VERSION "TTR CAN DBC Tool"

NS_ :

BS_:

BU_: AMS CHARGER DEBUG IMU_FRONT MCU1 MCU2 MCU3 MCU4 VCU

BO_ 32 VCU_MCU_ALL_CONTROL: 12 VCU
 SG_ SYS_EN_CMD : 0|1@1+ (1,0) [0|0] "" MCU1,MCU2,MCU3,MCU4
 SG_ SYS_RESET_CMD : 1|1@1+ (1,0) [0|0] "" MCU1,MCU2,MCU3,MCU4
 SG_ FW_EN_CMD : 2|1@1+ (1,0) [0|0] "" MCU1,MCU2,MCU3,MCU4
 SG_ MTPA_EN_CMD : 3|1@1+ (1,0) [0|0] "" MCU1,MCU2,MCU3,MCU4
 SG_ TE_CMD_MCU1_CMD : 16|16@1+ (0.0488759,-25) [-25|25] "Nm" MCU1,MCU2,MCU3,MCU4
 SG_ TE_CMD_MCU2_CMD : 32|16@1+ (0.0488759,-25) [-25|25] "Nm" MCU1,MCU2,MCU3,MCU4
 SG_ TE_CMD_MCU3_CMD : 48|16@1+ (0.0488759,-25) [-25|25] "Nm" MCU1,MCU2,MCU3,MCU4
 SG_ TE_CMD_MCU4_CMD : 64|16@1+ (0.0488759,-25) [-25|25] "Nm" MCU1,MCU2,MCU3,MCU4
 SG_ CMD_COUNTER : 80|16@1+ (1,0) [0|0] "" MCU1,MCU2,MCU3,MCU4

BO_ 96 CHARGER_AMS_CONTROL: 8 CHARGER
 SG_ BALANCE_EN : 0|1@1+ (1,0) [0|0] "" AMS

BO_ 192 MCU1_STATUS_CORE: 8 MCU1
 SG_ SPEED_FB : 0|16@1+ (0.762951,-25000) [-25000|25000] "RPM" VCU
 SG_ ID_FB : 16|16@1+ (0.00610361,-200) [-200|200] "A" VCU
 SG_ IQ_FB : 32|16@1+ (0.00610361,-200) [-200|200] "A" VCU
 SG_ SYS_READY_ACTIVE : 48|1@1+ (1,0) [0|0] "" VCU
 SG_ SYS_ENABLE_ACTIVE : 49|1@1+ (1,0) [0|0] "" VCU
 SG_ SYS_ACTIVE : 50|1@1+ (1,0) [0|0] "" VCU
 SG_ SYS_LIMIT_ACTIVE : 51|1@1+ (1,0) [0|0] "" VCU
 SG_ FW_ACTIVE : 52|1@1+ (1,0) [0|0] "" VCU
 SG_ RECV_CTRL_CMD_ACTIVE : 53|1@1+ (1,0) [0|0] "" VCU
 SG_ ASC_ACTIVE : 54|1@1+ (1,0) [0|0] "" VCU
 SG_ SYS_FAULT : 56|1@1+ (1,0) [0|0] "" VCU
 SG_ VOLTAGE_SAT_ACTIVE : 57|1@1+ (1,0) [0|0] "" VCU
 SG_ U_OCP_FAULT : 58|1@1+ (1,0) [0|0] "" VCU
 SG_ V_OCP_FAULT : 59|1@1+ (1,0) [0|0] "" VCU
 SG_ W_OCP_FAULT : 60|1@1+ (1,0) [0|0] "" VCU
 SG_ U_GATE_FAULT : 61|1@1+ (1,0) [0|0] "" VCU
 SG_ V_GATE_FAULT : 62|1@1+ (1,0) [0|0] "" VCU
 SG_ W_GATE_FAULT : 63|1@1+ (1,0) [0|0] "" VCU

BO_ 224 MCU2_STATUS_CORE: 8 MCU2
 SG_ SPEED_FB : 0|16@1+ (0.762951,-25000) [-25000|25000] "RPM" VCU
 SG_ ID_FB : 16|16@1+ (0.00610361,-200) [-200|200] "A" VCU
 SG_ IQ_FB : 32|16@1+ (0.00610361,-200) [-200|200] "A" VCU
 SG_ SYS_READY_ACTIVE : 48|1@1+ (1,0) [0|0] "" VCU
 SG_ SYS_ENABLE_ACTIVE : 49|1@1+ (1,0) [0|0] "" VCU
 SG_ SYS_ACTIVE : 50|1@1+ (1,0) [0|0] "" VCU
 SG_ SYS_LIMIT_ACTIVE : 51|1@1+ (1,0) [0|0] "" VCU
 SG_ FW_ACTIVE : 52|1@1+ (1,0) [0|0] "" VCU
 SG_ RECV_CTRL_CMD_ACTIVE : 53|1@1+ (1,0) [0|0] "" VCU
 SG_ ASC_ACTIVE : 54|1@1+ (1,0) [0|0] "" VCU
 SG_ SYS_FAULT : 56|1@1+ (1,0) [0|0] "" VCU
 SG_ VOLTAGE_SAT_ACTIVE : 57|1@1+ (1,0) [0|0] "" VCU
 SG_ U_OCP_FAULT : 58|1@1+ (1,0) [0|0] "" VCU
 SG_ V_OCP_FAULT : 59|1@1+ (1,0) [0|0] "" VCU
 SG_ W_OCP_FAULT : 60|1@1+ (1,0) [0|0] "" VCU
 SG_ U_GATE_FAULT : 61|1@1+ (1,0) [0|0] "" VCU
 SG_ V_GATE_FAULT : 62|1@1+ (1,0) [0|0] "" VCU
 SG_ W_GATE_FAULT : 63|1@1+ (1,0) [0|0] "" VCU

BO_ 256 MCU3_STATUS_CORE: 8 MCU3
 SG_ SPEED_FB : 0|16@1+ (0.762951,-25000) [-25000|25000] "RPM" VCU
 SG_ ID_FB : 16|16@1+ (0.00610361,-200) [-200|200] "A" VCU
 SG_ IQ_FB : 32|16@1+ (0.00610361,-200) [-200|200] "A" VCU
 SG_ SYS_READY_ACTIVE : 48|1@1+ (1,0) [0|0] "" VCU
 SG_ SYS_ENABLE_ACTIVE : 49|1@1+ (1,0) [0|0] "" VCU
 SG_ SYS_ACTIVE : 50|1@1+ (1,0) [0|0] "" VCU
 SG_ SYS_LIMIT_ACTIVE : 51|1@1+ (1,0) [0|0] "" VCU
 SG_ FW_ACTIVE : 52|1@1+ (1,0) [0|0] "" VCU
 SG_ RECV_CTRL_CMD_ACTIVE : 53|1@1+ (1,0) [0|0] "" VCU
 SG_ ASC_ACTIVE : 54|1@1+ (1,0) [0|0] "" VCU
 SG_ SYS_FAULT : 56|1@1+ (1,0) [0|0] "" VCU
 SG_ VOLTAGE_SAT_ACTIVE : 57|1@1+ (1,0) [0|0] "" VCU
 SG_ U_OCP_FAULT : 58|1@1+ (1,0) [0|0] "" VCU
 SG_ V_OCP_FAULT : 59|1@1+ (1,0) [0|0] "" VCU
 SG_ W_OCP_FAULT : 60|1@1+ (1,0) [0|0] "" VCU
 SG_ U_GATE_FAULT : 61|1@1+ (1,0) [0|0] "" VCU
 SG_ V_GATE_FAULT : 62|1@1+ (1,0) [0|0] "" VCU
 SG_ W_GATE_FAULT : 63|1@1+ (1,0) [0|0] "" VCU

BO_ 288 MCU4_STATUS_CORE: 8 MCU4
 SG_ SPEED_FB : 0|16@1+ (0.762951,-25000) [-25000|25000] "RPM" VCU
 SG_ ID_FB : 16|16@1+ (0.00610361,-200) [-200|200] "A" VCU
 SG_ IQ_FB : 32|16@1+ (0.00610361,-200) [-200|200] "A" VCU
 SG_ SYS_READY_ACTIVE : 48|1@1+ (1,0) [0|0] "" VCU
 SG_ SYS_ENABLE_ACTIVE : 49|1@1+ (1,0) [0|0] "" VCU
 SG_ SYS_ACTIVE : 50|1@1+ (1,0) [0|0] "" VCU
 SG_ SYS_LIMIT_ACTIVE : 51|1@1+ (1,0) [0|0] "" VCU
 SG_ FW_ACTIVE : 52|1@1+ (1,0) [0|0] "" VCU
 SG_ RECV_CTRL_CMD_ACTIVE : 53|1@1+ (1,0) [0|0] "" VCU
 SG_ ASC_ACTIVE : 54|1@1+ (1,0) [0|0] "" VCU
 SG_ SYS_FAULT : 56|1@1+ (1,0) [0|0] "" VCU
 SG_ VOLTAGE_SAT_ACTIVE : 57|1@1+ (1,0) [0|0] "" VCU
 SG_ U_OCP_FAULT : 58|1@1+ (1,0) [0|0] "" VCU
 SG_ V_OCP_FAULT : 59|1@1+ (1,0) [0|0] "" VCU
 SG_ W_OCP_FAULT : 60|1@1+ (1,0) [0|0] "" VCU
 SG_ U_GATE_FAULT : 61|1@1+ (1,0) [0|0] "" VCU
 SG_ V_GATE_FAULT : 62|1@1+ (1,0) [0|0] "" VCU
 SG_ W_GATE_FAULT : 63|1@1+ (1,0) [0|0] "" VCU

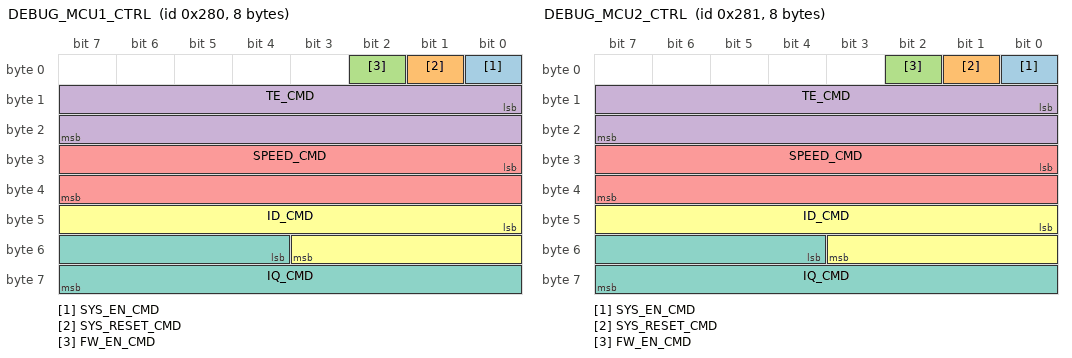
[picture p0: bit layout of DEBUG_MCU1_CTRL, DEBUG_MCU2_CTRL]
BO_ 640 DEBUG_MCU1_CTRL: 8 DEBUG
 SG_ SYS_EN_CMD : 0|1@1+ (1,0) [0|0] "" MCU1
 SG_ SYS_RESET_CMD : 1|1@1+ (1,0) [0|0] "" MCU1
 SG_ FW_EN_CMD : 2|1@1+ (1,0) [0|0] "" MCU1
 SG_ TE_CMD : 8|16@1+ (0.0488759,-25) [-25|25] "Nm" MCU1
 SG_ SPEED_CMD : 24|16@1+ (0.610361,-20000) [-20000|20000] "RPM" MCU1
 SG_ ID_CMD : 40|12@1+ (0.0976801,-200) [-200|200] "A" MCU1
 SG_ IQ_CMD : 52|12@1+ (0.0976801,-200) [-200|200] "A" MCU1

BO_ 641 DEBUG_MCU2_CTRL: 8 DEBUG
 SG_ SYS_EN_CMD : 0|1@1+ (1,0) [0|0] "" MCU2
 SG_ SYS_RESET_CMD : 1|1@1+ (1,0) [0|0] "" MCU2
 SG_ FW_EN_CMD : 2|1@1+ (1,0) [0|0] "" MCU2
 SG_ TE_CMD : 8|16@1+ (0.0488759,-25) [-25|25] "Nm" MCU2
 SG_ SPEED_CMD : 24|16@1+ (0.610361,-20000) [-20000|20000] "RPM" MCU2
 SG_ ID_CMD : 40|12@1+ (0.0976801,-200) [-200|200] "A" MCU2
 SG_ IQ_CMD : 52|12@1+ (0.0976801,-200) [-200|200] "A" MCU2

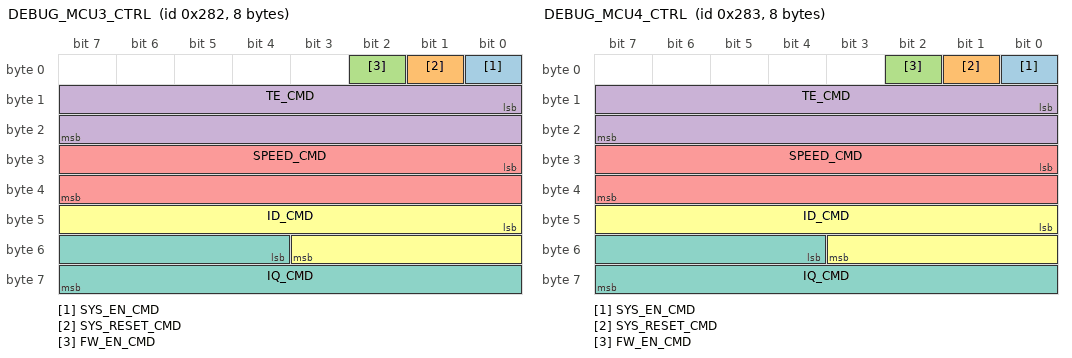
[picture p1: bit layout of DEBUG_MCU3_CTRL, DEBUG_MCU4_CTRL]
BO_ 642 DEBUG_MCU3_CTRL: 8 DEBUG
 SG_ SYS_EN_CMD : 0|1@1+ (1,0) [0|0] "" MCU3
 SG_ SYS_RESET_CMD : 1|1@1+ (1,0) [0|0] "" MCU3
 SG_ FW_EN_CMD : 2|1@1+ (1,0) [0|0] "" MCU3
 SG_ TE_CMD : 8|16@1+ (0.0488759,-25) [-25|25] "Nm" MCU3
 SG_ SPEED_CMD : 24|16@1+ (0.610361,-20000) [-20000|20000] "RPM" MCU3
 SG_ ID_CMD : 40|12@1+ (0.0976801,-200) [-200|200] "A" MCU3
 SG_ IQ_CMD : 52|12@1+ (0.0976801,-200) [-200|200] "A" MCU3

BO_ 643 DEBUG_MCU4_CTRL: 8 DEBUG
 SG_ SYS_EN_CMD : 0|1@1+ (1,0) [0|0] "" MCU4
 SG_ SYS_RESET_CMD : 1|1@1+ (1,0) [0|0] "" MCU4
 SG_ FW_EN_CMD : 2|1@1+ (1,0) [0|0] "" MCU4
 SG_ TE_CMD : 8|16@1+ (0.0488759,-25) [-25|25] "Nm" MCU4
 SG_ SPEED_CMD : 24|16@1+ (0.610361,-20000) [-20000|20000] "RPM" MCU4
 SG_ ID_CMD : 40|12@1+ (0.0976801,-200) [-200|200] "A" MCU4
 SG_ IQ_CMD : 52|12@1+ (0.0976801,-200) [-200|200] "A" MCU4

BO_ 644 DEBUG_MCU1_PARAMETER_CONTROL: 48 DEBUG
 SG_ DIRECTION : 0|1@1+ (1,0) [0|0] "" MCU1
 SG_ MODE : 1|2@1+ (1,0) [0|0] "" MCU1
 SG_ CUR_LOOP_ID_KP : 32|32@1- (1,0) [0|0] "" MCU1
 SG_ CUR_LOOP_ID_KI : 64|32@1- (1,0) [0|0] "" MCU1
 SG_ CUR_LOOP_IQ_KP : 96|32@1- (1,0) [0|0] "" MCU1
 SG_ CUR_LOOP_IQ_KI : 128|32@1- (1,0) [0|0] "" MCU1
 SG_ SPD_LOOP_KP : 160|32@1- (1,0) [0|0] "" MCU1
 SG_ SPD_LOOP_KI : 192|32@1- (1,0) [0|0] "" MCU1
 SG_ FW_KI : 224|32@1- (1,0) [0|0] "" MCU1

BO_ 645 DEBUG_MCU2_PARAMETER_CONTROL: 48 DEBUG
 SG_ DIRECTION : 0|1@1+ (1,0) [0|0] "" MCU2
 SG_ MODE : 1|2@1+ (1,0) [0|0] "" MCU2
 SG_ CUR_LOOP_ID_KP : 32|32@1- (1,0) [0|0] "" MCU2
 SG_ CUR_LOOP_ID_KI : 64|32@1- (1,0) [0|0] "" MCU2
 SG_ CUR_LOOP_IQ_KP : 96|32@1- (1,0) [0|0] "" MCU2
 SG_ CUR_LOOP_IQ_KI : 128|32@1- (1,0) [0|0] "" MCU2
 SG_ SPD_LOOP_KP : 160|32@1- (1,0) [0|0] "" MCU2
 SG_ SPD_LOOP_KI : 192|32@1- (1,0) [0|0] "" MCU2
 SG_ FW_KI : 224|32@1- (1,0) [0|0] "" MCU2

BO_ 646 DEBUG_MCU3_PARAMETER_CONTROL: 48 DEBUG
 SG_ DIRECTION : 0|1@1+ (1,0) [0|0] "" MCU3
 SG_ MODE : 1|2@1+ (1,0) [0|0] "" MCU3
 SG_ CUR_LOOP_ID_KP : 32|32@1- (1,0) [0|0] "" MCU3
 SG_ CUR_LOOP_ID_KI : 64|32@1- (1,0) [0|0] "" MCU3
 SG_ CUR_LOOP_IQ_KP : 96|32@1- (1,0) [0|0] "" MCU3
 SG_ CUR_LOOP_IQ_KI : 128|32@1- (1,0) [0|0] "" MCU3
 SG_ SPD_LOOP_KP : 160|32@1- (1,0) [0|0] "" MCU3
 SG_ SPD_LOOP_KI : 192|32@1- (1,0) [0|0] "" MCU3
 SG_ FW_KI : 224|32@1- (1,0) [0|0] "" MCU3

BO_ 647 DEBUG_MCU4_PARAMETER_CONTROL: 48 DEBUG
 SG_ DIRECTION : 0|1@1+ (1,0) [0|0] "" MCU4
 SG_ MODE : 1|2@1+ (1,0) [0|0] "" MCU4
 SG_ CUR_LOOP_ID_KP : 32|32@1- (1,0) [0|0] "" MCU4
 SG_ CUR_LOOP_ID_KI : 64|32@1- (1,0) [0|0] "" MCU4
 SG_ CUR_LOOP_IQ_KP : 96|32@1- (1,0) [0|0] "" MCU4
 SG_ CUR_LOOP_IQ_KI : 128|32@1- (1,0) [0|0] "" MCU4
 SG_ SPD_LOOP_KP : 160|32@1- (1,0) [0|0] "" MCU4
 SG_ SPD_LOOP_KI : 192|32@1- (1,0) [0|0] "" MCU4
 SG_ FW_KI : 224|32@1- (1,0) [0|0] "" MCU4

BO_ 648 DEBUG_MCU1_PARAMETER_LIMIT: 48 DEBUG
 SG_ CURRENT_LINE_LIMIT : 0|32@1- (1,0) [0|0] "" MCU1
 SG_ CURRENT_ID_LIMIT : 32|32@1- (1,0) [0|0] "" MCU1
 SG_ FW_ID_LIMIT : 64|32@1- (1,0) [0|0] "" MCU1
 SG_ TORQUE_LIMIT : 96|32@1- (1,0) [0|0] "" MCU1
 SG_ OVER_VOLTAGE_LIMIT : 128|32@1- (1,0) [0|0] "" MCU1
 SG_ UNDER_VOLTAGE_LIMIT : 160|32@1- (1,0) [0|0] "" MCU1
 SG_ VDC_REGEN_BLOCK_SOFT : 192|32@1- (1,0) [0|0] "" MCU1
 SG_ VDC_REGEN_BLOCK_HARD : 224|32@1- (1,0) [0|0] "" MCU1
 SG_ MOTOR_TEMP_LIMIT : 256|32@1- (1,0) [0|0] "" MCU1
 SG_ GATE_TEMP_LIMIT : 288|32@1- (1,0) [0|0] "" MCU1
 SG_ VQ_LIMIT : 320|32@1- (1,0) [0|0] "" MCU1
 SG_ MODULATION_LIMIT : 352|32@1- (1,0) [0|0] "" MCU1

BO_ 649 DEBUG_MCU2_PARAMETER_LIMIT: 48 DEBUG
 SG_ CURRENT_LINE_LIMIT : 0|32@1- (1,0) [0|0] "" MCU2
 SG_ CURRENT_ID_LIMIT : 32|32@1- (1,0) [0|0] "" MCU2
 SG_ FW_ID_LIMIT : 64|32@1- (1,0) [0|0] "" MCU2
 SG_ TORQUE_LIMIT : 96|32@1- (1,0) [0|0] "" MCU2
 SG_ OVER_VOLTAGE_LIMIT : 128|32@1- (1,0) [0|0] "" MCU2
 SG_ UNDER_VOLTAGE_LIMIT : 160|32@1- (1,0) [0|0] "" MCU2
 SG_ VDC_REGEN_BLOCK_SOFT : 192|32@1- (1,0) [0|0] "" MCU2
 SG_ VDC_REGEN_BLOCK_HARD : 224|32@1- (1,0) [0|0] "" MCU2
 SG_ MOTOR_TEMP_LIMIT : 256|32@1- (1,0) [0|0] "" MCU2
 SG_ GATE_TEMP_LIMIT : 288|32@1- (1,0) [0|0] "" MCU2
 SG_ VQ_LIMIT : 320|32@1- (1,0) [0|0] "" MCU2
 SG_ MODULATION_LIMIT : 352|32@1- (1,0) [0|0] "" MCU2

BO_ 650 DEBUG_MCU3_PARAMETER_LIMIT: 48 DEBUG
 SG_ CURRENT_LINE_LIMIT : 0|32@1- (1,0) [0|0] "" MCU3
 SG_ CURRENT_ID_LIMIT : 32|32@1- (1,0) [0|0] "" MCU3
 SG_ FW_ID_LIMIT : 64|32@1- (1,0) [0|0] "" MCU3
 SG_ TORQUE_LIMIT : 96|32@1- (1,0) [0|0] "" MCU3
 SG_ OVER_VOLTAGE_LIMIT : 128|32@1- (1,0) [0|0] "" MCU3
 SG_ UNDER_VOLTAGE_LIMIT : 160|32@1- (1,0) [0|0] "" MCU3
 SG_ VDC_REGEN_BLOCK_SOFT : 192|32@1- (1,0) [0|0] "" MCU3
 SG_ VDC_REGEN_BLOCK_HARD : 224|32@1- (1,0) [0|0] "" MCU3
 SG_ MOTOR_TEMP_LIMIT : 256|32@1- (1,0) [0|0] "" MCU3
 SG_ GATE_TEMP_LIMIT : 288|32@1- (1,0) [0|0] "" MCU3
 SG_ VQ_LIMIT : 320|32@1- (1,0) [0|0] "" MCU3
 SG_ MODULATION_LIMIT : 352|32@1- (1,0) [0|0] "" MCU3

BO_ 651 DEBUG_MCU4_PARAMETER_LIMIT: 48 DEBUG
 SG_ CURRENT_LINE_LIMIT : 0|32@1- (1,0) [0|0] "" MCU4
 SG_ CURRENT_ID_LIMIT : 32|32@1- (1,0) [0|0] "" MCU4
 SG_ FW_ID_LIMIT : 64|32@1- (1,0) [0|0] "" MCU4
 SG_ TORQUE_LIMIT : 96|32@1- (1,0) [0|0] "" MCU4
 SG_ OVER_VOLTAGE_LIMIT : 128|32@1- (1,0) [0|0] "" MCU4
 SG_ UNDER_VOLTAGE_LIMIT : 160|32@1- (1,0) [0|0] "" MCU4
 SG_ VDC_REGEN_BLOCK_SOFT : 192|32@1- (1,0) [0|0] "" MCU4
 SG_ VDC_REGEN_BLOCK_HARD : 224|32@1- (1,0) [0|0] "" MCU4
 SG_ MOTOR_TEMP_LIMIT : 256|32@1- (1,0) [0|0] "" MCU4
 SG_ GATE_TEMP_LIMIT : 288|32@1- (1,0) [0|0] "" MCU4
 SG_ VQ_LIMIT : 320|32@1- (1,0) [0|0] "" MCU4
 SG_ MODULATION_LIMIT : 352|32@1- (1,0) [0|0] "" MCU4

BO_ 652 DEBUG_MCU1_PARAMETER_OFFSET: 48 DEBUG
 SG_ VDC_OFFSET : 0|32@1- (1,0) [0|0] "" MCU1
 SG_ MOTOR_TEMP_OFFSET : 32|32@1- (1,0) [0|0] "" MCU1
 SG_ U_PHASE_TEMP_OFFSET : 64|32@1- (1,0) [0|0] "" MCU1
 SG_ V_PHASE_TEMP_OFFSET : 96|32@1- (1,0) [0|0] "" MCU1
 SG_ W_PHASE_TEMP_OFFSET : 128|32@1- (1,0) [0|0] "" MCU1

BO_ 653 DEBUG_MCU2_PARAMETER_OFFSET: 48 DEBUG
 SG_ VDC_OFFSET : 0|32@1- (1,0) [0|0] "" MCU2
 SG_ MOTOR_TEMP_OFFSET : 32|32@1- (1,0) [0|0] "" MCU2
 SG_ U_PHASE_TEMP_OFFSET : 64|32@1- (1,0) [0|0] "" MCU2
 SG_ V_PHASE_TEMP_OFFSET : 96|32@1- (1,0) [0|0] "" MCU2
 SG_ W_PHASE_TEMP_OFFSET : 128|32@1- (1,0) [0|0] "" MCU2

BO_ 654 DEBUG_MCU3_PARAMETER_OFFSET: 48 DEBUG
 SG_ VDC_OFFSET : 0|32@1- (1,0) [0|0] "" MCU3
 SG_ MOTOR_TEMP_OFFSET : 32|32@1- (1,0) [0|0] "" MCU3
 SG_ U_PHASE_TEMP_OFFSET : 64|32@1- (1,0) [0|0] "" MCU3
 SG_ V_PHASE_TEMP_OFFSET : 96|32@1- (1,0) [0|0] "" MCU3
 SG_ W_PHASE_TEMP_OFFSET : 128|32@1- (1,0) [0|0] "" MCU3

BO_ 655 DEBUG_MCU4_PARAMETER_OFFSET: 48 DEBUG
 SG_ VDC_OFFSET : 0|32@1- (1,0) [0|0] "" MCU4
 SG_ MOTOR_TEMP_OFFSET : 32|32@1- (1,0) [0|0] "" MCU4
 SG_ U_PHASE_TEMP_OFFSET : 64|32@1- (1,0) [0|0] "" MCU4
 SG_ V_PHASE_TEMP_OFFSET : 96|32@1- (1,0) [0|0] "" MCU4
 SG_ W_PHASE_TEMP_OFFSET : 128|32@1- (1,0) [0|0] "" MCU4

BO_ 656 DEBUG_MCU1_PARAMETER_CTRL_CMD: 1 DEBUG
 SG_ SAVE_CMD : 0|1@1+ (1,0) [0|0] "" MCU1

BO_ 657 DEBUG_MCU2_PARAMETER_CTRL_CMD: 1 DEBUG
 SG_ SAVE_CMD : 0|1@1+ (1,0) [0|0] "" MCU2

BO_ 658 DEBUG_MCU3_PARAMETER_CTRL_CMD: 1 DEBUG
 SG_ SAVE_CMD : 0|1@1+ (1,0) [0|0] "" MCU3

BO_ 659 DEBUG_MCU4_PARAMETER_CTRL_CMD: 1 DEBUG
 SG_ SAVE_CMD : 0|1@1+ (1,0) [0|0] "" MCU4

BO_ 660 DEBUG_MCU1_PARAMETER_SLEW_RATE: 48 DEBUG
 SG_ TORQUE_SLEW_POS_NM_PER_S : 0|32@1- (1,0) [0|0] "" MCU1
 SG_ TORQUE_SLEW_NEG_NM_PER_S : 32|32@1- (1,0) [0|0] "" MCU1
 SG_ SPEED_SLEW_POS_RPM_PER_S : 64|32@1- (1,0) [0|0] "" MCU1
 SG_ SPEED_SLEW_NEG_RPM_PER_S : 96|32@1- (1,0) [0|0] "" MCU1
 SG_ ID_MTPA_ATTACK_SLEW_A_PER_S : 128|32@1- (1,0) [0|0] "" MCU1
 SG_ ID_MTPA_RELEASE_SLEW_A_PER_S : 160|32@1- (1,0) [0|0] "" MCU1
 SG_ ID_FW_ATTACK_SLEW_A_PER_S : 192|32@1- (1,0) [0|0] "" MCU1
 SG_ ID_FW_RELEASE_SLEW_A_PER_S : 224|32@1- (1,0) [0|0] "" MCU1

BO_ 661 DEBUG_MCU2_PARAMETER_SLEW_RATE: 48 DEBUG
 SG_ TORQUE_SLEW_POS_NM_PER_S : 0|32@1- (1,0) [0|0] "" MCU2
 SG_ TORQUE_SLEW_NEG_NM_PER_S : 32|32@1- (1,0) [0|0] "" MCU2
 SG_ SPEED_SLEW_POS_RPM_PER_S : 64|32@1- (1,0) [0|0] "" MCU2
 SG_ SPEED_SLEW_NEG_RPM_PER_S : 96|32@1- (1,0) [0|0] "" MCU2
 SG_ ID_MTPA_ATTACK_SLEW_A_PER_S : 128|32@1- (1,0) [0|0] "" MCU2
 SG_ ID_MTPA_RELEASE_SLEW_A_PER_S : 160|32@1- (1,0) [0|0] "" MCU2
 SG_ ID_FW_ATTACK_SLEW_A_PER_S : 192|32@1- (1,0) [0|0] "" MCU2
 SG_ ID_FW_RELEASE_SLEW_A_PER_S : 224|32@1- (1,0) [0|0] "" MCU2

BO_ 662 DEBUG_MCU3_PARAMETER_SLEW_RATE: 48 DEBUG
 SG_ TORQUE_SLEW_POS_NM_PER_S : 0|32@1- (1,0) [0|0] "" MCU3
 SG_ TORQUE_SLEW_NEG_NM_PER_S : 32|32@1- (1,0) [0|0] "" MCU3
 SG_ SPEED_SLEW_POS_RPM_PER_S : 64|32@1- (1,0) [0|0] "" MCU3
 SG_ SPEED_SLEW_NEG_RPM_PER_S : 96|32@1- (1,0) [0|0] "" MCU3
 SG_ ID_MTPA_ATTACK_SLEW_A_PER_S : 128|32@1- (1,0) [0|0] "" MCU3
 SG_ ID_MTPA_RELEASE_SLEW_A_PER_S : 160|32@1- (1,0) [0|0] "" MCU3
 SG_ ID_FW_ATTACK_SLEW_A_PER_S : 192|32@1- (1,0) [0|0] "" MCU3
 SG_ ID_FW_RELEASE_SLEW_A_PER_S : 224|32@1- (1,0) [0|0] "" MCU3

BO_ 663 DEBUG_MCU4_PARAMETER_SLEW_RATE: 48 DEBUG
 SG_ TORQUE_SLEW_POS_NM_PER_S : 0|32@1- (1,0) [0|0] "" MCU4
 SG_ TORQUE_SLEW_NEG_NM_PER_S : 32|32@1- (1,0) [0|0] "" MCU4
 SG_ SPEED_SLEW_POS_RPM_PER_S : 64|32@1- (1,0) [0|0] "" MCU4
 SG_ SPEED_SLEW_NEG_RPM_PER_S : 96|32@1- (1,0) [0|0] "" MCU4
 SG_ ID_MTPA_ATTACK_SLEW_A_PER_S : 128|32@1- (1,0) [0|0] "" MCU4
 SG_ ID_MTPA_RELEASE_SLEW_A_PER_S : 160|32@1- (1,0) [0|0] "" MCU4
 SG_ ID_FW_ATTACK_SLEW_A_PER_S : 192|32@1- (1,0) [0|0] "" MCU4
 SG_ ID_FW_RELEASE_SLEW_A_PER_S : 224|32@1- (1,0) [0|0] "" MCU4

BO_ 664 DEBUG_DTU_CONTROL: 8 DEBUG
 SG_ ENABLE_DEBUG : 0|1@1+ (1,0) [0|0] "" VCU

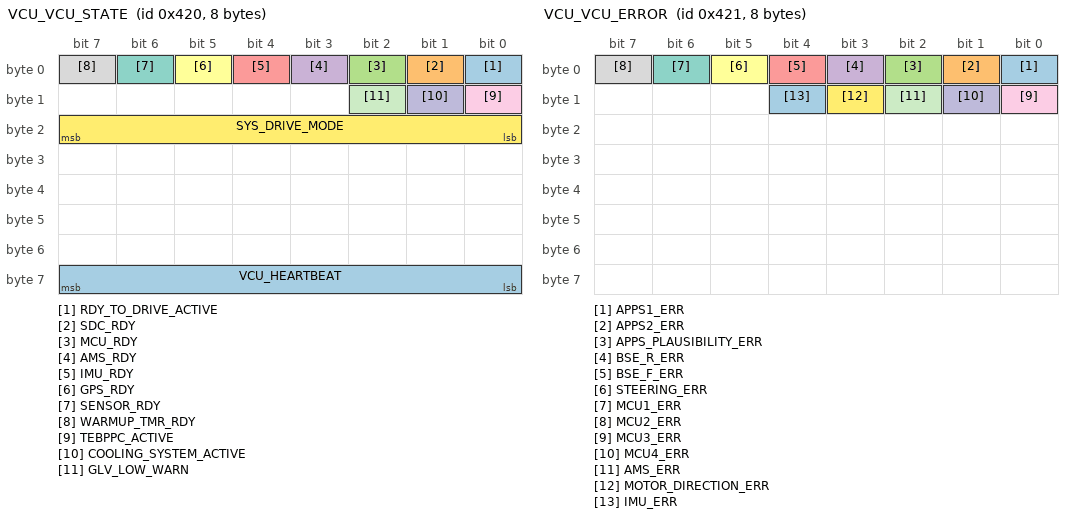
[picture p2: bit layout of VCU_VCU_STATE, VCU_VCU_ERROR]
BO_ 1056 VCU_VCU_STATE: 8 VCU
 SG_ RDY_TO_DRIVE_ACTIVE : 0|1@1+ (1,0) [0|0] "" Vector__XXX
 SG_ SDC_RDY : 1|1@1+ (1,0) [0|0] "" Vector__XXX
 SG_ MCU_RDY : 2|1@1+ (1,0) [0|0] "" Vector__XXX
 SG_ AMS_RDY : 3|1@1+ (1,0) [0|0] "" Vector__XXX
 SG_ IMU_RDY : 4|1@1+ (1,0) [0|0] "" Vector__XXX
 SG_ GPS_RDY : 5|1@1+ (1,0) [0|0] "" Vector__XXX
 SG_ SENSOR_RDY : 6|1@1+ (1,0) [0|0] "" Vector__XXX
 SG_ WARMUP_TMR_RDY : 7|1@1+ (1,0) [0|0] "" Vector__XXX
 SG_ TEBPPC_ACTIVE : 8|1@1+ (1,0) [0|0] "" Vector__XXX
 SG_ COOLING_SYSTEM_ACTIVE : 9|1@1+ (1,0) [0|0] "" Vector__XXX
 SG_ GLV_LOW_WARN : 10|1@1+ (1,0) [0|0] "" Vector__XXX
 SG_ SYS_DRIVE_MODE : 16|8@1+ (1,0) [0|0] "" Vector__XXX
 SG_ VCU_HEARTBEAT : 56|8@1+ (1,0) [0|0] "" Vector__XXX

BO_ 1057 VCU_VCU_ERROR: 8 VCU
 SG_ APPS1_ERR : 0|1@1+ (1,0) [0|0] "" Vector__XXX
 SG_ APPS2_ERR : 1|1@1+ (1,0) [0|0] "" Vector__XXX
 SG_ APPS_PLAUSIBILITY_ERR : 2|1@1+ (1,0) [0|0] "" Vector__XXX
 SG_ BSE_R_ERR : 3|1@1+ (1,0) [0|0] "" Vector__XXX
 SG_ BSE_F_ERR : 4|1@1+ (1,0) [0|0] "" Vector__XXX
 SG_ STEERING_ERR : 5|1@1+ (1,0) [0|0] "" Vector__XXX
 SG_ MCU1_ERR : 6|1@1+ (1,0) [0|0] "" Vector__XXX
 SG_ MCU2_ERR : 7|1@1+ (1,0) [0|0] "" Vector__XXX
 SG_ MCU3_ERR : 8|1@1+ (1,0) [0|0] "" Vector__XXX
 SG_ MCU4_ERR : 9|1@1+ (1,0) [0|0] "" Vector__XXX
 SG_ AMS_ERR : 10|1@1+ (1,0) [0|0] "" Vector__XXX
 SG_ MOTOR_DIRECTION_ERR : 11|1@1+ (1,0) [0|0] "" Vector__XXX
 SG_ IMU_ERR : 12|1@1+ (1,0) [0|0] "" Vector__XXX

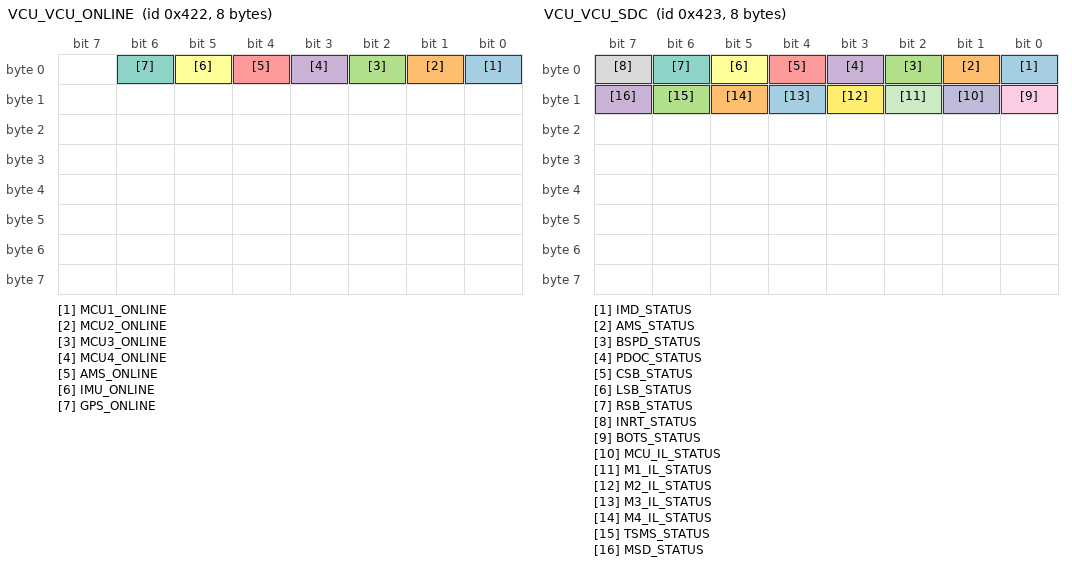
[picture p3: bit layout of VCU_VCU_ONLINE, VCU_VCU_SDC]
BO_ 1058 VCU_VCU_ONLINE: 8 VCU
 SG_ MCU1_ONLINE : 0|1@1+ (1,0) [0|0] "" Vector__XXX
 SG_ MCU2_ONLINE : 1|1@1+ (1,0) [0|0] "" Vector__XXX
 SG_ MCU3_ONLINE : 2|1@1+ (1,0) [0|0] "" Vector__XXX
 SG_ MCU4_ONLINE : 3|1@1+ (1,0) [0|0] "" Vector__XXX
 SG_ AMS_ONLINE : 4|1@1+ (1,0) [0|0] "" Vector__XXX
 SG_ IMU_ONLINE : 5|1@1+ (1,0) [0|0] "" Vector__XXX
 SG_ GPS_ONLINE : 6|1@1+ (1,0) [0|0] "" Vector__XXX

BO_ 1059 VCU_VCU_SDC: 8 VCU
 SG_ IMD_STATUS : 0|1@1+ (1,0) [0|0] "" Vector__XXX
 SG_ AMS_STATUS : 1|1@1+ (1,0) [0|0] "" Vector__XXX
 SG_ BSPD_STATUS : 2|1@1+ (1,0) [0|0] "" Vector__XXX
 SG_ PDOC_STATUS : 3|1@1+ (1,0) [0|0] "" Vector__XXX
 SG_ CSB_STATUS : 4|1@1+ (1,0) [0|0] "" Vector__XXX
 SG_ LSB_STATUS : 5|1@1+ (1,0) [0|0] "" Vector__XXX
 SG_ RSB_STATUS : 6|1@1+ (1,0) [0|0] "" Vector__XXX
 SG_ INRT_STATUS : 7|1@1+ (1,0) [0|0] "" Vector__XXX
 SG_ BOTS_STATUS : 8|1@1+ (1,0) [0|0] "" Vector__XXX
 SG_ MCU_IL_STATUS : 9|1@1+ (1,0) [0|0] "" Vector__XXX
 SG_ M1_IL_STATUS : 10|1@1+ (1,0) [0|0] "" Vector__XXX
 SG_ M2_IL_STATUS : 11|1@1+ (1,0) [0|0] "" Vector__XXX
 SG_ M3_IL_STATUS : 12|1@1+ (1,0) [0|0] "" Vector__XXX
 SG_ M4_IL_STATUS : 13|1@1+ (1,0) [0|0] "" Vector__XXX
 SG_ TSMS_STATUS : 14|1@1+ (1,0) [0|0] "" Vector__XXX
 SG_ MSD_STATUS : 15|1@1+ (1,0) [0|0] "" Vector__XXX

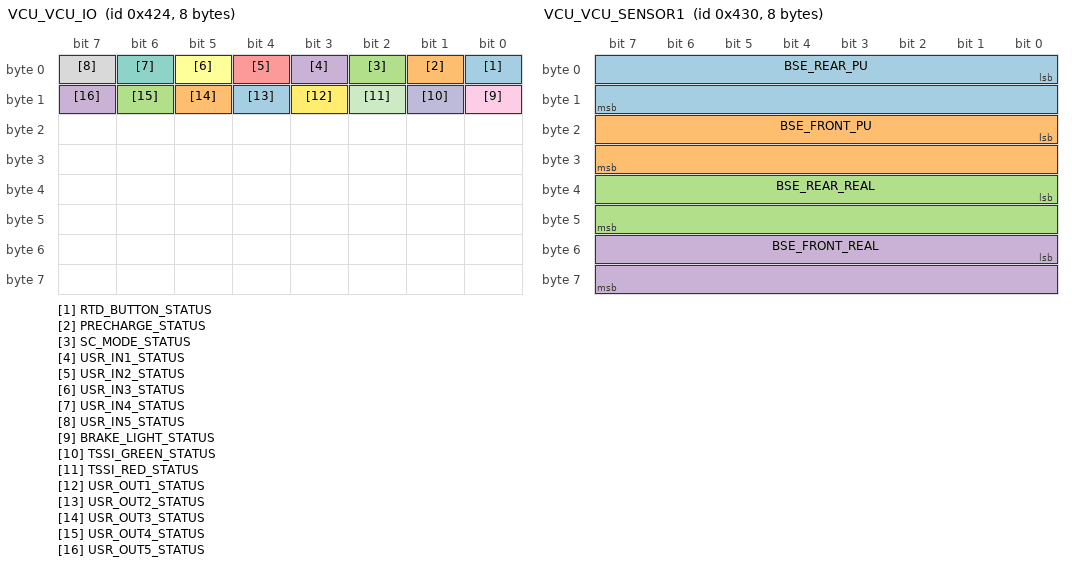
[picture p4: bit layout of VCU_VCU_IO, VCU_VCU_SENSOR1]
BO_ 1060 VCU_VCU_IO: 8 VCU
 SG_ RTD_BUTTON_STATUS : 0|1@1+ (1,0) [0|0] "" Vector__XXX
 SG_ PRECHARGE_STATUS : 1|1@1+ (1,0) [0|0] "" Vector__XXX
 SG_ SC_MODE_STATUS : 2|1@1+ (1,0) [0|0] "" Vector__XXX
 SG_ USR_IN1_STATUS : 3|1@1+ (1,0) [0|0] "" Vector__XXX
 SG_ USR_IN2_STATUS : 4|1@1+ (1,0) [0|0] "" Vector__XXX
 SG_ USR_IN3_STATUS : 5|1@1+ (1,0) [0|0] "" Vector__XXX
 SG_ USR_IN4_STATUS : 6|1@1+ (1,0) [0|0] "" Vector__XXX
 SG_ USR_IN5_STATUS : 7|1@1+ (1,0) [0|0] "" Vector__XXX
 SG_ BRAKE_LIGHT_STATUS : 8|1@1+ (1,0) [0|0] "" Vector__XXX
 SG_ TSSI_GREEN_STATUS : 9|1@1+ (1,0) [0|0] "" Vector__XXX
 SG_ TSSI_RED_STATUS : 10|1@1+ (1,0) [0|0] "" Vector__XXX
 SG_ USR_OUT1_STATUS : 11|1@1+ (1,0) [0|0] "" Vector__XXX
 SG_ USR_OUT2_STATUS : 12|1@1+ (1,0) [0|0] "" Vector__XXX
 SG_ USR_OUT3_STATUS : 13|1@1+ (1,0) [0|0] "" Vector__XXX
 SG_ USR_OUT4_STATUS : 14|1@1+ (1,0) [0|0] "" Vector__XXX
 SG_ USR_OUT5_STATUS : 15|1@1+ (1,0) [0|0] "" Vector__XXX

BO_ 1061 VCU_VCU_CPU_TASK_STATUS: 16 VCU
 SG_ MAIN_TASK_CAL_AVG_US : 0|16@1+ (1,0) [0|0] "us" Vector__XXX
 SG_ MAIN_TASK_CAL_MAX_US : 16|16@1+ (1,0) [0|0] "us" Vector__XXX
 SG_ MAIN_TASK_PERIOD_AVG_MS : 32|16@1+ (0.015259,0) [0|1000] "ms" Vector__XXX
 SG_ MAIN_TASK_PERIOD_MAX_MS : 48|16@1+ (0.015259,0) [0|1000] "ms" Vector__XXX
 SG_ DYC_TASK_CAL_AVG_US : 64|16@1+ (1,0) [0|0] "us" Vector__XXX
 SG_ DYC_TASK_CAL_MAX_US : 80|16@1+ (1,0) [0|0] "us" Vector__XXX
 SG_ DYC_TASK_PERIOD_AVG_MS : 96|16@1+ (0.015259,0) [0|1000] "ms" Vector__XXX
 SG_ DYC_TASK_PERIOD_MAX_MS : 112|16@1+ (0.0015259,0) [0|1000] "ms" Vector__XXX

BO_ 1062 VCU_VCU_SYSTEM_STATUS: 16 VCU
 SG_ GLV_VOLTAGE : 0|16@1+ (0.000457666,0) [0|0] "V" Vector__XXX
 SG_ GLV_CURRENT : 16|16@1+ (0.000457666,0) [0|0] "A" Vector__XXX
 SG_ GLV_SOC : 48|16@1+ (0.0015259,0) [0|100] "A" Vector__XXX
 SG_ REGEN_TORQUE_LIMIT : 64|12@1+ (0.00976801,0) [0|40] "" Vector__XXX

BO_ 1063 VCU_VCU_DIAG: 12 VCU
 SG_ RTD_EXIT_REASON : 0|18@1+ (1,0) [0|0] "" Vector__XXX
 SG_ RTD_EXIT_COUNT : 24|8@1+ (1,0) [0|0] "" Vector__XXX
 SG_ REGEN_BLOCK_REASON : 32|8@1+ (1,0) [0|0] "" Vector__XXX
 SG_ REGEN_LOW_SPEED_FALLBACK : 40|1@1+ (1,0) [0|0] "" Vector__XXX
 SG_ CONTROL_TIMEOUT_COUNT : 48|8@1+ (1,0) [0|0] "" Vector__XXX
 SG_ CONTROL_TIMEOUT_MAX_AGE_MS : 56|8@1+ (1,0) [0|0] "" Vector__XXX

BO_ 1066 VCU_VCU_MCU_CAN_STATUS: 32 VCU
 SG_ MCU1_STATUS0_RECV_MISS_CONSEC_AVG : 0|16@1+ (0.000762951,0) [0|50] "" Vector__XXX
 SG_ MCU1_STATUS0_RECV_MISS_CONSEC_MAX : 16|16@1+ (1,0) [0|0] "" Vector__XXX
 SG_ MCU1_STATUS0_RECV_GAP_MS_AVG : 32|16@1+ (0.0015259,0) [0|100] "ms" Vector__XXX
 SG_ MCU1_STATUS0_RECV_GAP_MS_MAX : 48|16@1+ (0.0015259,0) [0|100] "ms" Vector__XXX
 SG_ MCU2_STATUS0_RECV_MISS_CONSEC_AVG : 64|16@1+ (0.000762951,0) [0|50] "" Vector__XXX
 SG_ MCU2_STATUS0_RECV_MISS_CONSEC_MAX : 80|16@1+ (1,0) [0|0] "" Vector__XXX
 SG_ MCU2_STATUS0_RECV_GAP_MS_AVG : 96|16@1+ (0.0015259,0) [0|100] "ms" Vector__XXX
 SG_ MCU2_STATUS0_RECV_GAP_MS_MAX : 112|16@1+ (0.0015259,0) [0|100] "ms" Vector__XXX
 SG_ MCU3_STATUS0_RECV_MISS_CONSEC_AVG : 128|16@1+ (0.000762951,0) [0|50] "" Vector__XXX
 SG_ MCU3_STATUS0_RECV_MISS_CONSEC_MAX : 144|16@1+ (1,0) [0|0] "" Vector__XXX
 SG_ MCU3_STATUS0_RECV_GAP_MS_AVG : 160|16@1+ (0.0015259,0) [0|100] "ms" Vector__XXX
 SG_ MCU3_STATUS0_RECV_GAP_MS_MAX : 176|16@1+ (0.0015259,0) [0|100] "ms" Vector__XXX
 SG_ MCU4_STATUS0_RECV_MISS_CONSEC_AVG : 192|16@1+ (0.000762951,0) [0|50] "" Vector__XXX
 SG_ MCU4_STATUS0_RECV_MISS_CONSEC_MAX : 208|16@1+ (1,0) [0|0] "" Vector__XXX
 SG_ MCU4_STATUS0_RECV_GAP_MS_AVG : 224|16@1+ (0.0015259,0) [0|100] "ms" Vector__XXX
 SG_ MCU4_STATUS0_RECV_GAP_MS_MAX : 240|16@1+ (0.0015259,0) [0|100] "ms" Vector__XXX

BO_ 1067 VCU_VCU_DYC_STATUS: 48 VCU
 SG_ DYC_FAULT_VX : 0|1@1+ (1,0) [0|0] "" Vector__XXX
 SG_ DYC_FAULT_IMU : 1|1@1+ (1,0) [0|0] "" Vector__XXX
 SG_ DYC_FAULT_STEERING : 2|1@1+ (1,0) [0|0] "" Vector__XXX
 SG_ DYC_FAULT_YAW_RATE : 3|1@1+ (1,0) [0|0] "" Vector__XXX
 SG_ DYC_FAULT_AY : 4|1@1+ (1,0) [0|0] "" Vector__XXX
 SG_ DYC_FAULT_AY_YAWRATE : 5|1@1+ (1,0) [0|0] "" Vector__XXX
 SG_ DYC_IMU_SOURCE : 8|8@1+ (1,0) [0|0] "" Vector__XXX
 SG_ DYC_VX_VALID : 16|1@1+ (1,0) [0|0] "" Vector__XXX
 SG_ DYC_LOW_SPEED : 17|1@1+ (1,0) [0|0] "" Vector__XXX
 SG_ DYC_ALLOWED : 18|1@1+ (1,0) [0|0] "" Vector__XXX
 SG_ DYC_CONTROL_ACTIVE : 19|1@1+ (1,0) [0|0] "" Vector__XXX
 SG_ DYC_ALLOCATOR_SATURATED : 20|1@1+ (1,0) [0|0] "" Vector__XXX
 SG_ DYC_FORWARD_MOTION : 21|1@1+ (1,0) [0|0] "" Vector__XXX
 SG_ DYC_ZERO_THROTTLE : 22|1@1+ (1,0) [0|0] "" Vector__XXX
 SG_ DYC_NEGATIVE_TORQUE_ACTIVE : 23|1@1+ (1,0) [0|0] "" Vector__XXX
 SG_ DYC_PID_ENABLE_FADE : 24|8@1+ (0.00392157,0) [0|1] "" Vector__XXX
 SG_ DYC_ACCEL_CG_X_MPS2 : 32|16@1+ (0.000915541,-30) [-30|30] "m/s^2" Vector__XXX
 SG_ DYC_ACCEL_CG_Y_MPS2 : 48|16@1+ (0.000915541,-30) [-30|30] "m/s^2" Vector__XXX
 SG_ DYC_STEER_EQ_RAD : 64|16@1+ (0.0000958267,-3.14) [-3.14|3.14] "rad" Vector__XXX
 SG_ DYC_STEER_LEFT_RAD : 80|16@1+ (0.0000479133,-1.57) [-1.57|1.57] "rad" Vector__XXX
 SG_ DYC_STEER_RIGHT_RAD : 96|16@1+ (0.0000479133,-1.57) [-1.57|1.57] "rad" Vector__XXX
 SG_ DYC_YAW_RATE_REF_FILT_RADPS : 112|16@1+ (0.000183108,-6) [-6|6] "rad/s" Vector__XXX
 SG_ DYC_YAW_RATE_REF_RAW_RADPS : 128|16@1+ (0.000183108,-6) [-6|6] "rad/s" Vector__XXX
 SG_ DYC_YAW_ERROR_RADPS : 144|16@1+ (0.000183108,-6) [-6|6] "rad/s" Vector__XXX
 SG_ DYC_MZ_CMD_NM : 160|16@1+ (0.030518,-1000) [-1000|1000] "Nm" Vector__XXX
 SG_ DYC_APPLIED_MZ_NM : 176|16@1+ (0.030518,-1000) [-1000|1000] "Nm" Vector__XXX
 SG_ DYC_BASE_TORQUE_SUM_NM : 192|16@1+ (0.0015259,0) [0|100] "Nm" Vector__XXX
 SG_ DYC_WHEEL_SPEED_AVG_MPS : 208|16@1+ (0.00137331,0) [0|90] "m/s" Vector__XXX
 SG_ DYC_TORQUE_DELTA_FL_NM : 224|16@1+ (0.000915541,-30) [-30|30] "Nm" Vector__XXX
 SG_ DYC_TORQUE_DELTA_FR_NM : 240|16@1+ (0.000915541,-30) [-30|30] "Nm" Vector__XXX
 SG_ DYC_TORQUE_DELTA_RL_NM : 256|16@1+ (0.00122072,-40) [-40|40] "Nm" Vector__XXX
 SG_ DYC_TORQUE_DELTA_RR_NM : 272|16@1+ (0.00122072,-40) [-40|40] "Nm" Vector__XXX
 SG_ DYC_TORQUE_FL_NM : 288|16@1+ (0.000915541,-30) [-30|30] "Nm" Vector__XXX
 SG_ DYC_TORQUE_FR_NM : 304|16@1+ (0.000915541,-30) [-30|30] "Nm" Vector__XXX
 SG_ DYC_TORQUE_RL_NM : 320|16@1+ (0.00122072,-40) [-40|40] "Nm" Vector__XXX
 SG_ DYC_TORQUE_RR_NM : 336|16@1+ (0.00122072,-40) [-40|40] "Nm" Vector__XXX

BO_ 1071 VCU_VCU_MCU_STATUS: 32 VCU
 SG_ M1_TEMPERATURE : 0|12@1+ (0.0537241,-20) [-20|200] "C" Vector__XXX
 SG_ M2_TEMPERATURE : 12|12@1+ (0.0537241,-20) [-20|200] "C" Vector__XXX
 SG_ M3_TEMPERATURE : 24|12@1+ (0.0537241,-20) [-20|200] "C" Vector__XXX
 SG_ M4_TEMPERATURE : 36|12@1+ (0.0537241,-20) [-20|200] "C" Vector__XXX
 SG_ INV1_GATE_U_TEMPERATURE : 48|12@1+ (0.0537241,-20) [-20|200] "C" Vector__XXX
 SG_ INV1_GATE_V_TEMPERATURE : 60|12@1+ (0.0537241,-20) [-20|200] "C" Vector__XXX
 SG_ INV1_GATE_W_TEMPERATURE : 72|12@1+ (0.0537241,-20) [-20|200] "C" Vector__XXX
 SG_ INV2_GATE_U_TEMPERATURE : 84|12@1+ (0.0537241,-20) [-20|200] "C" Vector__XXX
 SG_ INV2_GATE_V_TEMPERATURE : 96|12@1+ (0.0537241,-20) [-20|200] "C" Vector__XXX
 SG_ INV2_GATE_W_TEMPERATURE : 108|12@1+ (0.0537241,-20) [-20|200] "C" Vector__XXX
 SG_ INV3_GATE_U_TEMPERATURE : 120|12@1+ (0.0537241,-20) [-20|200] "C" Vector__XXX
 SG_ INV3_GATE_V_TEMPERATURE : 132|12@1+ (0.0537241,-20) [-20|200] "C" Vector__XXX
 SG_ INV3_GATE_W_TEMPERATURE : 144|12@1+ (0.0537241,-20) [-20|200] "C" Vector__XXX
 SG_ INV4_GATE_U_TEMPERATURE : 156|12@1+ (0.0537241,-20) [-20|200] "C" Vector__XXX
 SG_ INV4_GATE_V_TEMPERATURE : 168|12@1+ (0.0537241,-20) [-20|200] "C" Vector__XXX
 SG_ INV4_GATE_W_TEMPERATURE : 180|12@1+ (0.0537241,-20) [-20|200] "C" Vector__XXX
 SG_ INV1_GATE_FAULT : 192|1@1+ (1,0) [0|0] "" Vector__XXX
 SG_ INV1_ENC_FAULT : 193|1@1+ (1,0) [0|0] "" Vector__XXX
 SG_ INV1_OTP_FAULT : 194|1@1+ (1,0) [0|0] "" Vector__XXX
 SG_ INV1_OCP_FAULT : 195|1@1+ (1,0) [0|0] "" Vector__XXX
 SG_ INV2_GATE_FAULT : 200|1@1+ (1,0) [0|0] "" Vector__XXX
 SG_ INV2_ENC_FAULT : 201|1@1+ (1,0) [0|0] "" Vector__XXX
 SG_ INV2_OTP_FAULT : 202|1@1+ (1,0) [0|0] "" Vector__XXX
 SG_ INV2_OCP_FAULT : 203|1@1+ (1,0) [0|0] "" Vector__XXX
 SG_ INV3_GATE_FAULT : 208|1@1+ (1,0) [0|0] "" Vector__XXX
 SG_ INV3_ENC_FAULT : 209|1@1+ (1,0) [0|0] "" Vector__XXX
 SG_ INV3_OTP_FAULT : 210|1@1+ (1,0) [0|0] "" Vector__XXX
 SG_ INV3_OCP_FAULT : 211|1@1+ (1,0) [0|0] "" Vector__XXX
 SG_ INV4_GATE_FAULT : 216|1@1+ (1,0) [0|0] "" Vector__XXX
 SG_ INV4_ENC_FAULT : 217|1@1+ (1,0) [0|0] "" Vector__XXX
 SG_ INV4_OTP_FAULT : 218|1@1+ (1,0) [0|0] "" Vector__XXX
 SG_ INV4_OCP_FAULT : 219|1@1+ (1,0) [0|0] "" Vector__XXX

BO_ 1072 VCU_VCU_SENSOR1: 8 VCU
 SG_ BSE_REAR_PU : 0|16@1+ (0.0015259,0) [0|100] "%" AMS
 SG_ BSE_FRONT_PU : 16|16@1+ (0.0015259,0) [0|100] "%" AMS
 SG_ BSE_REAR_REAL : 32|16@1+ (0.000457771,0) [0|30] "bar" AMS
 SG_ BSE_FRONT_REAL : 48|16@1+ (0.000457771,0) [0|30] "bar" AMS

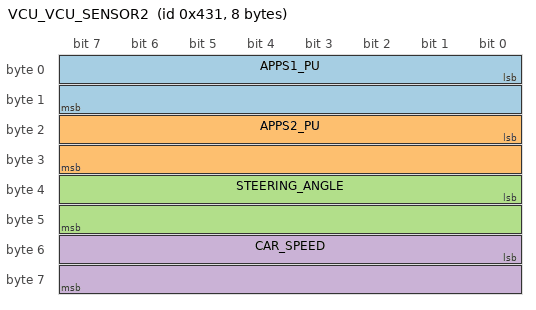
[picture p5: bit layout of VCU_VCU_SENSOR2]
BO_ 1073 VCU_VCU_SENSOR2: 8 VCU
 SG_ APPS1_PU : 0|16@1+ (0.0015259,0) [0|100] "%" AMS
 SG_ APPS2_PU : 16|16@1+ (0.0015259,0) [0|100] "%" AMS
 SG_ STEERING_ANGLE : 32|16@1+ (0.00549325,-180) [-180|180] "deg" AMS
 SG_ CAR_SPEED : 48|16@1+ (0.00457771,0) [0|300] "km/h" AMS

BO_ 1074 VCU_VCU_DASH: 8 VCU
 SG_ MAIN_STATUS_INDICATOR : 0|8@1+ (1,0) [0|0] "" Vector__XXX
 SG_ WARMUP_COUNTDOWN_S : 8|8@1+ (1,0) [0|0] "s" Vector__XXX

BO_ 1077 VCU_VCU_IMU_Q: 16 VCU
 SG_ QUATERNION_Q0 : 0|32@1- (1,0) [0|0] "" Vector__XXX
 SG_ QUATERNION_Q1 : 32|32@1- (1,0) [0|0] "" Vector__XXX
 SG_ QUATERNION_Q2 : 64|32@1- (1,0) [0|0] "" Vector__XXX
 SG_ QUATERNION_Q3 : 96|32@1- (1,0) [0|0] "" Vector__XXX

BO_ 1079 VCU_VCU_IMU_ACC: 12 VCU
 SG_ ACCELERATION_AX : 0|32@1- (1,0) [0|0] "m/s^2" Vector__XXX
 SG_ ACCELERATION_AY : 32|32@1- (1,0) [0|0] "m/s^2" Vector__XXX
 SG_ ACCELERATION_AZ : 64|32@1- (1,0) [0|0] "m/s^2" Vector__XXX

BO_ 1080 VCU_VCU_IMU_ROT: 12 VCU
 SG_ RATE_OF_TURN_GX : 0|32@1- (1,0) [0|0] "rad/s" Vector__XXX
 SG_ RATE_OF_TURN_GY : 32|32@1- (1,0) [0|0] "rad/s" Vector__XXX
 SG_ RATE_OF_TURN_GZ : 64|32@1- (1,0) [0|0] "rad/s" Vector__XXX

BO_ 1082 VCU_VCU_GPS: 16 VCU
 SG_ GPS_MODULE_ACTIVE : 0|1@1+ (1,0) [0|0] "" Vector__XXX
 SG_ GPS_NO_SIGNAL_STATE : 1|1@1+ (1,0) [0|0] "" Vector__XXX
 SG_ LATITUDE : 8|32@1- (1,0) [0|0] "" Vector__XXX
 SG_ LONGTITUDE : 40|32@1- (1,0) [0|0] "" Vector__XXX
 SG_ TIME : 72|56@1+ (1,0) [0|0] "" Vector__XXX

BO_ 1084 VCU_MCU1_STATUS_CONTROL: 8 VCU
 SG_ RECV_MODE_CMD : 0|1@1+ (1,0) [0|0] "" Vector__XXX

BO_ 1085 VCU_MCU2_STATUS_CONTROL: 8 VCU
 SG_ RECV_MODE_CMD : 0|1@1+ (1,0) [0|0] "" Vector__XXX

BO_ 1086 VCU_MCU3_STATUS_CONTROL: 8 VCU
 SG_ RECV_MODE_CMD : 0|1@1+ (1,0) [0|0] "" Vector__XXX

BO_ 1087 VCU_MCU4_STATUS_CONTROL: 8 VCU
 SG_ RECV_MODE_CMD : 0|1@1+ (1,0) [0|0] "" Vector__XXX

BO_ 1088 AMS_AMS_STATUS_BASIC: 32 AMS
 SG_ AMS_STATE : 0|2@1+ (1,0) [0|0] "" Vector__XXX
 SG_ BUS_OVER_CURRENT_ERR : 2|1@1+ (1,0) [0|0] "" Vector__XXX
 SG_ LTC_CONNECTION_LOSS : 3|1@1+ (1,0) [0|0] "" Vector__XXX
 SG_ CELL_OVER_VOLT_ERR : 4|1@1+ (1,0) [0|0] "" Vector__XXX
 SG_ CELL_UNDER_VOLT_ERR : 5|1@1+ (1,0) [0|0] "" Vector__XXX
 SG_ CELL_OVER_TEMP_ERR : 6|1@1+ (1,0) [0|0] "" Vector__XXX
 SG_ PACK_CURRENT : 8|16@1+ (0.009174,-300) [-300|301.218] "A" Vector__XXX
 SG_ PACK_VOLTAGE : 24|16@1+ (0.010638,0) [0|697.161] "V" Vector__XXX
 SG_ PACK_POWER : 40|32@1- (0,0) [0|0] "W" Vector__XXX
 SG_ PACK_SOC : 72|16@1+ (0.0015259,0) [0|100] "%" Vector__XXX
 SG_ CELL_V_MIN : 88|16@1+ (0.0000968948,0) [0|6.35] "V" Vector__XXX
 SG_ CELL_V_MAX : 104|16@1+ (0.0000968948,0) [0|6.35] "V" Vector__XXX
 SG_ CELL_V_DELTA : 120|16@1+ (0.0000968948,0) [0|6.35] "V" Vector__XXX
 SG_ TEMPERATURE_MAX : 136|16@1+ (0.00381476,-50) [-50|200] "° C" Vector__XXX
 SG_ TEMPERATURE_MIN : 152|16@1+ (0.00381476,-50) [-50|200] "° C" Vector__XXX
 SG_ TEMPERATURE_DELTA : 168|16@1+ (0.00381476,-50) [-50|200] "° C" Vector__XXX
 SG_ AMS_HEARTBEAT : 184|8@1+ (1,0) [0|0] "" Vector__XXX

BO_ 1089 AMS_AMS_STATUS_LIMIT: 16 AMS
 SG_ CHARGE_CURRENT_LIMIT : 0|32@1- (1,0) [0|0] "A" Vector__XXX
 SG_ CHARGE_POWER_LIMIT : 32|32@1- (1,0) [0|0] "W" Vector__XXX
 SG_ DISCHARGE_CURRENT_LIMIT : 64|32@1- (1,0) [0|0] "A" Vector__XXX
 SG_ DISCHARGE_POWER_LIMIT : 96|32@1- (1,0) [0|0] "W" Vector__XXX

BO_ 1098 AMS_AMS_MODULE_1: 48 AMS
 SG_ C0 : 0|16@1+ (0.0000968948,0) [0|6.35] "V" Vector__XXX
 SG_ C1 : 16|16@1+ (0.0000968948,0) [0|6.35] "V" Vector__XXX
 SG_ C2 : 32|16@1+ (0.0000968948,0) [0|6.35] "V" Vector__XXX
 SG_ C3 : 48|16@1+ (0.0000968948,0) [0|6.35] "V" Vector__XXX
 SG_ C4 : 64|16@1+ (0.0000968948,0) [0|6.35] "V" Vector__XXX
 SG_ C5 : 80|16@1+ (0.0000968948,0) [0|6.35] "V" Vector__XXX
 SG_ C6 : 96|16@1+ (0.0000968948,0) [0|6.35] "V" Vector__XXX
 SG_ C7 : 112|16@1+ (0.0000968948,0) [0|6.35] "V" Vector__XXX
 SG_ C8 : 128|16@1+ (0.0000968948,0) [0|6.35] "V" Vector__XXX
 SG_ C9 : 144|16@1+ (0.0000968948,0) [0|6.35] "V" Vector__XXX
 SG_ C10 : 160|16@1+ (0.0000968948,0) [0|6.35] "V" Vector__XXX
 SG_ C11 : 176|16@1+ (0.0000968948,0) [0|6.35] "V" Vector__XXX
 SG_ C12 : 192|16@1+ (0.0000968948,0) [0|6.35] "V" Vector__XXX
 SG_ C13 : 208|16@1+ (0.0000968948,0) [0|6.35] "V" Vector__XXX
 SG_ T0 : 224|16@1+ (0.00381476,-50) [-50|200] "° C" Vector__XXX
 SG_ T1 : 240|16@1+ (0.00381476,-50) [-50|200] "° C" Vector__XXX
 SG_ T2 : 256|16@1+ (0.00381476,-50) [-50|200] "° C" Vector__XXX
 SG_ T3 : 272|16@1+ (0.00381476,-50) [-50|200] "° C" Vector__XXX
 SG_ T4 : 288|16@1+ (0.00381476,-50) [-50|200] "° C" Vector__XXX
 SG_ T5 : 304|16@1+ (0.00381476,-50) [-50|200] "° C" Vector__XXX
 SG_ T6 : 320|16@1+ (0.00381476,-50) [-50|200] "° C" Vector__XXX
 SG_ C0_BALANCE_STATE : 336|1@1+ (1,0) [0|0] "" Vector__XXX
 SG_ C1_BALANCE_STATE : 337|1@1+ (1,0) [0|0] "" Vector__XXX
 SG_ C2_BALANCE_STATE : 338|1@1+ (1,0) [0|0] "" Vector__XXX
 SG_ C3_BALANCE_STATE : 339|1@1+ (1,0) [0|0] "" Vector__XXX
 SG_ C4_BALANCE_STATE : 340|1@1+ (1,0) [0|0] "" Vector__XXX
 SG_ C5_BALANCE_STATE : 341|1@1+ (1,0) [0|0] "" Vector__XXX
 SG_ C6_BALANCE_STATE : 342|1@1+ (1,0) [0|0] "" Vector__XXX
 SG_ C7_BALANCE_STATE : 343|1@1+ (1,0) [0|0] "" Vector__XXX
 SG_ C8_BALANCE_STATE : 344|1@1+ (1,0) [0|0] "" Vector__XXX
 SG_ C9_BALANCE_STATE : 345|1@1+ (1,0) [0|0] "" Vector__XXX
 SG_ C10_BALANCE_STATE : 346|1@1+ (1,0) [0|0] "" Vector__XXX
 SG_ C11_BALANCE_STATE : 347|1@1+ (1,0) [0|0] "" Vector__XXX
 SG_ C12_BALANCE_STATE : 348|1@1+ (1,0) [0|0] "" Vector__XXX
 SG_ C13_BALANCE_STATE : 349|1@1+ (1,0) [0|0] "" Vector__XXX

BO_ 1099 AMS_AMS_MODULE_2: 48 AMS
 SG_ C0 : 0|16@1+ (0.0000968948,0) [0|6.35] "V" Vector__XXX
 SG_ C1 : 16|16@1+ (0.0000968948,0) [0|6.35] "V" Vector__XXX
 SG_ C2 : 32|16@1+ (0.0000968948,0) [0|6.35] "V" Vector__XXX
 SG_ C3 : 48|16@1+ (0.0000968948,0) [0|6.35] "V" Vector__XXX
 SG_ C4 : 64|16@1+ (0.0000968948,0) [0|6.35] "V" Vector__XXX
 SG_ C5 : 80|16@1+ (0.0000968948,0) [0|6.35] "V" Vector__XXX
 SG_ C6 : 96|16@1+ (0.0000968948,0) [0|6.35] "V" Vector__XXX
 SG_ C7 : 112|16@1+ (0.0000968948,0) [0|6.35] "V" Vector__XXX
 SG_ C8 : 128|16@1+ (0.0000968948,0) [0|6.35] "V" Vector__XXX
 SG_ C9 : 144|16@1+ (0.0000968948,0) [0|6.35] "V" Vector__XXX
 SG_ C10 : 160|16@1+ (0.0000968948,0) [0|6.35] "V" Vector__XXX
 SG_ C11 : 176|16@1+ (0.0000968948,0) [0|6.35] "V" Vector__XXX
 SG_ C12 : 192|16@1+ (0.0000968948,0) [0|6.35] "V" Vector__XXX
 SG_ C13 : 208|16@1+ (0.0000968948,0) [0|6.35] "V" Vector__XXX
 SG_ T0 : 224|16@1+ (0.00381476,-50) [-50|200] "° C" Vector__XXX
 SG_ T1 : 240|16@1+ (0.00381476,-50) [-50|200] "° C" Vector__XXX
 SG_ T2 : 256|16@1+ (0.00381476,-50) [-50|200] "° C" Vector__XXX
 SG_ T3 : 272|16@1+ (0.00381476,-50) [-50|200] "° C" Vector__XXX
 SG_ T4 : 288|16@1+ (0.00381476,-50) [-50|200] "° C" Vector__XXX
 SG_ T5 : 304|16@1+ (0.00381476,-50) [-50|200] "° C" Vector__XXX
 SG_ T6 : 320|16@1+ (0.00381476,-50) [-50|200] "° C" Vector__XXX
 SG_ C0_BALANCE_STATE : 336|1@1+ (1,0) [0|0] "" Vector__XXX
 SG_ C1_BALANCE_STATE : 337|1@1+ (1,0) [0|0] "" Vector__XXX
 SG_ C2_BALANCE_STATE : 338|1@1+ (1,0) [0|0] "" Vector__XXX
 SG_ C3_BALANCE_STATE : 339|1@1+ (1,0) [0|0] "" Vector__XXX
 SG_ C4_BALANCE_STATE : 340|1@1+ (1,0) [0|0] "" Vector__XXX
 SG_ C5_BALANCE_STATE : 341|1@1+ (1,0) [0|0] "" Vector__XXX
 SG_ C6_BALANCE_STATE : 342|1@1+ (1,0) [0|0] "" Vector__XXX
 SG_ C7_BALANCE_STATE : 343|1@1+ (1,0) [0|0] "" Vector__XXX
 SG_ C8_BALANCE_STATE : 344|1@1+ (1,0) [0|0] "" Vector__XXX
 SG_ C9_BALANCE_STATE : 345|1@1+ (1,0) [0|0] "" Vector__XXX
 SG_ C10_BALANCE_STATE : 346|1@1+ (1,0) [0|0] "" Vector__XXX
 SG_ C11_BALANCE_STATE : 347|1@1+ (1,0) [0|0] "" Vector__XXX
 SG_ C12_BALANCE_STATE : 348|1@1+ (1,0) [0|0] "" Vector__XXX
 SG_ C13_BALANCE_STATE : 349|1@1+ (1,0) [0|0] "" Vector__XXX

BO_ 1100 AMS_AMS_MODULE_3: 48 AMS
 SG_ C0 : 0|16@1+ (0.0000968948,0) [0|6.35] "V" Vector__XXX
 SG_ C1 : 16|16@1+ (0.0000968948,0) [0|6.35] "V" Vector__XXX
 SG_ C2 : 32|16@1+ (0.0000968948,0) [0|6.35] "V" Vector__XXX
 SG_ C3 : 48|16@1+ (0.0000968948,0) [0|6.35] "V" Vector__XXX
 SG_ C4 : 64|16@1+ (0.0000968948,0) [0|6.35] "V" Vector__XXX
 SG_ C5 : 80|16@1+ (0.0000968948,0) [0|6.35] "V" Vector__XXX
 SG_ C6 : 96|16@1+ (0.0000968948,0) [0|6.35] "V" Vector__XXX
 SG_ C7 : 112|16@1+ (0.0000968948,0) [0|6.35] "V" Vector__XXX
 SG_ C8 : 128|16@1+ (0.0000968948,0) [0|6.35] "V" Vector__XXX
 SG_ C9 : 144|16@1+ (0.0000968948,0) [0|6.35] "V" Vector__XXX
 SG_ C10 : 160|16@1+ (0.0000968948,0) [0|6.35] "V" Vector__XXX
 SG_ C11 : 176|16@1+ (0.0000968948,0) [0|6.35] "V" Vector__XXX
 SG_ C12 : 192|16@1+ (0.0000968948,0) [0|6.35] "V" Vector__XXX
 SG_ C13 : 208|16@1+ (0.0000968948,0) [0|6.35] "V" Vector__XXX
 SG_ T0 : 224|16@1+ (0.00381476,-50) [-50|200] "° C" Vector__XXX
 SG_ T1 : 240|16@1+ (0.00381476,-50) [-50|200] "° C" Vector__XXX
 SG_ T2 : 256|16@1+ (0.00381476,-50) [-50|200] "° C" Vector__XXX
 SG_ T3 : 272|16@1+ (0.00381476,-50) [-50|200] "° C" Vector__XXX
 SG_ T4 : 288|16@1+ (0.00381476,-50) [-50|200] "° C" Vector__XXX
 SG_ T5 : 304|16@1+ (0.00381476,-50) [-50|200] "° C" Vector__XXX
 SG_ T6 : 320|16@1+ (0.00381476,-50) [-50|200] "° C" Vector__XXX
 SG_ C0_BALANCE_STATE : 336|1@1+ (1,0) [0|0] "" Vector__XXX
 SG_ C1_BALANCE_STATE : 337|1@1+ (1,0) [0|0] "" Vector__XXX
 SG_ C2_BALANCE_STATE : 338|1@1+ (1,0) [0|0] "" Vector__XXX
 SG_ C3_BALANCE_STATE : 339|1@1+ (1,0) [0|0] "" Vector__XXX
 SG_ C4_BALANCE_STATE : 340|1@1+ (1,0) [0|0] "" Vector__XXX
 SG_ C5_BALANCE_STATE : 341|1@1+ (1,0) [0|0] "" Vector__XXX
 SG_ C6_BALANCE_STATE : 342|1@1+ (1,0) [0|0] "" Vector__XXX
 SG_ C7_BALANCE_STATE : 343|1@1+ (1,0) [0|0] "" Vector__XXX
 SG_ C8_BALANCE_STATE : 344|1@1+ (1,0) [0|0] "" Vector__XXX
 SG_ C9_BALANCE_STATE : 345|1@1+ (1,0) [0|0] "" Vector__XXX
 SG_ C10_BALANCE_STATE : 346|1@1+ (1,0) [0|0] "" Vector__XXX
 SG_ C11_BALANCE_STATE : 347|1@1+ (1,0) [0|0] "" Vector__XXX
 SG_ C12_BALANCE_STATE : 348|1@1+ (1,0) [0|0] "" Vector__XXX
 SG_ C13_BALANCE_STATE : 349|1@1+ (1,0) [0|0] "" Vector__XXX

BO_ 1101 AMS_AMS_MODULE_4: 48 AMS
 SG_ C0 : 0|16@1+ (0.0000968948,0) [0|6.35] "V" Vector__XXX
 SG_ C1 : 16|16@1+ (0.0000968948,0) [0|6.35] "V" Vector__XXX
 SG_ C2 : 32|16@1+ (0.0000968948,0) [0|6.35] "V" Vector__XXX
 SG_ C3 : 48|16@1+ (0.0000968948,0) [0|6.35] "V" Vector__XXX
 SG_ C4 : 64|16@1+ (0.0000968948,0) [0|6.35] "V" Vector__XXX
 SG_ C5 : 80|16@1+ (0.0000968948,0) [0|6.35] "V" Vector__XXX
 SG_ C6 : 96|16@1+ (0.0000968948,0) [0|6.35] "V" Vector__XXX
 SG_ C7 : 112|16@1+ (0.0000968948,0) [0|6.35] "V" Vector__XXX
 SG_ C8 : 128|16@1+ (0.0000968948,0) [0|6.35] "V" Vector__XXX
 SG_ C9 : 144|16@1+ (0.0000968948,0) [0|6.35] "V" Vector__XXX
 SG_ C10 : 160|16@1+ (0.0000968948,0) [0|6.35] "V" Vector__XXX
 SG_ C11 : 176|16@1+ (0.0000968948,0) [0|6.35] "V" Vector__XXX
 SG_ C12 : 192|16@1+ (0.0000968948,0) [0|6.35] "V" Vector__XXX
 SG_ C13 : 208|16@1+ (0.0000968948,0) [0|6.35] "V" Vector__XXX
 SG_ T0 : 224|16@1+ (0.00381476,-50) [-50|200] "° C" Vector__XXX
 SG_ T1 : 240|16@1+ (0.00381476,-50) [-50|200] "° C" Vector__XXX
 SG_ T2 : 256|16@1+ (0.00381476,-50) [-50|200] "° C" Vector__XXX
 SG_ T3 : 272|16@1+ (0.00381476,-50) [-50|200] "° C" Vector__XXX
 SG_ T4 : 288|16@1+ (0.00381476,-50) [-50|200] "° C" Vector__XXX
 SG_ T5 : 304|16@1+ (0.00381476,-50) [-50|200] "° C" Vector__XXX
 SG_ T6 : 320|16@1+ (0.00381476,-50) [-50|200] "° C" Vector__XXX
 SG_ C0_BALANCE_STATE : 336|1@1+ (1,0) [0|0] "" Vector__XXX
 SG_ C1_BALANCE_STATE : 337|1@1+ (1,0) [0|0] "" Vector__XXX
 SG_ C2_BALANCE_STATE : 338|1@1+ (1,0) [0|0] "" Vector__XXX
 SG_ C3_BALANCE_STATE : 339|1@1+ (1,0) [0|0] "" Vector__XXX
 SG_ C4_BALANCE_STATE : 340|1@1+ (1,0) [0|0] "" Vector__XXX
 SG_ C5_BALANCE_STATE : 341|1@1+ (1,0) [0|0] "" Vector__XXX
 SG_ C6_BALANCE_STATE : 342|1@1+ (1,0) [0|0] "" Vector__XXX
 SG_ C7_BALANCE_STATE : 343|1@1+ (1,0) [0|0] "" Vector__XXX
 SG_ C8_BALANCE_STATE : 344|1@1+ (1,0) [0|0] "" Vector__XXX
 SG_ C9_BALANCE_STATE : 345|1@1+ (1,0) [0|0] "" Vector__XXX
 SG_ C10_BALANCE_STATE : 346|1@1+ (1,0) [0|0] "" Vector__XXX
 SG_ C11_BALANCE_STATE : 347|1@1+ (1,0) [0|0] "" Vector__XXX
 SG_ C12_BALANCE_STATE : 348|1@1+ (1,0) [0|0] "" Vector__XXX
 SG_ C13_BALANCE_STATE : 349|1@1+ (1,0) [0|0] "" Vector__XXX

BO_ 1102 AMS_AMS_MODULE_5: 48 AMS
 SG_ C0 : 0|16@1+ (0.0000968948,0) [0|6.35] "V" Vector__XXX
 SG_ C1 : 16|16@1+ (0.0000968948,0) [0|6.35] "V" Vector__XXX
 SG_ C2 : 32|16@1+ (0.0000968948,0) [0|6.35] "V" Vector__XXX
 SG_ C3 : 48|16@1+ (0.0000968948,0) [0|6.35] "V" Vector__XXX
 SG_ C4 : 64|16@1+ (0.0000968948,0) [0|6.35] "V" Vector__XXX
 SG_ C5 : 80|16@1+ (0.0000968948,0) [0|6.35] "V" Vector__XXX
 SG_ C6 : 96|16@1+ (0.0000968948,0) [0|6.35] "V" Vector__XXX
 SG_ C7 : 112|16@1+ (0.0000968948,0) [0|6.35] "V" Vector__XXX
 SG_ C8 : 128|16@1+ (0.0000968948,0) [0|6.35] "V" Vector__XXX
 SG_ C9 : 144|16@1+ (0.0000968948,0) [0|6.35] "V" Vector__XXX
 SG_ C10 : 160|16@1+ (0.0000968948,0) [0|6.35] "V" Vector__XXX
 SG_ C11 : 176|16@1+ (0.0000968948,0) [0|6.35] "V" Vector__XXX
 SG_ C12 : 192|16@1+ (0.0000968948,0) [0|6.35] "V" Vector__XXX
 SG_ C13 : 208|16@1+ (0.0000968948,0) [0|6.35] "V" Vector__XXX
 SG_ T0 : 224|16@1+ (0.00381476,-50) [-50|200] "° C" Vector__XXX
 SG_ T1 : 240|16@1+ (0.00381476,-50) [-50|200] "° C" Vector__XXX
 SG_ T2 : 256|16@1+ (0.00381476,-50) [-50|200] "° C" Vector__XXX
 SG_ T3 : 272|16@1+ (0.00381476,-50) [-50|200] "° C" Vector__XXX
 SG_ T4 : 288|16@1+ (0.00381476,-50) [-50|200] "° C" Vector__XXX
 SG_ T5 : 304|16@1+ (0.00381476,-50) [-50|200] "° C" Vector__XXX
 SG_ T6 : 320|16@1+ (0.00381476,-50) [-50|200] "° C" Vector__XXX
 SG_ C0_BALANCE_STATE : 336|1@1+ (1,0) [0|0] "" Vector__XXX
 SG_ C1_BALANCE_STATE : 337|1@1+ (1,0) [0|0] "" Vector__XXX
 SG_ C2_BALANCE_STATE : 338|1@1+ (1,0) [0|0] "" Vector__XXX
 SG_ C3_BALANCE_STATE : 339|1@1+ (1,0) [0|0] "" Vector__XXX
 SG_ C4_BALANCE_STATE : 340|1@1+ (1,0) [0|0] "" Vector__XXX
 SG_ C5_BALANCE_STATE : 341|1@1+ (1,0) [0|0] "" Vector__XXX
 SG_ C6_BALANCE_STATE : 342|1@1+ (1,0) [0|0] "" Vector__XXX
 SG_ C7_BALANCE_STATE : 343|1@1+ (1,0) [0|0] "" Vector__XXX
 SG_ C8_BALANCE_STATE : 344|1@1+ (1,0) [0|0] "" Vector__XXX
 SG_ C9_BALANCE_STATE : 345|1@1+ (1,0) [0|0] "" Vector__XXX
 SG_ C10_BALANCE_STATE : 346|1@1+ (1,0) [0|0] "" Vector__XXX
 SG_ C11_BALANCE_STATE : 347|1@1+ (1,0) [0|0] "" Vector__XXX
 SG_ C12_BALANCE_STATE : 348|1@1+ (1,0) [0|0] "" Vector__XXX
 SG_ C13_BALANCE_STATE : 349|1@1+ (1,0) [0|0] "" Vector__XXX

BO_ 1103 AMS_AMS_MODULE_6: 48 AMS
 SG_ C0 : 0|16@1+ (0.0000968948,0) [0|6.35] "V" Vector__XXX
 SG_ C1 : 16|16@1+ (0.0000968948,0) [0|6.35] "V" Vector__XXX
 SG_ C2 : 32|16@1+ (0.0000968948,0) [0|6.35] "V" Vector__XXX
 SG_ C3 : 48|16@1+ (0.0000968948,0) [0|6.35] "V" Vector__XXX
 SG_ C4 : 64|16@1+ (0.0000968948,0) [0|6.35] "V" Vector__XXX
 SG_ C5 : 80|16@1+ (0.0000968948,0) [0|6.35] "V" Vector__XXX
 SG_ C6 : 96|16@1+ (0.0000968948,0) [0|6.35] "V" Vector__XXX
 SG_ C7 : 112|16@1+ (0.0000968948,0) [0|6.35] "V" Vector__XXX
 SG_ C8 : 128|16@1+ (0.0000968948,0) [0|6.35] "V" Vector__XXX
 SG_ C9 : 144|16@1+ (0.0000968948,0) [0|6.35] "V" Vector__XXX
 SG_ C10 : 160|16@1+ (0.0000968948,0) [0|6.35] "V" Vector__XXX
 SG_ C11 : 176|16@1+ (0.0000968948,0) [0|6.35] "V" Vector__XXX
 SG_ C12 : 192|16@1+ (0.0000968948,0) [0|6.35] "V" Vector__XXX
 SG_ C13 : 208|16@1+ (0.0000968948,0) [0|6.35] "V" Vector__XXX
 SG_ T0 : 224|16@1+ (0.00381476,-50) [-50|200] "° C" Vector__XXX
 SG_ T1 : 240|16@1+ (0.00381476,-50) [-50|200] "° C" Vector__XXX
 SG_ T2 : 256|16@1+ (0.00381476,-50) [-50|200] "° C" Vector__XXX
 SG_ T3 : 272|16@1+ (0.00381476,-50) [-50|200] "° C" Vector__XXX
 SG_ T4 : 288|16@1+ (0.00381476,-50) [-50|200] "° C" Vector__XXX
 SG_ T5 : 304|16@1+ (0.00381476,-50) [-50|200] "° C" Vector__XXX
 SG_ T6 : 320|16@1+ (0.00381476,-50) [-50|200] "° C" Vector__XXX
 SG_ C0_BALANCE_STATE : 336|1@1+ (1,0) [0|0] "" Vector__XXX
 SG_ C1_BALANCE_STATE : 337|1@1+ (1,0) [0|0] "" Vector__XXX
 SG_ C2_BALANCE_STATE : 338|1@1+ (1,0) [0|0] "" Vector__XXX
 SG_ C3_BALANCE_STATE : 339|1@1+ (1,0) [0|0] "" Vector__XXX
 SG_ C4_BALANCE_STATE : 340|1@1+ (1,0) [0|0] "" Vector__XXX
 SG_ C5_BALANCE_STATE : 341|1@1+ (1,0) [0|0] "" Vector__XXX
 SG_ C6_BALANCE_STATE : 342|1@1+ (1,0) [0|0] "" Vector__XXX
 SG_ C7_BALANCE_STATE : 343|1@1+ (1,0) [0|0] "" Vector__XXX
 SG_ C8_BALANCE_STATE : 344|1@1+ (1,0) [0|0] "" Vector__XXX
 SG_ C9_BALANCE_STATE : 345|1@1+ (1,0) [0|0] "" Vector__XXX
 SG_ C10_BALANCE_STATE : 346|1@1+ (1,0) [0|0] "" Vector__XXX
 SG_ C11_BALANCE_STATE : 347|1@1+ (1,0) [0|0] "" Vector__XXX
 SG_ C12_BALANCE_STATE : 348|1@1+ (1,0) [0|0] "" Vector__XXX
 SG_ C13_BALANCE_STATE : 349|1@1+ (1,0) [0|0] "" Vector__XXX

BO_ 1104 AMS_AMS_MODULE_7: 48 AMS
 SG_ C0 : 0|16@1+ (0.0000968948,0) [0|6.35] "V" Vector__XXX
 SG_ C1 : 16|16@1+ (0.0000968948,0) [0|6.35] "V" Vector__XXX
 SG_ C2 : 32|16@1+ (0.0000968948,0) [0|6.35] "V" Vector__XXX
 SG_ C3 : 48|16@1+ (0.0000968948,0) [0|6.35] "V" Vector__XXX
 SG_ C4 : 64|16@1+ (0.0000968948,0) [0|6.35] "V" Vector__XXX
 SG_ C5 : 80|16@1+ (0.0000968948,0) [0|6.35] "V" Vector__XXX
 SG_ C6 : 96|16@1+ (0.0000968948,0) [0|6.35] "V" Vector__XXX
 SG_ C7 : 112|16@1+ (0.0000968948,0) [0|6.35] "V" Vector__XXX
 SG_ C8 : 128|16@1+ (0.0000968948,0) [0|6.35] "V" Vector__XXX
 SG_ C9 : 144|16@1+ (0.0000968948,0) [0|6.35] "V" Vector__XXX
 SG_ C10 : 160|16@1+ (0.0000968948,0) [0|6.35] "V" Vector__XXX
 SG_ C11 : 176|16@1+ (0.0000968948,0) [0|6.35] "V" Vector__XXX
 SG_ C12 : 192|16@1+ (0.0000968948,0) [0|6.35] "V" Vector__XXX
 SG_ C13 : 208|16@1+ (0.0000968948,0) [0|6.35] "V" Vector__XXX
 SG_ T0 : 224|16@1+ (0.00381476,-50) [-50|200] "° C" Vector__XXX
 SG_ T1 : 240|16@1+ (0.00381476,-50) [-50|200] "° C" Vector__XXX
 SG_ T2 : 256|16@1+ (0.00381476,-50) [-50|200] "° C" Vector__XXX
 SG_ T3 : 272|16@1+ (0.00381476,-50) [-50|200] "° C" Vector__XXX
 SG_ T4 : 288|16@1+ (0.00381476,-50) [-50|200] "° C" Vector__XXX
 SG_ T5 : 304|16@1+ (0.00381476,-50) [-50|200] "° C" Vector__XXX
 SG_ T6 : 320|16@1+ (0.00381476,-50) [-50|200] "° C" Vector__XXX
 SG_ C0_BALANCE_STATE : 336|1@1+ (1,0) [0|0] "" Vector__XXX
 SG_ C1_BALANCE_STATE : 337|1@1+ (1,0) [0|0] "" Vector__XXX
 SG_ C2_BALANCE_STATE : 338|1@1+ (1,0) [0|0] "" Vector__XXX
 SG_ C3_BALANCE_STATE : 339|1@1+ (1,0) [0|0] "" Vector__XXX
 SG_ C4_BALANCE_STATE : 340|1@1+ (1,0) [0|0] "" Vector__XXX
 SG_ C5_BALANCE_STATE : 341|1@1+ (1,0) [0|0] "" Vector__XXX
 SG_ C6_BALANCE_STATE : 342|1@1+ (1,0) [0|0] "" Vector__XXX
 SG_ C7_BALANCE_STATE : 343|1@1+ (1,0) [0|0] "" Vector__XXX
 SG_ C8_BALANCE_STATE : 344|1@1+ (1,0) [0|0] "" Vector__XXX
 SG_ C9_BALANCE_STATE : 345|1@1+ (1,0) [0|0] "" Vector__XXX
 SG_ C10_BALANCE_STATE : 346|1@1+ (1,0) [0|0] "" Vector__XXX
 SG_ C11_BALANCE_STATE : 347|1@1+ (1,0) [0|0] "" Vector__XXX
 SG_ C12_BALANCE_STATE : 348|1@1+ (1,0) [0|0] "" Vector__XXX
 SG_ C13_BALANCE_STATE : 349|1@1+ (1,0) [0|0] "" Vector__XXX

BO_ 1105 AMS_AMS_MODULE_8: 48 AMS
 SG_ C0 : 0|16@1+ (0.0000968948,0) [0|6.35] "V" Vector__XXX
 SG_ C1 : 16|16@1+ (0.0000968948,0) [0|6.35] "V" Vector__XXX
 SG_ C2 : 32|16@1+ (0.0000968948,0) [0|6.35] "V" Vector__XXX
 SG_ C3 : 48|16@1+ (0.0000968948,0) [0|6.35] "V" Vector__XXX
 SG_ C4 : 64|16@1+ (0.0000968948,0) [0|6.35] "V" Vector__XXX
 SG_ C5 : 80|16@1+ (0.0000968948,0) [0|6.35] "V" Vector__XXX
 SG_ C6 : 96|16@1+ (0.0000968948,0) [0|6.35] "V" Vector__XXX
 SG_ C7 : 112|16@1+ (0.0000968948,0) [0|6.35] "V" Vector__XXX
 SG_ C8 : 128|16@1+ (0.0000968948,0) [0|6.35] "V" Vector__XXX
 SG_ C9 : 144|16@1+ (0.0000968948,0) [0|6.35] "V" Vector__XXX
 SG_ C10 : 160|16@1+ (0.0000968948,0) [0|6.35] "V" Vector__XXX
 SG_ C11 : 176|16@1+ (0.0000968948,0) [0|6.35] "V" Vector__XXX
 SG_ C12 : 192|16@1+ (0.0000968948,0) [0|6.35] "V" Vector__XXX
 SG_ C13 : 208|16@1+ (0.0000968948,0) [0|6.35] "V" Vector__XXX
 SG_ T0 : 224|16@1+ (0.00381476,-50) [-50|200] "° C" Vector__XXX
 SG_ T1 : 240|16@1+ (0.00381476,-50) [-50|200] "° C" Vector__XXX
 SG_ T2 : 256|16@1+ (0.00381476,-50) [-50|200] "° C" Vector__XXX
 SG_ T3 : 272|16@1+ (0.00381476,-50) [-50|200] "° C" Vector__XXX
 SG_ T4 : 288|16@1+ (0.00381476,-50) [-50|200] "° C" Vector__XXX
 SG_ T5 : 304|16@1+ (0.00381476,-50) [-50|200] "° C" Vector__XXX
 SG_ T6 : 320|16@1+ (0.00381476,-50) [-50|200] "° C" Vector__XXX
 SG_ C0_BALANCE_STATE : 336|1@1+ (1,0) [0|0] "" Vector__XXX
 SG_ C1_BALANCE_STATE : 337|1@1+ (1,0) [0|0] "" Vector__XXX
 SG_ C2_BALANCE_STATE : 338|1@1+ (1,0) [0|0] "" Vector__XXX
 SG_ C3_BALANCE_STATE : 339|1@1+ (1,0) [0|0] "" Vector__XXX
 SG_ C4_BALANCE_STATE : 340|1@1+ (1,0) [0|0] "" Vector__XXX
 SG_ C5_BALANCE_STATE : 341|1@1+ (1,0) [0|0] "" Vector__XXX
 SG_ C6_BALANCE_STATE : 342|1@1+ (1,0) [0|0] "" Vector__XXX
 SG_ C7_BALANCE_STATE : 343|1@1+ (1,0) [0|0] "" Vector__XXX
 SG_ C8_BALANCE_STATE : 344|1@1+ (1,0) [0|0] "" Vector__XXX
 SG_ C9_BALANCE_STATE : 345|1@1+ (1,0) [0|0] "" Vector__XXX
 SG_ C10_BALANCE_STATE : 346|1@1+ (1,0) [0|0] "" Vector__XXX
 SG_ C11_BALANCE_STATE : 347|1@1+ (1,0) [0|0] "" Vector__XXX
 SG_ C12_BALANCE_STATE : 348|1@1+ (1,0) [0|0] "" Vector__XXX
 SG_ C13_BALANCE_STATE : 349|1@1+ (1,0) [0|0] "" Vector__XXX

BO_ 1108 AMS_AMS_STATUS_DEBUG: 32 AMS
 SG_ FW_GIT_SHA : 0|32@1+ (1,0) [0|0] "" Vector__XXX
 SG_ FW_BUILD_UNIX : 32|32@1+ (1,0) [0|0] "" Vector__XXX
 SG_ HAL_TICK_MS : 64|32@1+ (1,0) [0|0] "" Vector__XXX
 SG_ LOOP_TIME_US : 96|16@1+ (1,0) [0|0] "" Vector__XXX
 SG_ LOOP_TIME_MAX_US : 112|16@1+ (1,0) [0|0] "" Vector__XXX
 SG_ TICK_OVERRUN : 128|16@1+ (1,0) [0|0] "" Vector__XXX
 SG_ CURRENT_ZERO_TRIM : 144|16@1- (1,0) [0|0] "" Vector__XXX
 SG_ CURRENT_OFFSET_RESID : 160|16@1- (1,0) [0|0] "" Vector__XXX
 SG_ CURRENT_REF : 176|16@1+ (1,0) [0|0] "" Vector__XXX
 SG_ SOC_SETTLE_DRIFT : 192|16@1+ (1,0) [0|0] "" Vector__XXX
 SG_ SOC_REST_ELAPSED_S : 208|16@1+ (1,0) [0|0] "" Vector__XXX
 SG_ CPL_REASON : 224|8@1+ (1,0) [0|0] "" Vector__XXX
 SG_ DCL_REASON : 232|8@1+ (1,0) [0|0] "" Vector__XXX
 SG_ BAL_CELL_COUNT : 248|8@1+ (1,0) [0|0] "" Vector__XXX

BO_ 1217 MCU1_STATUS_SYSTEM: 16 MCU1
 SG_ ENCODER_FAULT : 0|1@1+ (1,0) [0|0] "" Vector__XXX
 SG_ OVP_FAULT : 1|1@1+ (1,0) [0|0] "" Vector__XXX
 SG_ UVP_FAULT : 2|1@1+ (1,0) [0|0] "" Vector__XXX
 SG_ RECV_CTRL_LOSS_FAULT : 3|1@1+ (1,0) [0|0] "" Vector__XXX
 SG_ U_GATE_OTP_FAULT : 4|1@1+ (1,0) [0|0] "" Vector__XXX
 SG_ V_GATE_OTP_FAULT : 5|1@1+ (1,0) [0|0] "" Vector__XXX
 SG_ MOTOR_OTP_FAULT : 6|1@1+ (1,0) [0|0] "" Vector__XXX
 SG_ W_GATE_OTP_FAULT : 7|1@1+ (1,0) [0|0] "" Vector__XXX
 SG_ DIRECTION_STATE : 8|1@1+ (1,0) [0|0] "" Vector__XXX
 SG_ RECV_MODE_BROADCAST_STATE : 9|1@1+ (1,0) [0|0] "" Vector__XXX
 SG_ RECV_MODE_STANDALONE_STATE : 10|1@1+ (1,0) [0|0] "" Vector__XXX
 SG_ FW_EN_ECHO : 11|1@1+ (1,0) [0|0] "" Vector__XXX
 SG_ RUN_MODE_STATE : 12|2@1+ (1,0) [0|0] "" Vector__XXX
 SG_ TORQUE_CMD_ECHO : 16|12@1+ (0.014652,-30) [-30|30] "C" Vector__XXX
 SG_ TORQUE_FB : 28|12@1+ (0.014652,-30) [-30|30] "NM" Vector__XXX
 SG_ VDC_FB : 40|16@1+ (0.0106813,0) [0|700] "V" Vector__XXX
 SG_ POWER_FB : 56|16@1+ (1.22072,-40000) [-40000|40000] "P" Vector__XXX
 SG_ MOTOR_TEMPERATURE_FB : 72|12@1+ (0.0537241,-20) [-20|200] "C" Vector__XXX
 SG_ U_PHASE_TEMPERATURE_FB : 84|12@1+ (0.0537241,-20) [-20|200] "C" Vector__XXX
 SG_ V_PHASE_TEMPERATURE_FB : 96|12@1+ (0.0537241,-20) [-20|200] "C" Vector__XXX
 SG_ W_PHASE_TEMPERATURE_FB : 108|12@1+ (0.0537241,-20) [-20|200] "C" Vector__XXX
 SG_ MCU_HEARTBEAT : 120|8@1+ (1,0) [0|0] "" Vector__XXX

BO_ 1218 MCU1_STATUS_FOC: 12 MCU1
 SG_ IQ_REF : 0|12@1+ (0.0976801,-200) [-200|200] "A" Vector__XXX
 SG_ ID_REF : 12|12@1+ (0.0976801,-200) [-200|200] "A" Vector__XXX
 SG_ ID_FW : 24|12@1+ (0.0976801,-200) [-200|200] "A" Vector__XXX
 SG_ VD_REQ : 36|12@1+ (0.34188,-700) [-700|700] "V" Vector__XXX
 SG_ VQ_REQ : 48|12@1+ (0.34188,-700) [-700|700] "V" Vector__XXX
 SG_ VMAG : 60|12@1+ (0.17094,0) [0|700] "V" Vector__XXX
 SG_ VOUT_MAX : 72|12@1+ (0.17094,0) [0|700] "V" Vector__XXX

BO_ 1219 MCU1_STATUS_DEBUG: 16 MCU1
 SG_ ISR_DURATION_US : 0|8@1+ (0.498039,0) [0|127] "us" Vector__XXX
 SG_ BOOT_COUNT : 8|16@1+ (1,0) [0|65535] "" Vector__XXX
 SG_ ENCODER_ERR_COUNT : 24|16@1+ (1,0) [0|65535] "" Vector__XXX
 SG_ PI_IQ_UI : 40|16@1+ (0.0213626,-700) [-700|700] "" Vector__XXX
 SG_ PI_ID_UI : 56|16@1+ (0.0213626,-700) [-700|700] "" Vector__XXX
 SG_ MCU_ID_STATE : 72|4@1+ (1,0) [0|0] "" Vector__XXX
 SG_ FLASH_LAST_ERROR_STATE : 76|4@1+ (1,0) [0|0] "" Vector__XXX
 SG_ RESET_CAUSE : 80|4@1+ (1,0) [0|0] "" Vector__XXX
 SG_ SOFT_STOP_REASON : 84|4@1+ (1,0) [0|0] "" Vector__XXX
 SG_ UPTIME_S : 88|16@1+ (1,0) [0|65535] "s" Vector__XXX
 SG_ ENCODER_THETA : 104|12@1+ (0.0879121,0) [0|360] "deg" Vector__XXX
 SG_ ENC_MAX_ACCL : 116|12@1+ (1,0) [0|0] "" Vector__XXX

BO_ 1220 MCU1_STATUS_GATE_U: 8 MCU1
 SG_ H_NLSE : 0|1@1+ (1,0) [0|0] "" Vector__XXX
 SG_ H_OVLO2 : 1|1@1+ (1,0) [0|0] "" Vector__XXX
 SG_ H_UVLO2 : 2|1@1+ (1,0) [0|0] "" Vector__XXX
 SG_ H_OVLO3 : 3|1@1+ (1,0) [0|0] "" Vector__XXX
 SG_ H_UVLO3 : 4|1@1+ (1,0) [0|0] "" Vector__XXX
 SG_ H_BDW : 5|1@1+ (1,0) [0|0] "" Vector__XXX
 SG_ H_SASC : 6|1@1+ (1,0) [0|0] "" Vector__XXX
 SG_ H_DTW : 7|1@1+ (1,0) [0|0] "" Vector__XXX
 SG_ H_STPKW : 8|1@1+ (1,0) [0|0] "" Vector__XXX
 SG_ H_OSME : 9|1@1+ (1,0) [0|0] "" Vector__XXX
 SG_ H_GME : 10|1@1+ (1,0) [0|0] "" Vector__XXX
 SG_ H_DDE : 11|1@1+ (1,0) [0|0] "" Vector__XXX
 SG_ H_NDBISTW : 12|1@1+ (1,0) [0|0] "" Vector__XXX
 SG_ H_SASCAW : 13|1@1+ (1,0) [0|0] "" Vector__XXX
 SG_ L_NLSE : 14|1@1+ (1,0) [0|0] "" Vector__XXX
 SG_ L_OVLO2 : 15|1@1+ (1,0) [0|0] "" Vector__XXX
 SG_ L_UVLO2 : 16|1@1+ (1,0) [0|0] "" Vector__XXX
 SG_ L_OVLO3 : 17|1@1+ (1,0) [0|0] "" Vector__XXX
 SG_ L_UVLO3 : 18|1@1+ (1,0) [0|0] "" Vector__XXX
 SG_ L_BDW : 19|1@1+ (1,0) [0|0] "" Vector__XXX
 SG_ L_SASC : 20|1@1+ (1,0) [0|0] "" Vector__XXX
 SG_ L_DTW : 21|1@1+ (1,0) [0|0] "" Vector__XXX
 SG_ L_STPKW : 22|1@1+ (1,0) [0|0] "" Vector__XXX
 SG_ L_OSME : 23|1@1+ (1,0) [0|0] "" Vector__XXX
 SG_ L_GME : 24|1@1+ (1,0) [0|0] "" Vector__XXX
 SG_ L_DDE : 25|1@1+ (1,0) [0|0] "" Vector__XXX
 SG_ L_NDBISTW : 26|1@1+ (1,0) [0|0] "" Vector__XXX
 SG_ L_SASCAW : 27|1@1+ (1,0) [0|0] "" Vector__XXX
 SG_ TEMPERATURE : 32|16@1+ (0.00213626,-20) [-20|120] "" Vector__XXX
 SG_ VOLTAGE : 48|16@1+ (0.0106813,0) [0|700] "" Vector__XXX

BO_ 1221 MCU1_STATUS_GATE_V: 8 MCU1
 SG_ H_NLSE : 0|1@1+ (1,0) [0|0] "" Vector__XXX
 SG_ H_OVLO2 : 1|1@1+ (1,0) [0|0] "" Vector__XXX
 SG_ H_UVLO2 : 2|1@1+ (1,0) [0|0] "" Vector__XXX
 SG_ H_OVLO3 : 3|1@1+ (1,0) [0|0] "" Vector__XXX
 SG_ H_UVLO3 : 4|1@1+ (1,0) [0|0] "" Vector__XXX
 SG_ H_BDW : 5|1@1+ (1,0) [0|0] "" Vector__XXX
 SG_ H_SASC : 6|1@1+ (1,0) [0|0] "" Vector__XXX
 SG_ H_DTW : 7|1@1+ (1,0) [0|0] "" Vector__XXX
 SG_ H_STPKW : 8|1@1+ (1,0) [0|0] "" Vector__XXX
 SG_ H_OSME : 9|1@1+ (1,0) [0|0] "" Vector__XXX
 SG_ H_GME : 10|1@1+ (1,0) [0|0] "" Vector__XXX
 SG_ H_DDE : 11|1@1+ (1,0) [0|0] "" Vector__XXX
 SG_ H_NDBISTW : 12|1@1+ (1,0) [0|0] "" Vector__XXX
 SG_ H_SASCAW : 13|1@1+ (1,0) [0|0] "" Vector__XXX
 SG_ L_NLSE : 14|1@1+ (1,0) [0|0] "" Vector__XXX
 SG_ L_OVLO2 : 15|1@1+ (1,0) [0|0] "" Vector__XXX
 SG_ L_UVLO2 : 16|1@1+ (1,0) [0|0] "" Vector__XXX
 SG_ L_OVLO3 : 17|1@1+ (1,0) [0|0] "" Vector__XXX
 SG_ L_UVLO3 : 18|1@1+ (1,0) [0|0] "" Vector__XXX
 SG_ L_BDW : 19|1@1+ (1,0) [0|0] "" Vector__XXX
 SG_ L_SASC : 20|1@1+ (1,0) [0|0] "" Vector__XXX
 SG_ L_DTW : 21|1@1+ (1,0) [0|0] "" Vector__XXX
 SG_ L_STPKW : 22|1@1+ (1,0) [0|0] "" Vector__XXX
 SG_ L_OSME : 23|1@1+ (1,0) [0|0] "" Vector__XXX
 SG_ L_GME : 24|1@1+ (1,0) [0|0] "" Vector__XXX
 SG_ L_DDE : 25|1@1+ (1,0) [0|0] "" Vector__XXX
 SG_ L_NDBISTW : 26|1@1+ (1,0) [0|0] "" Vector__XXX
 SG_ L_SASCAW : 27|1@1+ (1,0) [0|0] "" Vector__XXX
 SG_ TEMPERATURE : 32|16@1+ (0.00213626,-20) [-20|120] "" Vector__XXX
 SG_ VOLTAGE : 48|16@1+ (0.0106813,0) [0|700] "" Vector__XXX

BO_ 1222 MCU1_STATUS_GATE_W: 8 MCU1
 SG_ H_NLSE : 0|1@1+ (1,0) [0|0] "" Vector__XXX
 SG_ H_OVLO2 : 1|1@1+ (1,0) [0|0] "" Vector__XXX
 SG_ H_UVLO2 : 2|1@1+ (1,0) [0|0] "" Vector__XXX
 SG_ H_OVLO3 : 3|1@1+ (1,0) [0|0] "" Vector__XXX
 SG_ H_UVLO3 : 4|1@1+ (1,0) [0|0] "" Vector__XXX
 SG_ H_BDW : 5|1@1+ (1,0) [0|0] "" Vector__XXX
 SG_ H_SASC : 6|1@1+ (1,0) [0|0] "" Vector__XXX
 SG_ H_DTW : 7|1@1+ (1,0) [0|0] "" Vector__XXX
 SG_ H_STPKW : 8|1@1+ (1,0) [0|0] "" Vector__XXX
 SG_ H_OSME : 9|1@1+ (1,0) [0|0] "" Vector__XXX
 SG_ H_GME : 10|1@1+ (1,0) [0|0] "" Vector__XXX
 SG_ H_DDE : 11|1@1+ (1,0) [0|0] "" Vector__XXX
 SG_ H_NDBISTW : 12|1@1+ (1,0) [0|0] "" Vector__XXX
 SG_ H_SASCAW : 13|1@1+ (1,0) [0|0] "" Vector__XXX
 SG_ L_NLSE : 14|1@1+ (1,0) [0|0] "" Vector__XXX
 SG_ L_OVLO2 : 15|1@1+ (1,0) [0|0] "" Vector__XXX
 SG_ L_UVLO2 : 16|1@1+ (1,0) [0|0] "" Vector__XXX
 SG_ L_OVLO3 : 17|1@1+ (1,0) [0|0] "" Vector__XXX
 SG_ L_UVLO3 : 18|1@1+ (1,0) [0|0] "" Vector__XXX
 SG_ L_BDW : 19|1@1+ (1,0) [0|0] "" Vector__XXX
 SG_ L_SASC : 20|1@1+ (1,0) [0|0] "" Vector__XXX
 SG_ L_DTW : 21|1@1+ (1,0) [0|0] "" Vector__XXX
 SG_ L_STPKW : 22|1@1+ (1,0) [0|0] "" Vector__XXX
 SG_ L_OSME : 23|1@1+ (1,0) [0|0] "" Vector__XXX
 SG_ L_GME : 24|1@1+ (1,0) [0|0] "" Vector__XXX
 SG_ L_DDE : 25|1@1+ (1,0) [0|0] "" Vector__XXX
 SG_ L_NDBISTW : 26|1@1+ (1,0) [0|0] "" Vector__XXX
 SG_ L_SASCAW : 27|1@1+ (1,0) [0|0] "" Vector__XXX
 SG_ TEMPERATURE : 32|16@1+ (0.00213626,-20) [-20|120] "" Vector__XXX
 SG_ VOLTAGE : 48|16@1+ (0.0106813,0) [0|700] "" Vector__XXX

BO_ 1223 MCU1_STATUS_COMM: 32 MCU1
 SG_ CMD_MISS_CONSEC_AVG : 0|16@1+ (0.000762951,0) [0|50] "" Vector__XXX
 SG_ CMD_MISS_CONSEC_MAX : 16|16@1+ (1,0) [0|0] "" Vector__XXX
 SG_ CMD_GAP_MS_AVG : 32|16@1+ (0.0015259,0) [0|100] "ms" Vector__XXX
 SG_ CMD_GAP_MS_MAX : 48|16@1+ (0.0015259,0) [0|100] "ms" Vector__XXX
 SG_ RX_QUEUE_DROP_COUNT : 64|16@1+ (1,0) [0|0] "" Vector__XXX
 SG_ BUS_OFF_COUNT : 80|16@1+ (1,0) [0|0] "" Vector__XXX
 SG_ TEC : 96|16@1+ (1,0) [0|0] "" Vector__XXX
 SG_ REC : 112|16@1+ (1,0) [0|0] "" Vector__XXX
 SG_ TX_FRAME_COUNT : 128|32@1+ (1,0) [0|0] "" Vector__XXX
 SG_ TX_DROP_COUNT : 160|16@1+ (1,0) [0|0] "" Vector__XXX
 SG_ TX_STALL_MAX_MS : 176|16@1+ (1,0) [0|0] "" Vector__XXX
 SG_ CEL_TOTAL : 192|16@1+ (1,0) [0|0] "" Vector__XXX
 SG_ RX_DEAF_MAX_MS : 208|16@1+ (1,0) [0|0] "" Vector__XXX
 SG_ TEC_MAX : 224|8@1+ (1,0) [0|0] "" Vector__XXX
 SG_ REC_MAX : 232|8@1+ (1,0) [0|0] "" Vector__XXX
 SG_ LEC_SEEN : 240|8@1+ (1,0) [0|0] "" Vector__XXX
 SG_ ERR_PASSIVE_COUNT : 248|8@1+ (1,0) [0|0] "" Vector__XXX

BO_ 1224 MCU1_STATUS_ENCODER_DEBUG: 16 MCU1
 SG_ CRC_ERR_COUNT : 0|16@1+ (1,0) [0|0] "" Vector__XXX
 SG_ ERRFLAG_RAW_COUNT : 16|16@1+ (1,0) [0|0] "" Vector__XXX
 SG_ GLITCH_COUNT : 32|16@1+ (1,0) [0|0] "" Vector__XXX
 SG_ REVERSAL_COUNT : 48|16@1+ (1,0) [0|0] "" Vector__XXX
 SG_ VEL_WOULD_REJECT : 64|16@1+ (1,0) [0|0] "" Vector__XXX
 SG_ VEL_DEV_MAX : 80|12@1+ (1,0) [0|0] "" Vector__XXX
 SG_ ERR_CONSEC_MAX : 96|8@1+ (1,0) [0|0] "" Vector__XXX
 SG_ STANDDOWN_COUNT : 104|8@1+ (1,0) [0|0] "" Vector__XXX
 SG_ RESYNC_BAD_COUNT : 112|8@1+ (1,0) [0|0] "" Vector__XXX

BO_ 1236 MCU1_INFO: 8 MCU1
 SG_ FW_BUILD_UNIX : 0|32@1+ (1,0) [0|0] "" Vector__XXX
 SG_ FW_GIT_SHA : 32|32@1+ (1,0) [0|0] "" Vector__XXX

BO_ 1237 MCU1_PARAMETER_CONTROL: 48 MCU1
 SG_ DIRECTION : 0|1@1+ (1,0) [0|0] "" Vector__XXX
 SG_ MODE : 1|2@1+ (1,0) [0|0] "" Vector__XXX
 SG_ CUR_LOOP_ID_KP : 32|32@1- (1,0) [0|0] "" Vector__XXX
 SG_ CUR_LOOP_ID_KI : 64|32@1- (1,0) [0|0] "" Vector__XXX
 SG_ CUR_LOOP_IQ_KP : 96|32@1- (1,0) [0|0] "" Vector__XXX
 SG_ CUR_LOOP_IQ_KI : 128|32@1- (1,0) [0|0] "" Vector__XXX
 SG_ SPD_LOOP_KP : 160|32@1- (1,0) [0|0] "" Vector__XXX
 SG_ SPD_LOOP_KI : 192|32@1- (1,0) [0|0] "" Vector__XXX
 SG_ FW_KI : 224|32@1- (1,0) [0|0] "" Vector__XXX

BO_ 1238 MCU1_PARAMETER_LIMIT: 48 MCU1
 SG_ CURRENT_LINE_LIMIT : 0|32@1- (1,0) [0|0] "" Vector__XXX
 SG_ CURRENT_ID_LIMIT : 32|32@1- (1,0) [0|0] "" Vector__XXX
 SG_ TORQUE_LIMIT : 64|32@1- (1,0) [0|0] "" Vector__XXX
 SG_ OVER_VOLTAGE_LIMIT : 96|32@1- (1,0) [0|0] "" Vector__XXX
 SG_ UNDER_VOLTAGE_LIMIT : 128|32@1- (1,0) [0|0] "" Vector__XXX
 SG_ VDC_REGEN_BLOCK_SOFT : 160|32@1- (1,0) [0|0] "" Vector__XXX
 SG_ VDC_REGEN_BLOCK_HARD : 192|32@1- (1,0) [0|0] "" Vector__XXX
 SG_ MOTOR_TEMP_LIMIT : 224|32@1- (1,0) [0|0] "" Vector__XXX
 SG_ GATE_TEMP_LIMIT : 256|32@1- (1,0) [0|0] "" Vector__XXX
 SG_ VQ_LIMIT : 288|32@1- (1,0) [0|0] "" Vector__XXX
 SG_ MODULATION_LIMIT : 320|32@1- (1,0) [0|0] "" Vector__XXX

BO_ 1239 MCU1_PARAMETER_OFFSET: 48 MCU1
 SG_ VDC_OFFSET : 0|32@1- (1,0) [0|0] "" Vector__XXX
 SG_ MOTOR_TEMP_OFFSET : 32|32@1- (1,0) [0|0] "" Vector__XXX
 SG_ U_PHASE_TEMP_OFFSET : 64|32@1- (1,0) [0|0] "" Vector__XXX
 SG_ V_PHASE_TEMP_OFFSET : 96|32@1- (1,0) [0|0] "" Vector__XXX
 SG_ W_PHASE_TEMP_OFFSET : 128|32@1- (1,0) [0|0] "" Vector__XXX

BO_ 1240 MCU1_PARAMETER_SLEW_RATE: 48 MCU1
 SG_ TORQUE_SLEW_POS_NM_PER_S : 0|32@1- (1,0) [0|0] "" Vector__XXX
 SG_ TORQUE_SLEW_NEG_NM_PER_S : 32|32@1- (1,0) [0|0] "" Vector__XXX
 SG_ SPEED_SLEW_POS_RPM_PER_S : 64|32@1- (1,0) [0|0] "" Vector__XXX
 SG_ SPEED_SLEW_NEG_RPM_PER_S : 96|32@1- (1,0) [0|0] "" Vector__XXX

BO_ 1249 MCU2_STATUS_SYSTEM: 16 MCU2
 SG_ ENCODER_FAULT : 0|1@1+ (1,0) [0|0] "" Vector__XXX
 SG_ OVP_FAULT : 1|1@1+ (1,0) [0|0] "" Vector__XXX
 SG_ UVP_FAULT : 2|1@1+ (1,0) [0|0] "" Vector__XXX
 SG_ RECV_CTRL_LOSS_FAULT : 3|1@1+ (1,0) [0|0] "" Vector__XXX
 SG_ U_GATE_OTP_FAULT : 4|1@1+ (1,0) [0|0] "" Vector__XXX
 SG_ V_GATE_OTP_FAULT : 5|1@1+ (1,0) [0|0] "" Vector__XXX
 SG_ MOTOR_OTP_FAULT : 6|1@1+ (1,0) [0|0] "" Vector__XXX
 SG_ W_GATE_OTP_FAULT : 7|1@1+ (1,0) [0|0] "" Vector__XXX
 SG_ DIRECTION_STATE : 8|1@1+ (1,0) [0|0] "" Vector__XXX
 SG_ RECV_MODE_BROADCAST_STATE : 9|1@1+ (1,0) [0|0] "" Vector__XXX
 SG_ RECV_MODE_STANDALONE_STATE : 10|1@1+ (1,0) [0|0] "" Vector__XXX
 SG_ FW_EN_ECHO : 11|1@1+ (1,0) [0|0] "" Vector__XXX
 SG_ RUN_MODE_STATE : 12|2@1+ (1,0) [0|0] "" Vector__XXX
 SG_ TORQUE_CMD_ECHO : 16|12@1+ (0.014652,-30) [-30|30] "C" Vector__XXX
 SG_ TORQUE_FB : 28|12@1+ (0.014652,-30) [-30|30] "NM" Vector__XXX
 SG_ VDC_FB : 40|16@1+ (0.0106813,0) [0|700] "V" Vector__XXX
 SG_ POWER_FB : 56|16@1+ (1.22072,-40000) [-40000|40000] "P" Vector__XXX
 SG_ MOTOR_TEMPERATURE_FB : 72|12@1+ (0.0537241,-20) [-20|200] "C" Vector__XXX
 SG_ U_PHASE_TEMPERATURE_FB : 84|12@1+ (0.0537241,-20) [-20|200] "C" Vector__XXX
 SG_ V_PHASE_TEMPERATURE_FB : 96|12@1+ (0.0537241,-20) [-20|200] "C" Vector__XXX
 SG_ W_PHASE_TEMPERATURE_FB : 108|12@1+ (0.0537241,-20) [-20|200] "C" Vector__XXX
 SG_ MCU_HEARTBEAT : 120|8@1+ (1,0) [0|0] "" Vector__XXX

BO_ 1250 MCU2_STATUS_FOC: 12 MCU2
 SG_ IQ_REF : 0|12@1+ (0.0976801,-200) [-200|200] "A" Vector__XXX
 SG_ ID_REF : 12|12@1+ (0.0976801,-200) [-200|200] "A" Vector__XXX
 SG_ ID_FW : 24|12@1+ (0.0976801,-200) [-200|200] "A" Vector__XXX
 SG_ VD_REQ : 36|12@1+ (0.34188,-700) [-700|700] "V" Vector__XXX
 SG_ VQ_REQ : 48|12@1+ (0.34188,-700) [-700|700] "V" Vector__XXX
 SG_ VMAG : 60|12@1+ (0.17094,0) [0|700] "V" Vector__XXX
 SG_ VOUT_MAX : 72|12@1+ (0.17094,0) [0|700] "V" Vector__XXX

BO_ 1251 MCU2_STATUS_DEBUG: 16 MCU2
 SG_ ISR_DURATION_US : 0|8@1+ (0.498039,0) [0|127] "us" Vector__XXX
 SG_ BOOT_COUNT : 8|16@1+ (1,0) [0|65535] "" Vector__XXX
 SG_ ENCODER_ERR_COUNT : 24|16@1+ (1,0) [0|65535] "" Vector__XXX
 SG_ PI_IQ_UI : 40|16@1+ (0.0213626,-700) [-700|700] "" Vector__XXX
 SG_ PI_ID_UI : 56|16@1+ (0.0213626,-700) [-700|700] "" Vector__XXX
 SG_ MCU_ID_STATE : 72|4@1+ (1,0) [0|0] "" Vector__XXX
 SG_ FLASH_LAST_ERROR_STATE : 76|4@1+ (1,0) [0|0] "" Vector__XXX
 SG_ RESET_CAUSE : 80|4@1+ (1,0) [0|0] "" Vector__XXX
 SG_ SOFT_STOP_REASON : 84|4@1+ (1,0) [0|0] "" Vector__XXX
 SG_ UPTIME_S : 88|16@1+ (1,0) [0|65535] "s" Vector__XXX
 SG_ ENCODER_THETA : 104|12@1+ (0.0879121,0) [0|360] "deg" Vector__XXX
 SG_ ENC_MAX_ACCL : 116|12@1+ (1,0) [0|0] "" Vector__XXX

BO_ 1252 MCU2_STATUS_GATE_U: 8 MCU2
 SG_ H_NLSE : 0|1@1+ (1,0) [0|0] "" Vector__XXX
 SG_ H_OVLO2 : 1|1@1+ (1,0) [0|0] "" Vector__XXX
 SG_ H_UVLO2 : 2|1@1+ (1,0) [0|0] "" Vector__XXX
 SG_ H_OVLO3 : 3|1@1+ (1,0) [0|0] "" Vector__XXX
 SG_ H_UVLO3 : 4|1@1+ (1,0) [0|0] "" Vector__XXX
 SG_ H_BDW : 5|1@1+ (1,0) [0|0] "" Vector__XXX
 SG_ H_SASC : 6|1@1+ (1,0) [0|0] "" Vector__XXX
 SG_ H_DTW : 7|1@1+ (1,0) [0|0] "" Vector__XXX
 SG_ H_STPKW : 8|1@1+ (1,0) [0|0] "" Vector__XXX
 SG_ H_OSME : 9|1@1+ (1,0) [0|0] "" Vector__XXX
 SG_ H_GME : 10|1@1+ (1,0) [0|0] "" Vector__XXX
 SG_ H_DDE : 11|1@1+ (1,0) [0|0] "" Vector__XXX
 SG_ H_NDBISTW : 12|1@1+ (1,0) [0|0] "" Vector__XXX
 SG_ H_SASCAW : 13|1@1+ (1,0) [0|0] "" Vector__XXX
 SG_ L_NLSE : 14|1@1+ (1,0) [0|0] "" Vector__XXX
 SG_ L_OVLO2 : 15|1@1+ (1,0) [0|0] "" Vector__XXX
 SG_ L_UVLO2 : 16|1@1+ (1,0) [0|0] "" Vector__XXX
 SG_ L_OVLO3 : 17|1@1+ (1,0) [0|0] "" Vector__XXX
 SG_ L_UVLO3 : 18|1@1+ (1,0) [0|0] "" Vector__XXX
 SG_ L_BDW : 19|1@1+ (1,0) [0|0] "" Vector__XXX
 SG_ L_SASC : 20|1@1+ (1,0) [0|0] "" Vector__XXX
 SG_ L_DTW : 21|1@1+ (1,0) [0|0] "" Vector__XXX
 SG_ L_STPKW : 22|1@1+ (1,0) [0|0] "" Vector__XXX
 SG_ L_OSME : 23|1@1+ (1,0) [0|0] "" Vector__XXX
 SG_ L_GME : 24|1@1+ (1,0) [0|0] "" Vector__XXX
 SG_ L_DDE : 25|1@1+ (1,0) [0|0] "" Vector__XXX
 SG_ L_NDBISTW : 26|1@1+ (1,0) [0|0] "" Vector__XXX
 SG_ L_SASCAW : 27|1@1+ (1,0) [0|0] "" Vector__XXX
 SG_ TEMPERATURE : 32|16@1+ (0.00213626,-20) [-20|120] "" Vector__XXX
 SG_ VOLTAGE : 48|16@1+ (0.0106813,0) [0|700] "" Vector__XXX

BO_ 1253 MCU2_STATUS_GATE_V: 8 MCU2
 SG_ H_NLSE : 0|1@1+ (1,0) [0|0] "" Vector__XXX
 SG_ H_OVLO2 : 1|1@1+ (1,0) [0|0] "" Vector__XXX
 SG_ H_UVLO2 : 2|1@1+ (1,0) [0|0] "" Vector__XXX
 SG_ H_OVLO3 : 3|1@1+ (1,0) [0|0] "" Vector__XXX
 SG_ H_UVLO3 : 4|1@1+ (1,0) [0|0] "" Vector__XXX
 SG_ H_BDW : 5|1@1+ (1,0) [0|0] "" Vector__XXX
 SG_ H_SASC : 6|1@1+ (1,0) [0|0] "" Vector__XXX
 SG_ H_DTW : 7|1@1+ (1,0) [0|0] "" Vector__XXX
 SG_ H_STPKW : 8|1@1+ (1,0) [0|0] "" Vector__XXX
 SG_ H_OSME : 9|1@1+ (1,0) [0|0] "" Vector__XXX
 SG_ H_GME : 10|1@1+ (1,0) [0|0] "" Vector__XXX
 SG_ H_DDE : 11|1@1+ (1,0) [0|0] "" Vector__XXX
 SG_ H_NDBISTW : 12|1@1+ (1,0) [0|0] "" Vector__XXX
 SG_ H_SASCAW : 13|1@1+ (1,0) [0|0] "" Vector__XXX
 SG_ L_NLSE : 14|1@1+ (1,0) [0|0] "" Vector__XXX
 SG_ L_OVLO2 : 15|1@1+ (1,0) [0|0] "" Vector__XXX
 SG_ L_UVLO2 : 16|1@1+ (1,0) [0|0] "" Vector__XXX
 SG_ L_OVLO3 : 17|1@1+ (1,0) [0|0] "" Vector__XXX
 SG_ L_UVLO3 : 18|1@1+ (1,0) [0|0] "" Vector__XXX
 SG_ L_BDW : 19|1@1+ (1,0) [0|0] "" Vector__XXX
 SG_ L_SASC : 20|1@1+ (1,0) [0|0] "" Vector__XXX
 SG_ L_DTW : 21|1@1+ (1,0) [0|0] "" Vector__XXX
 SG_ L_STPKW : 22|1@1+ (1,0) [0|0] "" Vector__XXX
 SG_ L_OSME : 23|1@1+ (1,0) [0|0] "" Vector__XXX
 SG_ L_GME : 24|1@1+ (1,0) [0|0] "" Vector__XXX
 SG_ L_DDE : 25|1@1+ (1,0) [0|0] "" Vector__XXX
 SG_ L_NDBISTW : 26|1@1+ (1,0) [0|0] "" Vector__XXX
 SG_ L_SASCAW : 27|1@1+ (1,0) [0|0] "" Vector__XXX
 SG_ TEMPERATURE : 32|16@1+ (0.00213626,-20) [-20|120] "" Vector__XXX
 SG_ VOLTAGE : 48|16@1+ (0.0106813,0) [0|700] "" Vector__XXX

BO_ 1254 MCU2_STATUS_GATE_W: 8 MCU2
 SG_ H_NLSE : 0|1@1+ (1,0) [0|0] "" Vector__XXX
 SG_ H_OVLO2 : 1|1@1+ (1,0) [0|0] "" Vector__XXX
 SG_ H_UVLO2 : 2|1@1+ (1,0) [0|0] "" Vector__XXX
 SG_ H_OVLO3 : 3|1@1+ (1,0) [0|0] "" Vector__XXX
 SG_ H_UVLO3 : 4|1@1+ (1,0) [0|0] "" Vector__XXX
 SG_ H_BDW : 5|1@1+ (1,0) [0|0] "" Vector__XXX
 SG_ H_SASC : 6|1@1+ (1,0) [0|0] "" Vector__XXX
 SG_ H_DTW : 7|1@1+ (1,0) [0|0] "" Vector__XXX
 SG_ H_STPKW : 8|1@1+ (1,0) [0|0] "" Vector__XXX
 SG_ H_OSME : 9|1@1+ (1,0) [0|0] "" Vector__XXX
 SG_ H_GME : 10|1@1+ (1,0) [0|0] "" Vector__XXX
 SG_ H_DDE : 11|1@1+ (1,0) [0|0] "" Vector__XXX
 SG_ H_NDBISTW : 12|1@1+ (1,0) [0|0] "" Vector__XXX
 SG_ H_SASCAW : 13|1@1+ (1,0) [0|0] "" Vector__XXX
 SG_ L_NLSE : 14|1@1+ (1,0) [0|0] "" Vector__XXX
 SG_ L_OVLO2 : 15|1@1+ (1,0) [0|0] "" Vector__XXX
 SG_ L_UVLO2 : 16|1@1+ (1,0) [0|0] "" Vector__XXX
 SG_ L_OVLO3 : 17|1@1+ (1,0) [0|0] "" Vector__XXX
 SG_ L_UVLO3 : 18|1@1+ (1,0) [0|0] "" Vector__XXX
 SG_ L_BDW : 19|1@1+ (1,0) [0|0] "" Vector__XXX
 SG_ L_SASC : 20|1@1+ (1,0) [0|0] "" Vector__XXX
 SG_ L_DTW : 21|1@1+ (1,0) [0|0] "" Vector__XXX
 SG_ L_STPKW : 22|1@1+ (1,0) [0|0] "" Vector__XXX
 SG_ L_OSME : 23|1@1+ (1,0) [0|0] "" Vector__XXX
 SG_ L_GME : 24|1@1+ (1,0) [0|0] "" Vector__XXX
 SG_ L_DDE : 25|1@1+ (1,0) [0|0] "" Vector__XXX
 SG_ L_NDBISTW : 26|1@1+ (1,0) [0|0] "" Vector__XXX
 SG_ L_SASCAW : 27|1@1+ (1,0) [0|0] "" Vector__XXX
 SG_ TEMPERATURE : 32|16@1+ (0.00213626,-20) [-20|120] "" Vector__XXX
 SG_ VOLTAGE : 48|16@1+ (0.0106813,0) [0|700] "" Vector__XXX

BO_ 1255 MCU2_STATUS_COMM: 32 MCU2
 SG_ CMD_MISS_CONSEC_AVG : 0|16@1+ (0.000762951,0) [0|50] "" Vector__XXX
 SG_ CMD_MISS_CONSEC_MAX : 16|16@1+ (1,0) [0|0] "" Vector__XXX
 SG_ CMD_GAP_MS_AVG : 32|16@1+ (0.0015259,0) [0|100] "ms" Vector__XXX
 SG_ CMD_GAP_MS_MAX : 48|16@1+ (0.0015259,0) [0|100] "ms" Vector__XXX
 SG_ RX_QUEUE_DROP_COUNT : 64|16@1+ (1,0) [0|0] "" Vector__XXX
 SG_ BUS_OFF_COUNT : 80|16@1+ (1,0) [0|0] "" Vector__XXX
 SG_ TEC : 96|16@1+ (1,0) [0|0] "" Vector__XXX
 SG_ REC : 112|16@1+ (1,0) [0|0] "" Vector__XXX
 SG_ TX_FRAME_COUNT : 128|32@1+ (1,0) [0|0] "" Vector__XXX
 SG_ TX_DROP_COUNT : 160|16@1+ (1,0) [0|0] "" Vector__XXX
 SG_ TX_STALL_MAX_MS : 176|16@1+ (1,0) [0|0] "" Vector__XXX
 SG_ CEL_TOTAL : 192|16@1+ (1,0) [0|0] "" Vector__XXX
 SG_ RX_DEAF_MAX_MS : 208|16@1+ (1,0) [0|0] "" Vector__XXX
 SG_ TEC_MAX : 224|8@1+ (1,0) [0|0] "" Vector__XXX
 SG_ REC_MAX : 232|8@1+ (1,0) [0|0] "" Vector__XXX
 SG_ LEC_SEEN : 240|8@1+ (1,0) [0|0] "" Vector__XXX
 SG_ ERR_PASSIVE_COUNT : 248|8@1+ (1,0) [0|0] "" Vector__XXX

BO_ 1256 MCU2_STATUS_ENCODER_DEBUG: 16 MCU2
 SG_ CRC_ERR_COUNT : 0|16@1+ (1,0) [0|0] "" Vector__XXX
 SG_ ERRFLAG_RAW_COUNT : 16|16@1+ (1,0) [0|0] "" Vector__XXX
 SG_ GLITCH_COUNT : 32|16@1+ (1,0) [0|0] "" Vector__XXX
 SG_ REVERSAL_COUNT : 48|16@1+ (1,0) [0|0] "" Vector__XXX
 SG_ VEL_WOULD_REJECT : 64|16@1+ (1,0) [0|0] "" Vector__XXX
 SG_ VEL_DEV_MAX : 80|12@1+ (1,0) [0|0] "" Vector__XXX
 SG_ ERR_CONSEC_MAX : 96|8@1+ (1,0) [0|0] "" Vector__XXX
 SG_ STANDDOWN_COUNT : 104|8@1+ (1,0) [0|0] "" Vector__XXX
 SG_ RESYNC_BAD_COUNT : 112|8@1+ (1,0) [0|0] "" Vector__XXX

BO_ 1268 MCU2_INFO: 8 MCU2
 SG_ FW_BUILD_UNIX : 0|32@1+ (1,0) [0|0] "" Vector__XXX
 SG_ FW_GIT_SHA : 32|32@1+ (1,0) [0|0] "" Vector__XXX

BO_ 1269 MCU2_PARAMETER_CONTROL: 48 MCU2
 SG_ DIRECTION : 0|1@1+ (1,0) [0|0] "" Vector__XXX
 SG_ MODE : 1|2@1+ (1,0) [0|0] "" Vector__XXX
 SG_ CUR_LOOP_ID_KP : 32|32@1- (1,0) [0|0] "" Vector__XXX
 SG_ CUR_LOOP_ID_KI : 64|32@1- (1,0) [0|0] "" Vector__XXX
 SG_ CUR_LOOP_IQ_KP : 96|32@1- (1,0) [0|0] "" Vector__XXX
 SG_ CUR_LOOP_IQ_KI : 128|32@1- (1,0) [0|0] "" Vector__XXX
 SG_ SPD_LOOP_KP : 160|32@1- (1,0) [0|0] "" Vector__XXX
 SG_ SPD_LOOP_KI : 192|32@1- (1,0) [0|0] "" Vector__XXX
 SG_ FW_KI : 224|32@1- (1,0) [0|0] "" Vector__XXX

BO_ 1270 MCU2_PARAMETER_LIMIT: 48 MCU2
 SG_ CURRENT_LINE_LIMIT : 0|32@1- (1,0) [0|0] "" Vector__XXX
 SG_ CURRENT_ID_LIMIT : 32|32@1- (1,0) [0|0] "" Vector__XXX
 SG_ TORQUE_LIMIT : 64|32@1- (1,0) [0|0] "" Vector__XXX
 SG_ OVER_VOLTAGE_LIMIT : 96|32@1- (1,0) [0|0] "" Vector__XXX
 SG_ UNDER_VOLTAGE_LIMIT : 128|32@1- (1,0) [0|0] "" Vector__XXX
 SG_ VDC_REGEN_BLOCK_SOFT : 160|32@1- (1,0) [0|0] "" Vector__XXX
 SG_ VDC_REGEN_BLOCK_HARD : 192|32@1- (1,0) [0|0] "" Vector__XXX
 SG_ MOTOR_TEMP_LIMIT : 224|32@1- (1,0) [0|0] "" Vector__XXX
 SG_ GATE_TEMP_LIMIT : 256|32@1- (1,0) [0|0] "" Vector__XXX
 SG_ VQ_LIMIT : 288|32@1- (1,0) [0|0] "" Vector__XXX
 SG_ MODULATION_LIMIT : 320|32@1- (1,0) [0|0] "" Vector__XXX

BO_ 1271 MCU2_PARAMETER_OFFSET: 48 MCU2
 SG_ VDC_OFFSET : 0|32@1- (1,0) [0|0] "" Vector__XXX
 SG_ MOTOR_TEMP_OFFSET : 32|32@1- (1,0) [0|0] "" Vector__XXX
 SG_ U_PHASE_TEMP_OFFSET : 64|32@1- (1,0) [0|0] "" Vector__XXX
 SG_ V_PHASE_TEMP_OFFSET : 96|32@1- (1,0) [0|0] "" Vector__XXX
 SG_ W_PHASE_TEMP_OFFSET : 128|32@1- (1,0) [0|0] "" Vector__XXX

BO_ 1272 MCU2_PARAMETER_SLEW_RATE: 48 MCU2
 SG_ TORQUE_SLEW_POS_NM_PER_S : 0|32@1- (1,0) [0|0] "" Vector__XXX
 SG_ TORQUE_SLEW_NEG_NM_PER_S : 32|32@1- (1,0) [0|0] "" Vector__XXX
 SG_ SPEED_SLEW_POS_RPM_PER_S : 64|32@1- (1,0) [0|0] "" Vector__XXX
 SG_ SPEED_SLEW_NEG_RPM_PER_S : 96|32@1- (1,0) [0|0] "" Vector__XXX

BO_ 1281 MCU3_STATUS_SYSTEM: 16 MCU3
 SG_ ENCODER_FAULT : 0|1@1+ (1,0) [0|0] "" Vector__XXX
 SG_ OVP_FAULT : 1|1@1+ (1,0) [0|0] "" Vector__XXX
 SG_ UVP_FAULT : 2|1@1+ (1,0) [0|0] "" Vector__XXX
 SG_ RECV_CTRL_LOSS_FAULT : 3|1@1+ (1,0) [0|0] "" Vector__XXX
 SG_ U_GATE_OTP_FAULT : 4|1@1+ (1,0) [0|0] "" Vector__XXX
 SG_ V_GATE_OTP_FAULT : 5|1@1+ (1,0) [0|0] "" Vector__XXX
 SG_ MOTOR_OTP_FAULT : 6|1@1+ (1,0) [0|0] "" Vector__XXX
 SG_ W_GATE_OTP_FAULT : 7|1@1+ (1,0) [0|0] "" Vector__XXX
 SG_ DIRECTION_STATE : 8|1@1+ (1,0) [0|0] "" Vector__XXX
 SG_ RECV_MODE_BROADCAST_STATE : 9|1@1+ (1,0) [0|0] "" Vector__XXX
 SG_ RECV_MODE_STANDALONE_STATE : 10|1@1+ (1,0) [0|0] "" Vector__XXX
 SG_ FW_EN_ECHO : 11|1@1+ (1,0) [0|0] "" Vector__XXX
 SG_ RUN_MODE_STATE : 12|2@1+ (1,0) [0|0] "" Vector__XXX
 SG_ TORQUE_CMD_ECHO : 16|12@1+ (0.014652,-30) [-30|30] "C" Vector__XXX
 SG_ TORQUE_FB : 28|12@1+ (0.014652,-30) [-30|30] "NM" Vector__XXX
 SG_ VDC_FB : 40|16@1+ (0.0106813,0) [0|700] "V" Vector__XXX
 SG_ POWER_FB : 56|16@1+ (1.22072,-40000) [-40000|40000] "P" Vector__XXX
 SG_ MOTOR_TEMPERATURE_FB : 72|12@1+ (0.0537241,-20) [-20|200] "C" Vector__XXX
 SG_ U_PHASE_TEMPERATURE_FB : 84|12@1+ (0.0537241,-20) [-20|200] "C" Vector__XXX
 SG_ V_PHASE_TEMPERATURE_FB : 96|12@1+ (0.0537241,-20) [-20|200] "C" Vector__XXX
 SG_ W_PHASE_TEMPERATURE_FB : 108|12@1+ (0.0537241,-20) [-20|200] "C" Vector__XXX
 SG_ MCU_HEARTBEAT : 120|8@1+ (1,0) [0|0] "" Vector__XXX

BO_ 1282 MCU3_STATUS_FOC: 12 MCU3
 SG_ IQ_REF : 0|12@1+ (0.0976801,-200) [-200|200] "A" Vector__XXX
 SG_ ID_REF : 12|12@1+ (0.0976801,-200) [-200|200] "A" Vector__XXX
 SG_ ID_FW : 24|12@1+ (0.0976801,-200) [-200|200] "A" Vector__XXX
 SG_ VD_REQ : 36|12@1+ (0.34188,-700) [-700|700] "V" Vector__XXX
 SG_ VQ_REQ : 48|12@1+ (0.34188,-700) [-700|700] "V" Vector__XXX
 SG_ VMAG : 60|12@1+ (0.17094,0) [0|700] "V" Vector__XXX
 SG_ VOUT_MAX : 72|12@1+ (0.17094,0) [0|700] "V" Vector__XXX

BO_ 1283 MCU3_STATUS_DEBUG: 16 MCU3
 SG_ ISR_DURATION_US : 0|8@1+ (0.498039,0) [0|127] "us" Vector__XXX
 SG_ BOOT_COUNT : 8|16@1+ (1,0) [0|65535] "" Vector__XXX
 SG_ ENCODER_ERR_COUNT : 24|16@1+ (1,0) [0|65535] "" Vector__XXX
 SG_ PI_IQ_UI : 40|16@1+ (0.0213626,-700) [-700|700] "" Vector__XXX
 SG_ PI_ID_UI : 56|16@1+ (0.0213626,-700) [-700|700] "" Vector__XXX
 SG_ MCU_ID_STATE : 72|4@1+ (1,0) [0|0] "" Vector__XXX
 SG_ FLASH_LAST_ERROR_STATE : 76|4@1+ (1,0) [0|0] "" Vector__XXX
 SG_ RESET_CAUSE : 80|4@1+ (1,0) [0|0] "" Vector__XXX
 SG_ SOFT_STOP_REASON : 84|4@1+ (1,0) [0|0] "" Vector__XXX
 SG_ UPTIME_S : 88|16@1+ (1,0) [0|65535] "s" Vector__XXX
 SG_ ENCODER_THETA : 104|12@1+ (0.0879121,0) [0|360] "deg" Vector__XXX
 SG_ ENC_MAX_ACCL : 116|12@1+ (1,0) [0|0] "" Vector__XXX

BO_ 1284 MCU3_STATUS_GATE_U: 8 MCU3
 SG_ H_NLSE : 0|1@1+ (1,0) [0|0] "" Vector__XXX
 SG_ H_OVLO2 : 1|1@1+ (1,0) [0|0] "" Vector__XXX
 SG_ H_UVLO2 : 2|1@1+ (1,0) [0|0] "" Vector__XXX
 SG_ H_OVLO3 : 3|1@1+ (1,0) [0|0] "" Vector__XXX
 SG_ H_UVLO3 : 4|1@1+ (1,0) [0|0] "" Vector__XXX
 SG_ H_BDW : 5|1@1+ (1,0) [0|0] "" Vector__XXX
 SG_ H_SASC : 6|1@1+ (1,0) [0|0] "" Vector__XXX
 SG_ H_DTW : 7|1@1+ (1,0) [0|0] "" Vector__XXX
 SG_ H_STPKW : 8|1@1+ (1,0) [0|0] "" Vector__XXX
 SG_ H_OSME : 9|1@1+ (1,0) [0|0] "" Vector__XXX
 SG_ H_GME : 10|1@1+ (1,0) [0|0] "" Vector__XXX
 SG_ H_DDE : 11|1@1+ (1,0) [0|0] "" Vector__XXX
 SG_ H_NDBISTW : 12|1@1+ (1,0) [0|0] "" Vector__XXX
 SG_ H_SASCAW : 13|1@1+ (1,0) [0|0] "" Vector__XXX
 SG_ L_NLSE : 14|1@1+ (1,0) [0|0] "" Vector__XXX
 SG_ L_OVLO2 : 15|1@1+ (1,0) [0|0] "" Vector__XXX
 SG_ L_UVLO2 : 16|1@1+ (1,0) [0|0] "" Vector__XXX
 SG_ L_OVLO3 : 17|1@1+ (1,0) [0|0] "" Vector__XXX
 SG_ L_UVLO3 : 18|1@1+ (1,0) [0|0] "" Vector__XXX
 SG_ L_BDW : 19|1@1+ (1,0) [0|0] "" Vector__XXX
 SG_ L_SASC : 20|1@1+ (1,0) [0|0] "" Vector__XXX
 SG_ L_DTW : 21|1@1+ (1,0) [0|0] "" Vector__XXX
 SG_ L_STPKW : 22|1@1+ (1,0) [0|0] "" Vector__XXX
 SG_ L_OSME : 23|1@1+ (1,0) [0|0] "" Vector__XXX
 SG_ L_GME : 24|1@1+ (1,0) [0|0] "" Vector__XXX
 SG_ L_DDE : 25|1@1+ (1,0) [0|0] "" Vector__XXX
 SG_ L_NDBISTW : 26|1@1+ (1,0) [0|0] "" Vector__XXX
 SG_ L_SASCAW : 27|1@1+ (1,0) [0|0] "" Vector__XXX
 SG_ TEMPERATURE : 32|16@1+ (0.00213626,-20) [-20|120] "" Vector__XXX
 SG_ VOLTAGE : 48|16@1+ (0.0106813,0) [0|700] "" Vector__XXX

BO_ 1285 MCU3_STATUS_GATE_V: 8 MCU3
 SG_ H_NLSE : 0|1@1+ (1,0) [0|0] "" Vector__XXX
 SG_ H_OVLO2 : 1|1@1+ (1,0) [0|0] "" Vector__XXX
 SG_ H_UVLO2 : 2|1@1+ (1,0) [0|0] "" Vector__XXX
 SG_ H_OVLO3 : 3|1@1+ (1,0) [0|0] "" Vector__XXX
 SG_ H_UVLO3 : 4|1@1+ (1,0) [0|0] "" Vector__XXX
 SG_ H_BDW : 5|1@1+ (1,0) [0|0] "" Vector__XXX
 SG_ H_SASC : 6|1@1+ (1,0) [0|0] "" Vector__XXX
 SG_ H_DTW : 7|1@1+ (1,0) [0|0] "" Vector__XXX
 SG_ H_STPKW : 8|1@1+ (1,0) [0|0] "" Vector__XXX
 SG_ H_OSME : 9|1@1+ (1,0) [0|0] "" Vector__XXX
 SG_ H_GME : 10|1@1+ (1,0) [0|0] "" Vector__XXX
 SG_ H_DDE : 11|1@1+ (1,0) [0|0] "" Vector__XXX
 SG_ H_NDBISTW : 12|1@1+ (1,0) [0|0] "" Vector__XXX
 SG_ H_SASCAW : 13|1@1+ (1,0) [0|0] "" Vector__XXX
 SG_ L_NLSE : 14|1@1+ (1,0) [0|0] "" Vector__XXX
 SG_ L_OVLO2 : 15|1@1+ (1,0) [0|0] "" Vector__XXX
 SG_ L_UVLO2 : 16|1@1+ (1,0) [0|0] "" Vector__XXX
 SG_ L_OVLO3 : 17|1@1+ (1,0) [0|0] "" Vector__XXX
 SG_ L_UVLO3 : 18|1@1+ (1,0) [0|0] "" Vector__XXX
 SG_ L_BDW : 19|1@1+ (1,0) [0|0] "" Vector__XXX
 SG_ L_SASC : 20|1@1+ (1,0) [0|0] "" Vector__XXX
 SG_ L_DTW : 21|1@1+ (1,0) [0|0] "" Vector__XXX
 SG_ L_STPKW : 22|1@1+ (1,0) [0|0] "" Vector__XXX
 SG_ L_OSME : 23|1@1+ (1,0) [0|0] "" Vector__XXX
 SG_ L_GME : 24|1@1+ (1,0) [0|0] "" Vector__XXX
 SG_ L_DDE : 25|1@1+ (1,0) [0|0] "" Vector__XXX
 SG_ L_NDBISTW : 26|1@1+ (1,0) [0|0] "" Vector__XXX
 SG_ L_SASCAW : 27|1@1+ (1,0) [0|0] "" Vector__XXX
 SG_ TEMPERATURE : 32|16@1+ (0.00213626,-20) [-20|120] "" Vector__XXX
 SG_ VOLTAGE : 48|16@1+ (0.0106813,0) [0|700] "" Vector__XXX

BO_ 1286 MCU3_STATUS_GATE_W: 8 MCU3
 SG_ H_NLSE : 0|1@1+ (1,0) [0|0] "" Vector__XXX
 SG_ H_OVLO2 : 1|1@1+ (1,0) [0|0] "" Vector__XXX
 SG_ H_UVLO2 : 2|1@1+ (1,0) [0|0] "" Vector__XXX
 SG_ H_OVLO3 : 3|1@1+ (1,0) [0|0] "" Vector__XXX
 SG_ H_UVLO3 : 4|1@1+ (1,0) [0|0] "" Vector__XXX
 SG_ H_BDW : 5|1@1+ (1,0) [0|0] "" Vector__XXX
 SG_ H_SASC : 6|1@1+ (1,0) [0|0] "" Vector__XXX
 SG_ H_DTW : 7|1@1+ (1,0) [0|0] "" Vector__XXX
 SG_ H_STPKW : 8|1@1+ (1,0) [0|0] "" Vector__XXX
 SG_ H_OSME : 9|1@1+ (1,0) [0|0] "" Vector__XXX
 SG_ H_GME : 10|1@1+ (1,0) [0|0] "" Vector__XXX
 SG_ H_DDE : 11|1@1+ (1,0) [0|0] "" Vector__XXX
 SG_ H_NDBISTW : 12|1@1+ (1,0) [0|0] "" Vector__XXX
 SG_ H_SASCAW : 13|1@1+ (1,0) [0|0] "" Vector__XXX
 SG_ L_NLSE : 14|1@1+ (1,0) [0|0] "" Vector__XXX
 SG_ L_OVLO2 : 15|1@1+ (1,0) [0|0] "" Vector__XXX
 SG_ L_UVLO2 : 16|1@1+ (1,0) [0|0] "" Vector__XXX
 SG_ L_OVLO3 : 17|1@1+ (1,0) [0|0] "" Vector__XXX
 SG_ L_UVLO3 : 18|1@1+ (1,0) [0|0] "" Vector__XXX
 SG_ L_BDW : 19|1@1+ (1,0) [0|0] "" Vector__XXX
 SG_ L_SASC : 20|1@1+ (1,0) [0|0] "" Vector__XXX
 SG_ L_DTW : 21|1@1+ (1,0) [0|0] "" Vector__XXX
 SG_ L_STPKW : 22|1@1+ (1,0) [0|0] "" Vector__XXX
 SG_ L_OSME : 23|1@1+ (1,0) [0|0] "" Vector__XXX
 SG_ L_GME : 24|1@1+ (1,0) [0|0] "" Vector__XXX
 SG_ L_DDE : 25|1@1+ (1,0) [0|0] "" Vector__XXX
 SG_ L_NDBISTW : 26|1@1+ (1,0) [0|0] "" Vector__XXX
 SG_ L_SASCAW : 27|1@1+ (1,0) [0|0] "" Vector__XXX
 SG_ TEMPERATURE : 32|16@1+ (0.00213626,-20) [-20|120] "" Vector__XXX
 SG_ VOLTAGE : 48|16@1+ (0.0106813,0) [0|700] "" Vector__XXX

BO_ 1287 MCU3_STATUS_COMM: 32 MCU3
 SG_ CMD_MISS_CONSEC_AVG : 0|16@1+ (0.000762951,0) [0|50] "" Vector__XXX
 SG_ CMD_MISS_CONSEC_MAX : 16|16@1+ (1,0) [0|0] "" Vector__XXX
 SG_ CMD_GAP_MS_AVG : 32|16@1+ (0.0015259,0) [0|100] "ms" Vector__XXX
 SG_ CMD_GAP_MS_MAX : 48|16@1+ (0.0015259,0) [0|100] "ms" Vector__XXX
 SG_ RX_QUEUE_DROP_COUNT : 64|16@1+ (1,0) [0|0] "" Vector__XXX
 SG_ BUS_OFF_COUNT : 80|16@1+ (1,0) [0|0] "" Vector__XXX
 SG_ TEC : 96|16@1+ (1,0) [0|0] "" Vector__XXX
 SG_ REC : 112|16@1+ (1,0) [0|0] "" Vector__XXX
 SG_ TX_FRAME_COUNT : 128|32@1+ (1,0) [0|0] "" Vector__XXX
 SG_ TX_DROP_COUNT : 160|16@1+ (1,0) [0|0] "" Vector__XXX
 SG_ TX_STALL_MAX_MS : 176|16@1+ (1,0) [0|0] "" Vector__XXX
 SG_ CEL_TOTAL : 192|16@1+ (1,0) [0|0] "" Vector__XXX
 SG_ RX_DEAF_MAX_MS : 208|16@1+ (1,0) [0|0] "" Vector__XXX
 SG_ TEC_MAX : 224|8@1+ (1,0) [0|0] "" Vector__XXX
 SG_ REC_MAX : 232|8@1+ (1,0) [0|0] "" Vector__XXX
 SG_ LEC_SEEN : 240|8@1+ (1,0) [0|0] "" Vector__XXX
 SG_ ERR_PASSIVE_COUNT : 248|8@1+ (1,0) [0|0] "" Vector__XXX

BO_ 1288 MCU3_STATUS_ENCODER_DEBUG: 16 MCU3
 SG_ CRC_ERR_COUNT : 0|16@1+ (1,0) [0|0] "" Vector__XXX
 SG_ ERRFLAG_RAW_COUNT : 16|16@1+ (1,0) [0|0] "" Vector__XXX
 SG_ GLITCH_COUNT : 32|16@1+ (1,0) [0|0] "" Vector__XXX
 SG_ REVERSAL_COUNT : 48|16@1+ (1,0) [0|0] "" Vector__XXX
 SG_ VEL_WOULD_REJECT : 64|16@1+ (1,0) [0|0] "" Vector__XXX
 SG_ VEL_DEV_MAX : 80|12@1+ (1,0) [0|0] "" Vector__XXX
 SG_ ERR_CONSEC_MAX : 96|8@1+ (1,0) [0|0] "" Vector__XXX
 SG_ STANDDOWN_COUNT : 104|8@1+ (1,0) [0|0] "" Vector__XXX
 SG_ RESYNC_BAD_COUNT : 112|8@1+ (1,0) [0|0] "" Vector__XXX

BO_ 1300 MCU3_INFO: 8 MCU3
 SG_ FW_BUILD_UNIX : 0|32@1+ (1,0) [0|0] "" Vector__XXX
 SG_ FW_GIT_SHA : 32|32@1+ (1,0) [0|0] "" Vector__XXX

BO_ 1301 MCU3_PARAMETER_CONTROL: 48 MCU3
 SG_ DIRECTION : 0|1@1+ (1,0) [0|0] "" Vector__XXX
 SG_ MODE : 1|2@1+ (1,0) [0|0] "" Vector__XXX
 SG_ CUR_LOOP_ID_KP : 32|32@1- (1,0) [0|0] "" Vector__XXX
 SG_ CUR_LOOP_ID_KI : 64|32@1- (1,0) [0|0] "" Vector__XXX
 SG_ CUR_LOOP_IQ_KP : 96|32@1- (1,0) [0|0] "" Vector__XXX
 SG_ CUR_LOOP_IQ_KI : 128|32@1- (1,0) [0|0] "" Vector__XXX
 SG_ SPD_LOOP_KP : 160|32@1- (1,0) [0|0] "" Vector__XXX
 SG_ SPD_LOOP_KI : 192|32@1- (1,0) [0|0] "" Vector__XXX
 SG_ FW_KI : 224|32@1- (1,0) [0|0] "" Vector__XXX

BO_ 1302 MCU3_PARAMETER_LIMIT: 48 MCU3
 SG_ CURRENT_LINE_LIMIT : 0|32@1- (1,0) [0|0] "" Vector__XXX
 SG_ CURRENT_ID_LIMIT : 32|32@1- (1,0) [0|0] "" Vector__XXX
 SG_ TORQUE_LIMIT : 64|32@1- (1,0) [0|0] "" Vector__XXX
 SG_ OVER_VOLTAGE_LIMIT : 96|32@1- (1,0) [0|0] "" Vector__XXX
 SG_ UNDER_VOLTAGE_LIMIT : 128|32@1- (1,0) [0|0] "" Vector__XXX
 SG_ VDC_REGEN_BLOCK_SOFT : 160|32@1- (1,0) [0|0] "" Vector__XXX
 SG_ VDC_REGEN_BLOCK_HARD : 192|32@1- (1,0) [0|0] "" Vector__XXX
 SG_ MOTOR_TEMP_LIMIT : 224|32@1- (1,0) [0|0] "" Vector__XXX
 SG_ GATE_TEMP_LIMIT : 256|32@1- (1,0) [0|0] "" Vector__XXX
 SG_ VQ_LIMIT : 288|32@1- (1,0) [0|0] "" Vector__XXX
 SG_ MODULATION_LIMIT : 320|32@1- (1,0) [0|0] "" Vector__XXX

BO_ 1303 MCU3_PARAMETER_OFFSET: 48 MCU3
 SG_ VDC_OFFSET : 0|32@1- (1,0) [0|0] "" Vector__XXX
 SG_ MOTOR_TEMP_OFFSET : 32|32@1- (1,0) [0|0] "" Vector__XXX
 SG_ U_PHASE_TEMP_OFFSET : 64|32@1- (1,0) [0|0] "" Vector__XXX
 SG_ V_PHASE_TEMP_OFFSET : 96|32@1- (1,0) [0|0] "" Vector__XXX
 SG_ W_PHASE_TEMP_OFFSET : 128|32@1- (1,0) [0|0] "" Vector__XXX

BO_ 1304 MCU3_PARAMETER_SLEW_RATE: 48 MCU3
 SG_ TORQUE_SLEW_POS_NM_PER_S : 0|32@1- (1,0) [0|0] "" Vector__XXX
 SG_ TORQUE_SLEW_NEG_NM_PER_S : 32|32@1- (1,0) [0|0] "" Vector__XXX
 SG_ SPEED_SLEW_POS_RPM_PER_S : 64|32@1- (1,0) [0|0] "" Vector__XXX
 SG_ SPEED_SLEW_NEG_RPM_PER_S : 96|32@1- (1,0) [0|0] "" Vector__XXX

BO_ 1313 MCU4_STATUS_SYSTEM: 16 MCU4
 SG_ ENCODER_FAULT : 0|1@1+ (1,0) [0|0] "" Vector__XXX
 SG_ OVP_FAULT : 1|1@1+ (1,0) [0|0] "" Vector__XXX
 SG_ UVP_FAULT : 2|1@1+ (1,0) [0|0] "" Vector__XXX
 SG_ RECV_CTRL_LOSS_FAULT : 3|1@1+ (1,0) [0|0] "" Vector__XXX
 SG_ U_GATE_OTP_FAULT : 4|1@1+ (1,0) [0|0] "" Vector__XXX
 SG_ V_GATE_OTP_FAULT : 5|1@1+ (1,0) [0|0] "" Vector__XXX
 SG_ MOTOR_OTP_FAULT : 6|1@1+ (1,0) [0|0] "" Vector__XXX
 SG_ W_GATE_OTP_FAULT : 7|1@1+ (1,0) [0|0] "" Vector__XXX
 SG_ DIRECTION_STATE : 8|1@1+ (1,0) [0|0] "" Vector__XXX
 SG_ RECV_MODE_BROADCAST_STATE : 9|1@1+ (1,0) [0|0] "" Vector__XXX
 SG_ RECV_MODE_STANDALONE_STATE : 10|1@1+ (1,0) [0|0] "" Vector__XXX
 SG_ FW_EN_ECHO : 11|1@1+ (1,0) [0|0] "" Vector__XXX
 SG_ RUN_MODE_STATE : 12|2@1+ (1,0) [0|0] "" Vector__XXX
 SG_ TORQUE_CMD_ECHO : 16|12@1+ (0.014652,-30) [-30|30] "C" Vector__XXX
 SG_ TORQUE_FB : 28|12@1+ (0.014652,-30) [-30|30] "NM" Vector__XXX
 SG_ VDC_FB : 40|16@1+ (0.0106813,0) [0|700] "V" Vector__XXX
 SG_ POWER_FB : 56|16@1+ (1.22072,-40000) [-40000|40000] "P" Vector__XXX
 SG_ MOTOR_TEMPERATURE_FB : 72|12@1+ (0.0537241,-20) [-20|200] "C" Vector__XXX
 SG_ U_PHASE_TEMPERATURE_FB : 84|12@1+ (0.0537241,-20) [-20|200] "C" Vector__XXX
 SG_ V_PHASE_TEMPERATURE_FB : 96|12@1+ (0.0537241,-20) [-20|200] "C" Vector__XXX
 SG_ W_PHASE_TEMPERATURE_FB : 108|12@1+ (0.0537241,-20) [-20|200] "C" Vector__XXX
 SG_ MCU_HEARTBEAT : 120|8@1+ (1,0) [0|0] "" Vector__XXX

BO_ 1314 MCU4_STATUS_FOC: 12 MCU4
 SG_ IQ_REF : 0|12@1+ (0.0976801,-200) [-200|200] "A" Vector__XXX
 SG_ ID_REF : 12|12@1+ (0.0976801,-200) [-200|200] "A" Vector__XXX
 SG_ ID_FW : 24|12@1+ (0.0976801,-200) [-200|200] "A" Vector__XXX
 SG_ VD_REQ : 36|12@1+ (0.34188,-700) [-700|700] "V" Vector__XXX
 SG_ VQ_REQ : 48|12@1+ (0.34188,-700) [-700|700] "V" Vector__XXX
 SG_ VMAG : 60|12@1+ (0.17094,0) [0|700] "V" Vector__XXX
 SG_ VOUT_MAX : 72|12@1+ (0.17094,0) [0|700] "V" Vector__XXX

BO_ 1315 MCU4_STATUS_DEBUG: 16 MCU4
 SG_ ISR_DURATION_US : 0|8@1+ (0.498039,0) [0|127] "us" Vector__XXX
 SG_ BOOT_COUNT : 8|16@1+ (1,0) [0|65535] "" Vector__XXX
 SG_ ENCODER_ERR_COUNT : 24|16@1+ (1,0) [0|65535] "" Vector__XXX
 SG_ PI_IQ_UI : 40|16@1+ (0.0213626,-700) [-700|700] "" Vector__XXX
 SG_ PI_ID_UI : 56|16@1+ (0.0213626,-700) [-700|700] "" Vector__XXX
 SG_ MCU_ID_STATE : 72|4@1+ (1,0) [0|0] "" Vector__XXX
 SG_ FLASH_LAST_ERROR_STATE : 76|4@1+ (1,0) [0|0] "" Vector__XXX
 SG_ RESET_CAUSE : 80|4@1+ (1,0) [0|0] "" Vector__XXX
 SG_ SOFT_STOP_REASON : 84|4@1+ (1,0) [0|0] "" Vector__XXX
 SG_ UPTIME_S : 88|16@1+ (1,0) [0|65535] "s" Vector__XXX
 SG_ ENCODER_THETA : 104|12@1+ (0.0879121,0) [0|360] "deg" Vector__XXX
 SG_ ENC_MAX_ACCL : 116|12@1+ (1,0) [0|0] "" Vector__XXX

BO_ 1316 MCU4_STATUS_GATE_U: 8 MCU4
 SG_ H_NLSE : 0|1@1+ (1,0) [0|0] "" Vector__XXX
 SG_ H_OVLO2 : 1|1@1+ (1,0) [0|0] "" Vector__XXX
 SG_ H_UVLO2 : 2|1@1+ (1,0) [0|0] "" Vector__XXX
 SG_ H_OVLO3 : 3|1@1+ (1,0) [0|0] "" Vector__XXX
 SG_ H_UVLO3 : 4|1@1+ (1,0) [0|0] "" Vector__XXX
 SG_ H_BDW : 5|1@1+ (1,0) [0|0] "" Vector__XXX
 SG_ H_SASC : 6|1@1+ (1,0) [0|0] "" Vector__XXX
 SG_ H_DTW : 7|1@1+ (1,0) [0|0] "" Vector__XXX
 SG_ H_STPKW : 8|1@1+ (1,0) [0|0] "" Vector__XXX
 SG_ H_OSME : 9|1@1+ (1,0) [0|0] "" Vector__XXX
 SG_ H_GME : 10|1@1+ (1,0) [0|0] "" Vector__XXX
 SG_ H_DDE : 11|1@1+ (1,0) [0|0] "" Vector__XXX
 SG_ H_NDBISTW : 12|1@1+ (1,0) [0|0] "" Vector__XXX
 SG_ H_SASCAW : 13|1@1+ (1,0) [0|0] "" Vector__XXX
 SG_ L_NLSE : 14|1@1+ (1,0) [0|0] "" Vector__XXX
 SG_ L_OVLO2 : 15|1@1+ (1,0) [0|0] "" Vector__XXX
 SG_ L_UVLO2 : 16|1@1+ (1,0) [0|0] "" Vector__XXX
 SG_ L_OVLO3 : 17|1@1+ (1,0) [0|0] "" Vector__XXX
 SG_ L_UVLO3 : 18|1@1+ (1,0) [0|0] "" Vector__XXX
 SG_ L_BDW : 19|1@1+ (1,0) [0|0] "" Vector__XXX
 SG_ L_SASC : 20|1@1+ (1,0) [0|0] "" Vector__XXX
 SG_ L_DTW : 21|1@1+ (1,0) [0|0] "" Vector__XXX
 SG_ L_STPKW : 22|1@1+ (1,0) [0|0] "" Vector__XXX
 SG_ L_OSME : 23|1@1+ (1,0) [0|0] "" Vector__XXX
 SG_ L_GME : 24|1@1+ (1,0) [0|0] "" Vector__XXX
 SG_ L_DDE : 25|1@1+ (1,0) [0|0] "" Vector__XXX
 SG_ L_NDBISTW : 26|1@1+ (1,0) [0|0] "" Vector__XXX
 SG_ L_SASCAW : 27|1@1+ (1,0) [0|0] "" Vector__XXX
 SG_ TEMPERATURE : 32|16@1+ (0.00213626,-20) [-20|120] "" Vector__XXX
 SG_ VOLTAGE : 48|16@1+ (0.0106813,0) [0|700] "" Vector__XXX

BO_ 1317 MCU4_STATUS_GATE_V: 8 MCU4
 SG_ H_NLSE : 0|1@1+ (1,0) [0|0] "" Vector__XXX
 SG_ H_OVLO2 : 1|1@1+ (1,0) [0|0] "" Vector__XXX
 SG_ H_UVLO2 : 2|1@1+ (1,0) [0|0] "" Vector__XXX
 SG_ H_OVLO3 : 3|1@1+ (1,0) [0|0] "" Vector__XXX
 SG_ H_UVLO3 : 4|1@1+ (1,0) [0|0] "" Vector__XXX
 SG_ H_BDW : 5|1@1+ (1,0) [0|0] "" Vector__XXX
 SG_ H_SASC : 6|1@1+ (1,0) [0|0] "" Vector__XXX
 SG_ H_DTW : 7|1@1+ (1,0) [0|0] "" Vector__XXX
 SG_ H_STPKW : 8|1@1+ (1,0) [0|0] "" Vector__XXX
 SG_ H_OSME : 9|1@1+ (1,0) [0|0] "" Vector__XXX
 SG_ H_GME : 10|1@1+ (1,0) [0|0] "" Vector__XXX
 SG_ H_DDE : 11|1@1+ (1,0) [0|0] "" Vector__XXX
 SG_ H_NDBISTW : 12|1@1+ (1,0) [0|0] "" Vector__XXX
 SG_ H_SASCAW : 13|1@1+ (1,0) [0|0] "" Vector__XXX
 SG_ L_NLSE : 14|1@1+ (1,0) [0|0] "" Vector__XXX
 SG_ L_OVLO2 : 15|1@1+ (1,0) [0|0] "" Vector__XXX
 SG_ L_UVLO2 : 16|1@1+ (1,0) [0|0] "" Vector__XXX
 SG_ L_OVLO3 : 17|1@1+ (1,0) [0|0] "" Vector__XXX
 SG_ L_UVLO3 : 18|1@1+ (1,0) [0|0] "" Vector__XXX
 SG_ L_BDW : 19|1@1+ (1,0) [0|0] "" Vector__XXX
 SG_ L_SASC : 20|1@1+ (1,0) [0|0] "" Vector__XXX
 SG_ L_DTW : 21|1@1+ (1,0) [0|0] "" Vector__XXX
 SG_ L_STPKW : 22|1@1+ (1,0) [0|0] "" Vector__XXX
 SG_ L_OSME : 23|1@1+ (1,0) [0|0] "" Vector__XXX
 SG_ L_GME : 24|1@1+ (1,0) [0|0] "" Vector__XXX
 SG_ L_DDE : 25|1@1+ (1,0) [0|0] "" Vector__XXX
 SG_ L_NDBISTW : 26|1@1+ (1,0) [0|0] "" Vector__XXX
 SG_ L_SASCAW : 27|1@1+ (1,0) [0|0] "" Vector__XXX
 SG_ TEMPERATURE : 32|16@1+ (0.00213626,-20) [-20|120] "" Vector__XXX
 SG_ VOLTAGE : 48|16@1+ (0.0106813,0) [0|700] "" Vector__XXX

BO_ 1318 MCU4_STATUS_GATE_W: 8 MCU4
 SG_ H_NLSE : 0|1@1+ (1,0) [0|0] "" Vector__XXX
 SG_ H_OVLO2 : 1|1@1+ (1,0) [0|0] "" Vector__XXX
 SG_ H_UVLO2 : 2|1@1+ (1,0) [0|0] "" Vector__XXX
 SG_ H_OVLO3 : 3|1@1+ (1,0) [0|0] "" Vector__XXX
 SG_ H_UVLO3 : 4|1@1+ (1,0) [0|0] "" Vector__XXX
 SG_ H_BDW : 5|1@1+ (1,0) [0|0] "" Vector__XXX
 SG_ H_SASC : 6|1@1+ (1,0) [0|0] "" Vector__XXX
 SG_ H_DTW : 7|1@1+ (1,0) [0|0] "" Vector__XXX
 SG_ H_STPKW : 8|1@1+ (1,0) [0|0] "" Vector__XXX
 SG_ H_OSME : 9|1@1+ (1,0) [0|0] "" Vector__XXX
 SG_ H_GME : 10|1@1+ (1,0) [0|0] "" Vector__XXX
 SG_ H_DDE : 11|1@1+ (1,0) [0|0] "" Vector__XXX
 SG_ H_NDBISTW : 12|1@1+ (1,0) [0|0] "" Vector__XXX
 SG_ H_SASCAW : 13|1@1+ (1,0) [0|0] "" Vector__XXX
 SG_ L_NLSE : 14|1@1+ (1,0) [0|0] "" Vector__XXX
 SG_ L_OVLO2 : 15|1@1+ (1,0) [0|0] "" Vector__XXX
 SG_ L_UVLO2 : 16|1@1+ (1,0) [0|0] "" Vector__XXX
 SG_ L_OVLO3 : 17|1@1+ (1,0) [0|0] "" Vector__XXX
 SG_ L_UVLO3 : 18|1@1+ (1,0) [0|0] "" Vector__XXX
 SG_ L_BDW : 19|1@1+ (1,0) [0|0] "" Vector__XXX
 SG_ L_SASC : 20|1@1+ (1,0) [0|0] "" Vector__XXX
 SG_ L_DTW : 21|1@1+ (1,0) [0|0] "" Vector__XXX
 SG_ L_STPKW : 22|1@1+ (1,0) [0|0] "" Vector__XXX
 SG_ L_OSME : 23|1@1+ (1,0) [0|0] "" Vector__XXX
 SG_ L_GME : 24|1@1+ (1,0) [0|0] "" Vector__XXX
 SG_ L_DDE : 25|1@1+ (1,0) [0|0] "" Vector__XXX
 SG_ L_NDBISTW : 26|1@1+ (1,0) [0|0] "" Vector__XXX
 SG_ L_SASCAW : 27|1@1+ (1,0) [0|0] "" Vector__XXX
 SG_ TEMPERATURE : 32|16@1+ (0.00213626,-20) [-20|120] "" Vector__XXX
 SG_ VOLTAGE : 48|16@1+ (0.0106813,0) [0|700] "" Vector__XXX

BO_ 1319 MCU4_STATUS_COMM: 32 MCU4
 SG_ CMD_MISS_CONSEC_AVG : 0|16@1+ (0.000762951,0) [0|50] "" Vector__XXX
 SG_ CMD_MISS_CONSEC_MAX : 16|16@1+ (1,0) [0|0] "" Vector__XXX
 SG_ CMD_GAP_MS_AVG : 32|16@1+ (0.0015259,0) [0|100] "ms" Vector__XXX
 SG_ CMD_GAP_MS_MAX : 48|16@1+ (0.0015259,0) [0|100] "ms" Vector__XXX
 SG_ RX_QUEUE_DROP_COUNT : 64|16@1+ (1,0) [0|0] "" Vector__XXX
 SG_ BUS_OFF_COUNT : 80|16@1+ (1,0) [0|0] "" Vector__XXX
 SG_ TEC : 96|16@1+ (1,0) [0|0] "" Vector__XXX
 SG_ REC : 112|16@1+ (1,0) [0|0] "" Vector__XXX
 SG_ TX_FRAME_COUNT : 128|32@1+ (1,0) [0|0] "" Vector__XXX
 SG_ TX_DROP_COUNT : 160|16@1+ (1,0) [0|0] "" Vector__XXX
 SG_ TX_STALL_MAX_MS : 176|16@1+ (1,0) [0|0] "" Vector__XXX
 SG_ CEL_TOTAL : 192|16@1+ (1,0) [0|0] "" Vector__XXX
 SG_ RX_DEAF_MAX_MS : 208|16@1+ (1,0) [0|0] "" Vector__XXX
 SG_ TEC_MAX : 224|8@1+ (1,0) [0|0] "" Vector__XXX
 SG_ REC_MAX : 232|8@1+ (1,0) [0|0] "" Vector__XXX
 SG_ LEC_SEEN : 240|8@1+ (1,0) [0|0] "" Vector__XXX
 SG_ ERR_PASSIVE_COUNT : 248|8@1+ (1,0) [0|0] "" Vector__XXX

BO_ 1320 MCU4_STATUS_ENCODER_DEBUG: 16 MCU4
 SG_ CRC_ERR_COUNT : 0|16@1+ (1,0) [0|0] "" Vector__XXX
 SG_ ERRFLAG_RAW_COUNT : 16|16@1+ (1,0) [0|0] "" Vector__XXX
 SG_ GLITCH_COUNT : 32|16@1+ (1,0) [0|0] "" Vector__XXX
 SG_ REVERSAL_COUNT : 48|16@1+ (1,0) [0|0] "" Vector__XXX
 SG_ VEL_WOULD_REJECT : 64|16@1+ (1,0) [0|0] "" Vector__XXX
 SG_ VEL_DEV_MAX : 80|12@1+ (1,0) [0|0] "" Vector__XXX
 SG_ ERR_CONSEC_MAX : 96|8@1+ (1,0) [0|0] "" Vector__XXX
 SG_ STANDDOWN_COUNT : 104|8@1+ (1,0) [0|0] "" Vector__XXX
 SG_ RESYNC_BAD_COUNT : 112|8@1+ (1,0) [0|0] "" Vector__XXX

BO_ 1332 MCU4_INFO: 8 MCU4
 SG_ FW_BUILD_UNIX : 0|32@1+ (1,0) [0|0] "" Vector__XXX
 SG_ FW_GIT_SHA : 32|32@1+ (1,0) [0|0] "" Vector__XXX

BO_ 1333 MCU4_PARAMETER_CONTROL: 48 MCU4
 SG_ DIRECTION : 0|1@1+ (1,0) [0|0] "" Vector__XXX
 SG_ MODE : 1|2@1+ (1,0) [0|0] "" Vector__XXX
 SG_ CUR_LOOP_ID_KP : 32|32@1- (1,0) [0|0] "" Vector__XXX
 SG_ CUR_LOOP_ID_KI : 64|32@1- (1,0) [0|0] "" Vector__XXX
 SG_ CUR_LOOP_IQ_KP : 96|32@1- (1,0) [0|0] "" Vector__XXX
 SG_ CUR_LOOP_IQ_KI : 128|32@1- (1,0) [0|0] "" Vector__XXX
 SG_ SPD_LOOP_KP : 160|32@1- (1,0) [0|0] "" Vector__XXX
 SG_ SPD_LOOP_KI : 192|32@1- (1,0) [0|0] "" Vector__XXX
 SG_ FW_KI : 224|32@1- (1,0) [0|0] "" Vector__XXX

BO_ 1334 MCU4_PARAMETER_LIMIT: 48 MCU4
 SG_ CURRENT_LINE_LIMIT : 0|32@1- (1,0) [0|0] "" Vector__XXX
 SG_ CURRENT_ID_LIMIT : 32|32@1- (1,0) [0|0] "" Vector__XXX
 SG_ TORQUE_LIMIT : 64|32@1- (1,0) [0|0] "" Vector__XXX
 SG_ OVER_VOLTAGE_LIMIT : 96|32@1- (1,0) [0|0] "" Vector__XXX
 SG_ UNDER_VOLTAGE_LIMIT : 128|32@1- (1,0) [0|0] "" Vector__XXX
 SG_ VDC_REGEN_BLOCK_SOFT : 160|32@1- (1,0) [0|0] "" Vector__XXX
 SG_ VDC_REGEN_BLOCK_HARD : 192|32@1- (1,0) [0|0] "" Vector__XXX
 SG_ MOTOR_TEMP_LIMIT : 224|32@1- (1,0) [0|0] "" Vector__XXX
 SG_ GATE_TEMP_LIMIT : 256|32@1- (1,0) [0|0] "" Vector__XXX
 SG_ VQ_LIMIT : 288|32@1- (1,0) [0|0] "" Vector__XXX
 SG_ MODULATION_LIMIT : 320|32@1- (1,0) [0|0] "" Vector__XXX

BO_ 1335 MCU4_PARAMETER_OFFSET: 48 MCU4
 SG_ VDC_OFFSET : 0|32@1- (1,0) [0|0] "" Vector__XXX
 SG_ MOTOR_TEMP_OFFSET : 32|32@1- (1,0) [0|0] "" Vector__XXX
 SG_ U_PHASE_TEMP_OFFSET : 64|32@1- (1,0) [0|0] "" Vector__XXX
 SG_ V_PHASE_TEMP_OFFSET : 96|32@1- (1,0) [0|0] "" Vector__XXX
 SG_ W_PHASE_TEMP_OFFSET : 128|32@1- (1,0) [0|0] "" Vector__XXX

BO_ 1336 MCU4_PARAMETER_SLEW_RATE: 48 MCU4
 SG_ TORQUE_SLEW_POS_NM_PER_S : 0|32@1- (1,0) [0|0] "" Vector__XXX
 SG_ TORQUE_SLEW_NEG_NM_PER_S : 32|32@1- (1,0) [0|0] "" Vector__XXX
 SG_ SPEED_SLEW_POS_RPM_PER_S : 64|32@1- (1,0) [0|0] "" Vector__XXX
 SG_ SPEED_SLEW_NEG_RPM_PER_S : 96|32@1- (1,0) [0|0] "" Vector__XXX

BO_ 1408 IMU_FRONT_IMU_FRONT_QUATERNION: 8 IMU_FRONT

BO_ 1409 IMU_FRONT_IMU_FRONT_RATEOFTURN: 8 IMU_FRONT

BO_ 1410 IMU_FRONT_IMU_FRONT_ACCELERATION: 8 IMU_FRONT

CM_ SG_ 192 SYS_LIMIT_ACTIVE "System is in limit (derate..etc)";
CM_ SG_ 192 SYS_FAULT "when system is in fault";
CM_ SG_ 192 VOLTAGE_SAT_ACTIVE "Motor saturated";
CM_ SG_ 224 SYS_LIMIT_ACTIVE "System is in limit (derate..etc)";
CM_ SG_ 224 SYS_FAULT "when system is in fault";
CM_ SG_ 224 VOLTAGE_SAT_ACTIVE "Motor saturated";
CM_ SG_ 256 SYS_LIMIT_ACTIVE "System is in limit (derate..etc)";
CM_ SG_ 256 SYS_FAULT "when system is in fault";
CM_ SG_ 256 VOLTAGE_SAT_ACTIVE "Motor saturated";
CM_ SG_ 288 SYS_LIMIT_ACTIVE "System is in limit (derate..etc)";
CM_ SG_ 288 SYS_FAULT "when system is in fault";
CM_ SG_ 288 VOLTAGE_SAT_ACTIVE "Motor saturated";
CM_ BO_ 1066 "Reserved in current firmware; transmitted as zero-filled frame.";
CM_ BO_ 1067 "DycPidDiag packed diagnostics. Fault and diag mask bytes are expanded into bit Flags like other status messages; byte1 IMU source, byte3 enable fade, followed by scaled uint16 diagnostic values.";
CM_ SG_ 1067 DYC_FAULT_VX "DycPidFaultStatus.bits.vx; speed estimate invalid.";
CM_ SG_ 1067 DYC_FAULT_IMU "DycPidFaultStatus.bits.imu; IMU signal invalid or unavailable.";
CM_ SG_ 1067 DYC_FAULT_STEERING "DycPidFaultStatus.bits.steering; steering signal invalid.";
CM_ SG_ 1067 DYC_FAULT_YAW_RATE "DycPidFaultStatus.bits.yaw_rate; yaw-rate plausibility fault.";
CM_ SG_ 1067 DYC_FAULT_AY "DycPidFaultStatus.bits.ay; lateral acceleration plausibility fault.";
CM_ SG_ 1067 DYC_FAULT_AY_YAWRATE "DycPidFaultStatus.bits.ay_yawrate; ay and vx*yaw-rate consistency fault.";
CM_ SG_ 1067 DYC_IMU_SOURCE "DycPidImuSource used for this step.";
CM_ SG_ 1067 DYC_VX_VALID "DycPidDiagFlags.bits.vx_valid.";
CM_ SG_ 1067 DYC_LOW_SPEED "DycPidDiagFlags.bits.low_speed.";
CM_ SG_ 1067 DYC_ALLOWED "DycPidDiagFlags.bits.dyc_allowed.";
CM_ SG_ 1067 DYC_CONTROL_ACTIVE "DycPidDiagFlags.bits.control_active.";
CM_ SG_ 1067 DYC_ALLOCATOR_SATURATED "DycPidDiagFlags.bits.allocator_saturated.";
CM_ SG_ 1067 DYC_FORWARD_MOTION "DycPidDiagFlags.bits.allocator_saturated.";
CM_ SG_ 1067 DYC_ZERO_THROTTLE "DycPidDiagFlags.bits.allocator_saturated.";
CM_ SG_ 1067 DYC_NEGATIVE_TORQUE_ACTIVE "DycPidDiagFlags.bits.allocator_saturated.";
CM_ SG_ 1067 DYC_PID_ENABLE_FADE "diag.pid_enable_fade encoded as uint8 scale 1/255. Range updated from DYC_CONTROLLER_INTEGRATION_GUIDE.md.";
CM_ SG_ 1067 DYC_ACCEL_CG_X_MPS2 "diag.accel_cg_x_mps2 Range updated from DYC_CONTROLLER_INTEGRATION_GUIDE.md.";
CM_ SG_ 1067 DYC_ACCEL_CG_Y_MPS2 "diag.accel_cg_y_mps2 Range updated from DYC_CONTROLLER_INTEGRATION_GUIDE.md.";
CM_ SG_ 1067 DYC_STEER_EQ_RAD "diag.steer_eq_rad Range updated from DYC_CONTROLLER_INTEGRATION_GUIDE.md.";
CM_ SG_ 1067 DYC_STEER_LEFT_RAD "diag.steer_left_rad Range updated from DYC_CONTROLLER_INTEGRATION_GUIDE.md.";
CM_ SG_ 1067 DYC_STEER_RIGHT_RAD "diag.steer_right_rad Range updated from DYC_CONTROLLER_INTEGRATION_GUIDE.md.";
CM_ SG_ 1067 DYC_YAW_RATE_REF_FILT_RADPS "diag.yaw_rate_ref_filt_radps Range updated from DYC_CONTROLLER_INTEGRATION_GUIDE.md.";
CM_ SG_ 1067 DYC_YAW_RATE_REF_RAW_RADPS "diag.yaw_rate_ref_raw_radps Range updated from DYC_CONTROLLER_INTEGRATION_GUIDE.md.";
CM_ SG_ 1067 DYC_YAW_ERROR_RADPS "diag.yaw_error_radps Range updated from DYC_CONTROLLER_INTEGRATION_GUIDE.md.";
CM_ SG_ 1067 DYC_MZ_CMD_NM "diag.mz_cmd_nm Range updated from DYC_CONTROLLER_INTEGRATION_GUIDE.md.";
CM_ SG_ 1067 DYC_APPLIED_MZ_NM "diag.applied_mz_nm Range updated from DYC_CONTROLLER_INTEGRATION_GUIDE.md.";
CM_ SG_ 1067 DYC_BASE_TORQUE_SUM_NM "diag.base_torque_sum_nm Range updated from DYC_CONTROLLER_INTEGRATION_GUIDE.md.";
CM_ SG_ 1067 DYC_WHEEL_SPEED_AVG_MPS "diag.wheel_speed_avg_mps Range updated from DYC_CONTROLLER_INTEGRATION_GUIDE.md.";
CM_ SG_ 1067 DYC_TORQUE_DELTA_FL_NM "diag.torque_delta_fl_nm Range updated from DYC_CONTROLLER_INTEGRATION_GUIDE.md.";
CM_ SG_ 1067 DYC_TORQUE_DELTA_FR_NM "diag.torque_delta_fr_nm Range updated from DYC_CONTROLLER_INTEGRATION_GUIDE.md.";
CM_ SG_ 1067 DYC_TORQUE_DELTA_RL_NM "diag.torque_delta_rl_nm Range updated from DYC_CONTROLLER_INTEGRATION_GUIDE.md.";
CM_ SG_ 1067 DYC_TORQUE_DELTA_RR_NM "diag.torque_delta_rr_nm Range updated from DYC_CONTROLLER_INTEGRATION_GUIDE.md.";
CM_ SG_ 1067 DYC_TORQUE_FL_NM "diag.torque_delta_fl_nm Range updated from DYC_CONTROLLER_INTEGRATION_GUIDE.md.";
CM_ SG_ 1067 DYC_TORQUE_FR_NM "diag.torque_delta_fr_nm Range updated from DYC_CONTROLLER_INTEGRATION_GUIDE.md.";
CM_ SG_ 1067 DYC_TORQUE_RL_NM "diag.torque_delta_rl_nm Range updated from DYC_CONTROLLER_INTEGRATION_GUIDE.md.";
CM_ SG_ 1067 DYC_TORQUE_RR_NM "diag.torque_delta_rr_nm Range updated from DYC_CONTROLLER_INTEGRATION_GUIDE.md.";
BA_DEF_ "BusType" STRING ;
BA_DEF_ BO_ "GenMsgCycleTime" INT 0 65535;
BA_DEF_ BO_ "VFrameFormat" ENUM  "StandardCAN","ExtendedCAN","reserved","J1939PG","reserved","reserved","reserved","reserved","reserved","reserved","reserved","reserved","reserved","reserved","StandardCAN_FD","ExtendedCAN_FD";
BA_DEF_DEF_ "BusType" "CAN FD";
BA_DEF_DEF_ "GenMsgCycleTime" 0;
BA_DEF_DEF_ "VFrameFormat" "StandardCAN";
BA_ "GenMsgCycleTime" BO_ 32 4;
BA_ "VFrameFormat" BO_ 32 14;
BA_ "VFrameFormat" BO_ 96 14;
BA_ "GenMsgCycleTime" BO_ 192 4;
BA_ "VFrameFormat" BO_ 192 14;
BA_ "GenMsgCycleTime" BO_ 224 4;
BA_ "VFrameFormat" BO_ 224 14;
BA_ "GenMsgCycleTime" BO_ 256 4;
BA_ "VFrameFormat" BO_ 256 14;
BA_ "GenMsgCycleTime" BO_ 288 4;
BA_ "VFrameFormat" BO_ 288 14;
BA_ "VFrameFormat" BO_ 640 14;
BA_ "VFrameFormat" BO_ 641 14;
BA_ "VFrameFormat" BO_ 642 14;
BA_ "VFrameFormat" BO_ 643 14;
BA_ "VFrameFormat" BO_ 644 14;
BA_ "VFrameFormat" BO_ 645 14;
BA_ "VFrameFormat" BO_ 646 14;
BA_ "VFrameFormat" BO_ 647 14;
BA_ "VFrameFormat" BO_ 648 14;
BA_ "VFrameFormat" BO_ 649 14;
BA_ "VFrameFormat" BO_ 650 14;
BA_ "VFrameFormat" BO_ 651 14;
BA_ "VFrameFormat" BO_ 652 14;
BA_ "VFrameFormat" BO_ 653 14;
BA_ "VFrameFormat" BO_ 654 14;
BA_ "VFrameFormat" BO_ 655 14;
BA_ "VFrameFormat" BO_ 656 14;
BA_ "VFrameFormat" BO_ 657 14;
BA_ "VFrameFormat" BO_ 658 14;
BA_ "VFrameFormat" BO_ 659 14;
BA_ "GenMsgCycleTime" BO_ 660 1000;
BA_ "VFrameFormat" BO_ 660 14;
BA_ "GenMsgCycleTime" BO_ 661 1000;
BA_ "VFrameFormat" BO_ 661 14;
BA_ "GenMsgCycleTime" BO_ 662 1000;
BA_ "VFrameFormat" BO_ 662 14;
BA_ "GenMsgCycleTime" BO_ 663 1000;
BA_ "VFrameFormat" BO_ 663 14;
BA_ "VFrameFormat" BO_ 664 14;
BA_ "GenMsgCycleTime" BO_ 1056 10;
BA_ "VFrameFormat" BO_ 1056 14;
BA_ "GenMsgCycleTime" BO_ 1057 10;
BA_ "VFrameFormat" BO_ 1057 14;
BA_ "GenMsgCycleTime" BO_ 1058 20;
BA_ "VFrameFormat" BO_ 1058 14;
BA_ "GenMsgCycleTime" BO_ 1059 20;
BA_ "VFrameFormat" BO_ 1059 14;
BA_ "GenMsgCycleTime" BO_ 1060 50;
BA_ "VFrameFormat" BO_ 1060 14;
BA_ "GenMsgCycleTime" BO_ 1061 100;
BA_ "VFrameFormat" BO_ 1061 14;
BA_ "GenMsgCycleTime" BO_ 1062 10;
BA_ "VFrameFormat" BO_ 1062 14;
BA_ "GenMsgCycleTime" BO_ 1063 100;
BA_ "VFrameFormat" BO_ 1063 14;
BA_ "GenMsgCycleTime" BO_ 1066 100;
BA_ "VFrameFormat" BO_ 1066 14;
BA_ "GenMsgCycleTime" BO_ 1067 10;
BA_ "VFrameFormat" BO_ 1067 14;
BA_ "GenMsgCycleTime" BO_ 1071 50;
BA_ "VFrameFormat" BO_ 1071 14;
BA_ "GenMsgCycleTime" BO_ 1072 6;
BA_ "VFrameFormat" BO_ 1072 14;
BA_ "GenMsgCycleTime" BO_ 1073 6;
BA_ "VFrameFormat" BO_ 1073 14;
BA_ "GenMsgCycleTime" BO_ 1074 100;
BA_ "VFrameFormat" BO_ 1074 14;
BA_ "GenMsgCycleTime" BO_ 1077 6;
BA_ "VFrameFormat" BO_ 1077 14;
BA_ "GenMsgCycleTime" BO_ 1079 6;
BA_ "VFrameFormat" BO_ 1079 14;
BA_ "GenMsgCycleTime" BO_ 1080 6;
BA_ "VFrameFormat" BO_ 1080 14;
BA_ "GenMsgCycleTime" BO_ 1082 100;
BA_ "VFrameFormat" BO_ 1082 14;
BA_ "GenMsgCycleTime" BO_ 1084 100;
BA_ "VFrameFormat" BO_ 1084 14;
BA_ "GenMsgCycleTime" BO_ 1085 100;
BA_ "VFrameFormat" BO_ 1085 14;
BA_ "GenMsgCycleTime" BO_ 1086 100;
BA_ "VFrameFormat" BO_ 1086 14;
BA_ "GenMsgCycleTime" BO_ 1087 100;
BA_ "VFrameFormat" BO_ 1087 14;
BA_ "GenMsgCycleTime" BO_ 1088 20;
BA_ "VFrameFormat" BO_ 1088 14;
BA_ "GenMsgCycleTime" BO_ 1089 20;
BA_ "VFrameFormat" BO_ 1089 14;
BA_ "GenMsgCycleTime" BO_ 1098 20;
BA_ "VFrameFormat" BO_ 1098 14;
BA_ "GenMsgCycleTime" BO_ 1099 20;
BA_ "VFrameFormat" BO_ 1099 14;
BA_ "GenMsgCycleTime" BO_ 1100 20;
BA_ "VFrameFormat" BO_ 1100 14;
BA_ "GenMsgCycleTime" BO_ 1101 20;
BA_ "VFrameFormat" BO_ 1101 14;
BA_ "GenMsgCycleTime" BO_ 1102 20;
BA_ "VFrameFormat" BO_ 1102 14;
BA_ "GenMsgCycleTime" BO_ 1103 20;
BA_ "VFrameFormat" BO_ 1103 14;
BA_ "GenMsgCycleTime" BO_ 1104 20;
BA_ "VFrameFormat" BO_ 1104 14;
BA_ "GenMsgCycleTime" BO_ 1105 20;
BA_ "VFrameFormat" BO_ 1105 14;
BA_ "GenMsgCycleTime" BO_ 1108 100;
BA_ "VFrameFormat" BO_ 1108 14;
BA_ "GenMsgCycleTime" BO_ 1217 10;
BA_ "VFrameFormat" BO_ 1217 14;
BA_ "GenMsgCycleTime" BO_ 1218 10;
BA_ "VFrameFormat" BO_ 1218 14;
BA_ "GenMsgCycleTime" BO_ 1219 50;
BA_ "VFrameFormat" BO_ 1219 14;
BA_ "GenMsgCycleTime" BO_ 1220 100;
BA_ "VFrameFormat" BO_ 1220 14;
BA_ "GenMsgCycleTime" BO_ 1221 100;
BA_ "VFrameFormat" BO_ 1221 14;
BA_ "GenMsgCycleTime" BO_ 1222 100;
BA_ "VFrameFormat" BO_ 1222 14;
BA_ "GenMsgCycleTime" BO_ 1223 100;
BA_ "VFrameFormat" BO_ 1223 14;
BA_ "GenMsgCycleTime" BO_ 1224 100;
BA_ "VFrameFormat" BO_ 1224 14;
BA_ "GenMsgCycleTime" BO_ 1236 1000;
BA_ "VFrameFormat" BO_ 1236 14;
BA_ "GenMsgCycleTime" BO_ 1237 1000;
BA_ "VFrameFormat" BO_ 1237 14;
BA_ "GenMsgCycleTime" BO_ 1238 1000;
BA_ "VFrameFormat" BO_ 1238 14;
BA_ "GenMsgCycleTime" BO_ 1239 1000;
BA_ "VFrameFormat" BO_ 1239 14;
BA_ "GenMsgCycleTime" BO_ 1240 1000;
BA_ "VFrameFormat" BO_ 1240 14;
BA_ "GenMsgCycleTime" BO_ 1249 10;
BA_ "VFrameFormat" BO_ 1249 14;
BA_ "GenMsgCycleTime" BO_ 1250 10;
BA_ "VFrameFormat" BO_ 1250 14;
BA_ "GenMsgCycleTime" BO_ 1251 50;
BA_ "VFrameFormat" BO_ 1251 14;
BA_ "GenMsgCycleTime" BO_ 1252 100;
BA_ "VFrameFormat" BO_ 1252 14;
BA_ "GenMsgCycleTime" BO_ 1253 100;
BA_ "VFrameFormat" BO_ 1253 14;
BA_ "GenMsgCycleTime" BO_ 1254 100;
BA_ "VFrameFormat" BO_ 1254 14;
BA_ "GenMsgCycleTime" BO_ 1255 100;
BA_ "VFrameFormat" BO_ 1255 14;
BA_ "GenMsgCycleTime" BO_ 1256 100;
BA_ "VFrameFormat" BO_ 1256 14;
BA_ "GenMsgCycleTime" BO_ 1268 1000;
BA_ "VFrameFormat" BO_ 1268 14;
BA_ "GenMsgCycleTime" BO_ 1269 1000;
BA_ "VFrameFormat" BO_ 1269 14;
BA_ "GenMsgCycleTime" BO_ 1270 1000;
BA_ "VFrameFormat" BO_ 1270 14;
BA_ "GenMsgCycleTime" BO_ 1271 1000;
BA_ "VFrameFormat" BO_ 1271 14;
BA_ "GenMsgCycleTime" BO_ 1272 1000;
BA_ "VFrameFormat" BO_ 1272 14;
BA_ "GenMsgCycleTime" BO_ 1281 10;
BA_ "VFrameFormat" BO_ 1281 14;
BA_ "GenMsgCycleTime" BO_ 1282 10;
BA_ "VFrameFormat" BO_ 1282 14;
BA_ "GenMsgCycleTime" BO_ 1283 50;
BA_ "VFrameFormat" BO_ 1283 14;
BA_ "GenMsgCycleTime" BO_ 1284 100;
BA_ "VFrameFormat" BO_ 1284 14;
BA_ "GenMsgCycleTime" BO_ 1285 100;
BA_ "VFrameFormat" BO_ 1285 14;
BA_ "GenMsgCycleTime" BO_ 1286 100;
BA_ "VFrameFormat" BO_ 1286 14;
BA_ "GenMsgCycleTime" BO_ 1287 100;
BA_ "VFrameFormat" BO_ 1287 14;
BA_ "GenMsgCycleTime" BO_ 1288 100;
BA_ "VFrameFormat" BO_ 1288 14;
BA_ "GenMsgCycleTime" BO_ 1300 1000;
BA_ "VFrameFormat" BO_ 1300 14;
BA_ "GenMsgCycleTime" BO_ 1301 1000;
BA_ "VFrameFormat" BO_ 1301 14;
BA_ "GenMsgCycleTime" BO_ 1302 1000;
BA_ "VFrameFormat" BO_ 1302 14;
BA_ "GenMsgCycleTime" BO_ 1303 1000;
BA_ "VFrameFormat" BO_ 1303 14;
BA_ "GenMsgCycleTime" BO_ 1304 1000;
BA_ "VFrameFormat" BO_ 1304 14;
BA_ "GenMsgCycleTime" BO_ 1313 10;
BA_ "VFrameFormat" BO_ 1313 14;
BA_ "GenMsgCycleTime" BO_ 1314 10;
BA_ "VFrameFormat" BO_ 1314 14;
BA_ "GenMsgCycleTime" BO_ 1315 50;
BA_ "VFrameFormat" BO_ 1315 14;
BA_ "GenMsgCycleTime" BO_ 1316 100;
BA_ "VFrameFormat" BO_ 1316 14;
BA_ "GenMsgCycleTime" BO_ 1317 100;
BA_ "VFrameFormat" BO_ 1317 14;
BA_ "GenMsgCycleTime" BO_ 1318 100;
BA_ "VFrameFormat" BO_ 1318 14;
BA_ "GenMsgCycleTime" BO_ 1319 100;
BA_ "VFrameFormat" BO_ 1319 14;
BA_ "GenMsgCycleTime" BO_ 1320 100;
BA_ "VFrameFormat" BO_ 1320 14;
BA_ "GenMsgCycleTime" BO_ 1332 1000;
BA_ "VFrameFormat" BO_ 1332 14;
BA_ "GenMsgCycleTime" BO_ 1333 1000;
BA_ "VFrameFormat" BO_ 1333 14;
BA_ "GenMsgCycleTime" BO_ 1334 1000;
BA_ "VFrameFormat" BO_ 1334 14;
BA_ "GenMsgCycleTime" BO_ 1335 1000;
BA_ "VFrameFormat" BO_ 1335 14;
BA_ "GenMsgCycleTime" BO_ 1336 1000;
BA_ "VFrameFormat" BO_ 1336 14;
BA_ "GenMsgCycleTime" BO_ 1408 3;
BA_ "VFrameFormat" BO_ 1408 14;
BA_ "GenMsgCycleTime" BO_ 1409 3;
BA_ "VFrameFormat" BO_ 1409 14;
BA_ "GenMsgCycleTime" BO_ 1410 3;
BA_ "VFrameFormat" BO_ 1410 14;
VAL_ 32 SYS_EN_CMD 0 "False" 1 "True";
VAL_ 32 SYS_RESET_CMD 0 "False" 1 "True";
VAL_ 32 FW_EN_CMD 0 "False" 1 "True";
VAL_ 32 MTPA_EN_CMD 0 "False" 1 "True";
VAL_ 96 BALANCE_EN 0 "False" 1 "True";
VAL_ 192 SYS_READY_ACTIVE 0 "False" 1 "True";
VAL_ 192 SYS_ENABLE_ACTIVE 0 "False" 1 "True";
VAL_ 192 SYS_ACTIVE 0 "False" 1 "True";
VAL_ 192 SYS_LIMIT_ACTIVE 0 "False" 1 "True";
VAL_ 192 FW_ACTIVE 0 "False" 1 "True";
VAL_ 192 RECV_CTRL_CMD_ACTIVE 0 "False" 1 "True";
VAL_ 192 ASC_ACTIVE 0 "False" 1 "True";
VAL_ 192 SYS_FAULT 0 "False" 1 "True";
VAL_ 192 VOLTAGE_SAT_ACTIVE 0 "False" 1 "True";
VAL_ 192 U_OCP_FAULT 0 "False" 1 "True";
VAL_ 192 V_OCP_FAULT 0 "False" 1 "True";
VAL_ 192 W_OCP_FAULT 0 "False" 1 "True";
VAL_ 192 U_GATE_FAULT 0 "False" 1 "True";
VAL_ 192 V_GATE_FAULT 0 "False" 1 "True";
VAL_ 192 W_GATE_FAULT 0 "False" 1 "True";
VAL_ 224 SYS_READY_ACTIVE 0 "False" 1 "True";
VAL_ 224 SYS_ENABLE_ACTIVE 0 "False" 1 "True";
VAL_ 224 SYS_ACTIVE 0 "False" 1 "True";
VAL_ 224 SYS_LIMIT_ACTIVE 0 "False" 1 "True";
VAL_ 224 FW_ACTIVE 0 "False" 1 "True";
VAL_ 224 RECV_CTRL_CMD_ACTIVE 0 "False" 1 "True";
VAL_ 224 ASC_ACTIVE 0 "False" 1 "True";
VAL_ 224 SYS_FAULT 0 "False" 1 "True";
VAL_ 224 VOLTAGE_SAT_ACTIVE 0 "False" 1 "True";
VAL_ 224 U_OCP_FAULT 0 "False" 1 "True";
VAL_ 224 V_OCP_FAULT 0 "False" 1 "True";
VAL_ 224 W_OCP_FAULT 0 "False" 1 "True";
VAL_ 224 U_GATE_FAULT 0 "False" 1 "True";
VAL_ 224 V_GATE_FAULT 0 "False" 1 "True";
VAL_ 224 W_GATE_FAULT 0 "False" 1 "True";
VAL_ 256 SYS_READY_ACTIVE 0 "False" 1 "True";
VAL_ 256 SYS_ENABLE_ACTIVE 0 "False" 1 "True";
VAL_ 256 SYS_ACTIVE 0 "False" 1 "True";
VAL_ 256 SYS_LIMIT_ACTIVE 0 "False" 1 "True";
VAL_ 256 FW_ACTIVE 0 "False" 1 "True";
VAL_ 256 RECV_CTRL_CMD_ACTIVE 0 "False" 1 "True";
VAL_ 256 ASC_ACTIVE 0 "False" 1 "True";
VAL_ 256 SYS_FAULT 0 "False" 1 "True";
VAL_ 256 VOLTAGE_SAT_ACTIVE 0 "False" 1 "True";
VAL_ 256 U_OCP_FAULT 0 "False" 1 "True";
VAL_ 256 V_OCP_FAULT 0 "False" 1 "True";
VAL_ 256 W_OCP_FAULT 0 "False" 1 "True";
VAL_ 256 U_GATE_FAULT 0 "False" 1 "True";
VAL_ 256 V_GATE_FAULT 0 "False" 1 "True";
VAL_ 256 W_GATE_FAULT 0 "False" 1 "True";
VAL_ 288 SYS_READY_ACTIVE 0 "False" 1 "True";
VAL_ 288 SYS_ENABLE_ACTIVE 0 "False" 1 "True";
VAL_ 288 SYS_ACTIVE 0 "False" 1 "True";
VAL_ 288 SYS_LIMIT_ACTIVE 0 "False" 1 "True";
VAL_ 288 FW_ACTIVE 0 "False" 1 "True";
VAL_ 288 RECV_CTRL_CMD_ACTIVE 0 "False" 1 "True";
VAL_ 288 ASC_ACTIVE 0 "False" 1 "True";
VAL_ 288 SYS_FAULT 0 "False" 1 "True";
VAL_ 288 VOLTAGE_SAT_ACTIVE 0 "False" 1 "True";
VAL_ 288 U_OCP_FAULT 0 "False" 1 "True";
VAL_ 288 V_OCP_FAULT 0 "False" 1 "True";
VAL_ 288 W_OCP_FAULT 0 "False" 1 "True";
VAL_ 288 U_GATE_FAULT 0 "False" 1 "True";
VAL_ 288 V_GATE_FAULT 0 "False" 1 "True";
VAL_ 288 W_GATE_FAULT 0 "False" 1 "True";
VAL_ 640 SYS_EN_CMD 0 "False" 1 "True";
VAL_ 640 SYS_RESET_CMD 0 "False" 1 "True";
VAL_ 640 FW_EN_CMD 0 "False" 1 "True";
VAL_ 641 SYS_EN_CMD 0 "False" 1 "True";
VAL_ 641 SYS_RESET_CMD 0 "False" 1 "True";
VAL_ 641 FW_EN_CMD 0 "False" 1 "True";
VAL_ 642 SYS_EN_CMD 0 "False" 1 "True";
VAL_ 642 SYS_RESET_CMD 0 "False" 1 "True";
VAL_ 642 FW_EN_CMD 0 "False" 1 "True";
VAL_ 643 SYS_EN_CMD 0 "False" 1 "True";
VAL_ 643 SYS_RESET_CMD 0 "False" 1 "True";
VAL_ 643 FW_EN_CMD 0 "False" 1 "True";
VAL_ 644 DIRECTION 0 "CW" 1 "CCW";
VAL_ 644 MODE 0 "TORQUE" 1 "SPEED" 2 "TEST";
VAL_ 645 DIRECTION 0 "CW" 1 "CCW";
VAL_ 645 MODE 0 "TORQUE" 1 "SPEED" 2 "TEST";
VAL_ 646 DIRECTION 0 "CW" 1 "CCW";
VAL_ 646 MODE 0 "TORQUE" 1 "SPEED" 2 "TEST";
VAL_ 647 DIRECTION 0 "CW" 1 "CCW";
VAL_ 647 MODE 0 "TORQUE" 1 "SPEED" 2 "TEST";
VAL_ 656 SAVE_CMD 0 "False" 1 "True";
VAL_ 657 SAVE_CMD 0 "False" 1 "True";
VAL_ 658 SAVE_CMD 0 "False" 1 "True";
VAL_ 659 SAVE_CMD 0 "False" 1 "True";
VAL_ 664 ENABLE_DEBUG 0 "False" 1 "True";
VAL_ 1056 RDY_TO_DRIVE_ACTIVE 0 "False" 1 "True";
VAL_ 1056 SDC_RDY 0 "False" 1 "True";
VAL_ 1056 MCU_RDY 0 "False" 1 "True";
VAL_ 1056 AMS_RDY 0 "False" 1 "True";
VAL_ 1056 IMU_RDY 0 "False" 1 "True";
VAL_ 1056 GPS_RDY 0 "False" 1 "True";
VAL_ 1056 SENSOR_RDY 0 "False" 1 "True";
VAL_ 1056 WARMUP_TMR_RDY 0 "False" 1 "True";
VAL_ 1056 TEBPPC_ACTIVE 0 "False" 1 "True";
VAL_ 1056 COOLING_SYSTEM_ACTIVE 0 "False" 1 "True";
VAL_ 1056 GLV_LOW_WARN 0 "False" 1 "True";
VAL_ 1056 SYS_DRIVE_MODE 0 "NO_CONTROL" 1 "EDIFF" 2 "RATIO" 3 "DYC";
VAL_ 1057 APPS1_ERR 0 "False" 1 "True";
VAL_ 1057 APPS2_ERR 0 "False" 1 "True";
VAL_ 1057 APPS_PLAUSIBILITY_ERR 0 "False" 1 "True";
VAL_ 1057 BSE_R_ERR 0 "False" 1 "True";
VAL_ 1057 BSE_F_ERR 0 "False" 1 "True";
VAL_ 1057 STEERING_ERR 0 "False" 1 "True";
VAL_ 1057 MCU1_ERR 0 "False" 1 "True";
VAL_ 1057 MCU2_ERR 0 "False" 1 "True";
VAL_ 1057 MCU3_ERR 0 "False" 1 "True";
VAL_ 1057 MCU4_ERR 0 "False" 1 "True";
VAL_ 1057 AMS_ERR 0 "False" 1 "True";
VAL_ 1057 MOTOR_DIRECTION_ERR 0 "False" 1 "True";
VAL_ 1057 IMU_ERR 0 "False" 1 "True";
VAL_ 1058 MCU1_ONLINE 0 "False" 1 "True";
VAL_ 1058 MCU2_ONLINE 0 "False" 1 "True";
VAL_ 1058 MCU3_ONLINE 0 "False" 1 "True";
VAL_ 1058 MCU4_ONLINE 0 "False" 1 "True";
VAL_ 1058 AMS_ONLINE 0 "False" 1 "True";
VAL_ 1058 IMU_ONLINE 0 "False" 1 "True";
VAL_ 1058 GPS_ONLINE 0 "False" 1 "True";
VAL_ 1059 IMD_STATUS 0 "False" 1 "True";
VAL_ 1059 AMS_STATUS 0 "False" 1 "True";
VAL_ 1059 BSPD_STATUS 0 "False" 1 "True";
VAL_ 1059 PDOC_STATUS 0 "False" 1 "True";
VAL_ 1059 CSB_STATUS 0 "False" 1 "True";
VAL_ 1059 LSB_STATUS 0 "False" 1 "True";
VAL_ 1059 RSB_STATUS 0 "False" 1 "True";
VAL_ 1059 INRT_STATUS 0 "False" 1 "True";
VAL_ 1059 BOTS_STATUS 0 "False" 1 "True";
VAL_ 1059 MCU_IL_STATUS 0 "False" 1 "True";
VAL_ 1059 M1_IL_STATUS 0 "False" 1 "True";
VAL_ 1059 M2_IL_STATUS 0 "False" 1 "True";
VAL_ 1059 M3_IL_STATUS 0 "False" 1 "True";
VAL_ 1059 M4_IL_STATUS 0 "False" 1 "True";
VAL_ 1059 TSMS_STATUS 0 "False" 1 "True";
VAL_ 1059 MSD_STATUS 0 "False" 1 "True";
VAL_ 1060 RTD_BUTTON_STATUS 0 "False" 1 "True";
VAL_ 1060 PRECHARGE_STATUS 0 "False" 1 "True";
VAL_ 1060 SC_MODE_STATUS 0 "False" 1 "True";
VAL_ 1060 USR_IN1_STATUS 0 "False" 1 "True";
VAL_ 1060 USR_IN2_STATUS 0 "False" 1 "True";
VAL_ 1060 USR_IN3_STATUS 0 "False" 1 "True";
VAL_ 1060 USR_IN4_STATUS 0 "False" 1 "True";
VAL_ 1060 USR_IN5_STATUS 0 "False" 1 "True";
VAL_ 1060 BRAKE_LIGHT_STATUS 0 "False" 1 "True";
VAL_ 1060 TSSI_GREEN_STATUS 0 "False" 1 "True";
VAL_ 1060 TSSI_RED_STATUS 0 "False" 1 "True";
VAL_ 1060 USR_OUT1_STATUS 0 "False" 1 "True";
VAL_ 1060 USR_OUT2_STATUS 0 "False" 1 "True";
VAL_ 1060 USR_OUT3_STATUS 0 "False" 1 "True";
VAL_ 1060 USR_OUT4_STATUS 0 "False" 1 "True";
VAL_ 1060 USR_OUT5_STATUS 0 "False" 1 "True";
VAL_ 1067 DYC_FAULT_VX 0 "False" 1 "True";
VAL_ 1067 DYC_FAULT_IMU 0 "False" 1 "True";
VAL_ 1067 DYC_FAULT_STEERING 0 "False" 1 "True";
VAL_ 1067 DYC_FAULT_YAW_RATE 0 "False" 1 "True";
VAL_ 1067 DYC_FAULT_AY 0 "False" 1 "True";
VAL_ 1067 DYC_FAULT_AY_YAWRATE 0 "False" 1 "True";
VAL_ 1067 DYC_IMU_SOURCE 0 "NONE" 1 "FRONT" 2 "VCU" 3 "AVERAGE";
VAL_ 1067 DYC_VX_VALID 0 "False" 1 "True";
VAL_ 1067 DYC_LOW_SPEED 0 "False" 1 "True";
VAL_ 1067 DYC_ALLOWED 0 "False" 1 "True";
VAL_ 1067 DYC_CONTROL_ACTIVE 0 "False" 1 "True";
VAL_ 1067 DYC_ALLOCATOR_SATURATED 0 "False" 1 "True";
VAL_ 1067 DYC_FORWARD_MOTION 0 "False" 1 "True";
VAL_ 1067 DYC_ZERO_THROTTLE 0 "False" 1 "True";
VAL_ 1067 DYC_NEGATIVE_TORQUE_ACTIVE 0 "False" 1 "True";
VAL_ 1071 INV1_GATE_FAULT 0 "False" 1 "True";
VAL_ 1071 INV1_ENC_FAULT 0 "False" 1 "True";
VAL_ 1071 INV1_OTP_FAULT 0 "False" 1 "True";
VAL_ 1071 INV1_OCP_FAULT 0 "False" 1 "True";
VAL_ 1071 INV2_GATE_FAULT 0 "False" 1 "True";
VAL_ 1071 INV2_ENC_FAULT 0 "False" 1 "True";
VAL_ 1071 INV2_OTP_FAULT 0 "False" 1 "True";
VAL_ 1071 INV2_OCP_FAULT 0 "False" 1 "True";
VAL_ 1071 INV3_GATE_FAULT 0 "False" 1 "True";
VAL_ 1071 INV3_ENC_FAULT 0 "False" 1 "True";
VAL_ 1071 INV3_OTP_FAULT 0 "False" 1 "True";
VAL_ 1071 INV3_OCP_FAULT 0 "False" 1 "True";
VAL_ 1071 INV4_GATE_FAULT 0 "False" 1 "True";
VAL_ 1071 INV4_ENC_FAULT 0 "False" 1 "True";
VAL_ 1071 INV4_OTP_FAULT 0 "False" 1 "True";
VAL_ 1071 INV4_OCP_FAULT 0 "False" 1 "True";
VAL_ 1074 MAIN_STATUS_INDICATOR 0 "RTD" 1 "READY" 2 "PRCHG" 3 "N-RDY" 4 "FAULT" 5 "RESET";
VAL_ 1082 GPS_MODULE_ACTIVE 0 "False" 1 "True";
VAL_ 1082 GPS_NO_SIGNAL_STATE 0 "False" 1 "True";
VAL_ 1084 RECV_MODE_CMD 0 "STANDALONE" 1 "BROADCAST";
VAL_ 1085 RECV_MODE_CMD 0 "STANDALONE" 1 "BROADCAST";
VAL_ 1086 RECV_MODE_CMD 0 "STANDALONE" 1 "BROADCAST";
VAL_ 1087 RECV_MODE_CMD 0 "STANDALONE" 1 "BROADCAST";
VAL_ 1088 AMS_STATE 0 "IDLE" 1 "MEASURE" 2 "BALANCING" 3 "CHARGING";
VAL_ 1088 BUS_OVER_CURRENT_ERR 0 "False" 1 "True";
VAL_ 1088 LTC_CONNECTION_LOSS 0 "False" 1 "True";
VAL_ 1088 CELL_OVER_VOLT_ERR 0 "False" 1 "True";
VAL_ 1088 CELL_UNDER_VOLT_ERR 0 "False" 1 "True";
VAL_ 1088 CELL_OVER_TEMP_ERR 0 "False" 1 "True";
VAL_ 1098 C0_BALANCE_STATE 0 "False" 1 "True";
VAL_ 1098 C1_BALANCE_STATE 0 "False" 1 "True";
VAL_ 1098 C2_BALANCE_STATE 0 "False" 1 "True";
VAL_ 1098 C3_BALANCE_STATE 0 "False" 1 "True";
VAL_ 1098 C4_BALANCE_STATE 0 "False" 1 "True";
VAL_ 1098 C5_BALANCE_STATE 0 "False" 1 "True";
VAL_ 1098 C6_BALANCE_STATE 0 "False" 1 "True";
VAL_ 1098 C7_BALANCE_STATE 0 "False" 1 "True";
VAL_ 1098 C8_BALANCE_STATE 0 "False" 1 "True";
VAL_ 1098 C9_BALANCE_STATE 0 "False" 1 "True";
VAL_ 1098 C10_BALANCE_STATE 0 "False" 1 "True";
VAL_ 1098 C11_BALANCE_STATE 0 "False" 1 "True";
VAL_ 1098 C12_BALANCE_STATE 0 "False" 1 "True";
VAL_ 1098 C13_BALANCE_STATE 0 "False" 1 "True";
VAL_ 1099 C0_BALANCE_STATE 0 "False" 1 "True";
VAL_ 1099 C1_BALANCE_STATE 0 "False" 1 "True";
VAL_ 1099 C2_BALANCE_STATE 0 "False" 1 "True";
VAL_ 1099 C3_BALANCE_STATE 0 "False" 1 "True";
VAL_ 1099 C4_BALANCE_STATE 0 "False" 1 "True";
VAL_ 1099 C5_BALANCE_STATE 0 "False" 1 "True";
VAL_ 1099 C6_BALANCE_STATE 0 "False" 1 "True";
VAL_ 1099 C7_BALANCE_STATE 0 "False" 1 "True";
VAL_ 1099 C8_BALANCE_STATE 0 "False" 1 "True";
VAL_ 1099 C9_BALANCE_STATE 0 "False" 1 "True";
VAL_ 1099 C10_BALANCE_STATE 0 "False" 1 "True";
VAL_ 1099 C11_BALANCE_STATE 0 "False" 1 "True";
VAL_ 1099 C12_BALANCE_STATE 0 "False" 1 "True";
VAL_ 1099 C13_BALANCE_STATE 0 "False" 1 "True";
VAL_ 1100 C0_BALANCE_STATE 0 "False" 1 "True";
VAL_ 1100 C1_BALANCE_STATE 0 "False" 1 "True";
VAL_ 1100 C2_BALANCE_STATE 0 "False" 1 "True";
VAL_ 1100 C3_BALANCE_STATE 0 "False" 1 "True";
VAL_ 1100 C4_BALANCE_STATE 0 "False" 1 "True";
VAL_ 1100 C5_BALANCE_STATE 0 "False" 1 "True";
VAL_ 1100 C6_BALANCE_STATE 0 "False" 1 "True";
VAL_ 1100 C7_BALANCE_STATE 0 "False" 1 "True";
VAL_ 1100 C8_BALANCE_STATE 0 "False" 1 "True";
VAL_ 1100 C9_BALANCE_STATE 0 "False" 1 "True";
VAL_ 1100 C10_BALANCE_STATE 0 "False" 1 "True";
VAL_ 1100 C11_BALANCE_STATE 0 "False" 1 "True";
VAL_ 1100 C12_BALANCE_STATE 0 "False" 1 "True";
VAL_ 1100 C13_BALANCE_STATE 0 "False" 1 "True";
VAL_ 1101 C0_BALANCE_STATE 0 "False" 1 "True";
VAL_ 1101 C1_BALANCE_STATE 0 "False" 1 "True";
VAL_ 1101 C2_BALANCE_STATE 0 "False" 1 "True";
VAL_ 1101 C3_BALANCE_STATE 0 "False" 1 "True";
VAL_ 1101 C4_BALANCE_STATE 0 "False" 1 "True";
VAL_ 1101 C5_BALANCE_STATE 0 "False" 1 "True";
VAL_ 1101 C6_BALANCE_STATE 0 "False" 1 "True";
VAL_ 1101 C7_BALANCE_STATE 0 "False" 1 "True";
VAL_ 1101 C8_BALANCE_STATE 0 "False" 1 "True";
VAL_ 1101 C9_BALANCE_STATE 0 "False" 1 "True";
VAL_ 1101 C10_BALANCE_STATE 0 "False" 1 "True";
VAL_ 1101 C11_BALANCE_STATE 0 "False" 1 "True";
VAL_ 1101 C12_BALANCE_STATE 0 "False" 1 "True";
VAL_ 1101 C13_BALANCE_STATE 0 "False" 1 "True";
VAL_ 1102 C0_BALANCE_STATE 0 "False" 1 "True";
VAL_ 1102 C1_BALANCE_STATE 0 "False" 1 "True";
VAL_ 1102 C2_BALANCE_STATE 0 "False" 1 "True";
VAL_ 1102 C3_BALANCE_STATE 0 "False" 1 "True";
VAL_ 1102 C4_BALANCE_STATE 0 "False" 1 "True";
VAL_ 1102 C5_BALANCE_STATE 0 "False" 1 "True";
VAL_ 1102 C6_BALANCE_STATE 0 "False" 1 "True";
VAL_ 1102 C7_BALANCE_STATE 0 "False" 1 "True";
VAL_ 1102 C8_BALANCE_STATE 0 "False" 1 "True";
VAL_ 1102 C9_BALANCE_STATE 0 "False" 1 "True";
VAL_ 1102 C10_BALANCE_STATE 0 "False" 1 "True";
VAL_ 1102 C11_BALANCE_STATE 0 "False" 1 "True";
VAL_ 1102 C12_BALANCE_STATE 0 "False" 1 "True";
VAL_ 1102 C13_BALANCE_STATE 0 "False" 1 "True";
VAL_ 1103 C0_BALANCE_STATE 0 "False" 1 "True";
VAL_ 1103 C1_BALANCE_STATE 0 "False" 1 "True";
VAL_ 1103 C2_BALANCE_STATE 0 "False" 1 "True";
VAL_ 1103 C3_BALANCE_STATE 0 "False" 1 "True";
VAL_ 1103 C4_BALANCE_STATE 0 "False" 1 "True";
VAL_ 1103 C5_BALANCE_STATE 0 "False" 1 "True";
VAL_ 1103 C6_BALANCE_STATE 0 "False" 1 "True";
VAL_ 1103 C7_BALANCE_STATE 0 "False" 1 "True";
VAL_ 1103 C8_BALANCE_STATE 0 "False" 1 "True";
VAL_ 1103 C9_BALANCE_STATE 0 "False" 1 "True";
VAL_ 1103 C10_BALANCE_STATE 0 "False" 1 "True";
VAL_ 1103 C11_BALANCE_STATE 0 "False" 1 "True";
VAL_ 1103 C12_BALANCE_STATE 0 "False" 1 "True";
VAL_ 1103 C13_BALANCE_STATE 0 "False" 1 "True";
VAL_ 1104 C0_BALANCE_STATE 0 "False" 1 "True";
VAL_ 1104 C1_BALANCE_STATE 0 "False" 1 "True";
VAL_ 1104 C2_BALANCE_STATE 0 "False" 1 "True";
VAL_ 1104 C3_BALANCE_STATE 0 "False" 1 "True";
VAL_ 1104 C4_BALANCE_STATE 0 "False" 1 "True";
VAL_ 1104 C5_BALANCE_STATE 0 "False" 1 "True";
VAL_ 1104 C6_BALANCE_STATE 0 "False" 1 "True";
VAL_ 1104 C7_BALANCE_STATE 0 "False" 1 "True";
VAL_ 1104 C8_BALANCE_STATE 0 "False" 1 "True";
VAL_ 1104 C9_BALANCE_STATE 0 "False" 1 "True";
VAL_ 1104 C10_BALANCE_STATE 0 "False" 1 "True";
VAL_ 1104 C11_BALANCE_STATE 0 "False" 1 "True";
VAL_ 1104 C12_BALANCE_STATE 0 "False" 1 "True";
VAL_ 1104 C13_BALANCE_STATE 0 "False" 1 "True";
VAL_ 1105 C0_BALANCE_STATE 0 "False" 1 "True";
VAL_ 1105 C1_BALANCE_STATE 0 "False" 1 "True";
VAL_ 1105 C2_BALANCE_STATE 0 "False" 1 "True";
VAL_ 1105 C3_BALANCE_STATE 0 "False" 1 "True";
VAL_ 1105 C4_BALANCE_STATE 0 "False" 1 "True";
VAL_ 1105 C5_BALANCE_STATE 0 "False" 1 "True";
VAL_ 1105 C6_BALANCE_STATE 0 "False" 1 "True";
VAL_ 1105 C7_BALANCE_STATE 0 "False" 1 "True";
VAL_ 1105 C8_BALANCE_STATE 0 "False" 1 "True";
VAL_ 1105 C9_BALANCE_STATE 0 "False" 1 "True";
VAL_ 1105 C10_BALANCE_STATE 0 "False" 1 "True";
VAL_ 1105 C11_BALANCE_STATE 0 "False" 1 "True";
VAL_ 1105 C12_BALANCE_STATE 0 "False" 1 "True";
VAL_ 1105 C13_BALANCE_STATE 0 "False" 1 "True";
VAL_ 1217 ENCODER_FAULT 0 "False" 1 "True";
VAL_ 1217 OVP_FAULT 0 "False" 1 "True";
VAL_ 1217 UVP_FAULT 0 "False" 1 "True";
VAL_ 1217 RECV_CTRL_LOSS_FAULT 0 "False" 1 "True";
VAL_ 1217 U_GATE_OTP_FAULT 0 "False" 1 "True";
VAL_ 1217 V_GATE_OTP_FAULT 0 "False" 1 "True";
VAL_ 1217 MOTOR_OTP_FAULT 0 "False" 1 "True";
VAL_ 1217 W_GATE_OTP_FAULT 0 "False" 1 "True";
VAL_ 1217 DIRECTION_STATE 0 "CW" 1 "CCW";
VAL_ 1217 RECV_MODE_BROADCAST_STATE 0 "False" 1 "True";
VAL_ 1217 RECV_MODE_STANDALONE_STATE 0 "False" 1 "True";
VAL_ 1217 FW_EN_ECHO 0 "False" 1 "True";
VAL_ 1217 RUN_MODE_STATE 0 "Torque" 1 "Speed" 2 "Test";
VAL_ 1219 FLASH_LAST_ERROR_STATE 0 "OK" 1 "VERSION" 2 "CRC" 3 "RANGE" 4 "ERASE" 5 "PROGRAM" 6 "VERIFY" 7 "APPLY_BLOCKED" 8 "UNKNOWN";
VAL_ 1219 RESET_CAUSE 0 "POR" 1 "WDRS" 2 "XRS";
VAL_ 1219 SOFT_STOP_REASON 0 "SOFT_STOP_NONE" 1 "ENABLE_LOST" 2 "CAN_LOSS";
VAL_ 1220 H_NLSE 0 "False" 1 "True";
VAL_ 1220 H_OVLO2 0 "False" 1 "True";
VAL_ 1220 H_UVLO2 0 "False" 1 "True";
VAL_ 1220 H_OVLO3 0 "False" 1 "True";
VAL_ 1220 H_UVLO3 0 "False" 1 "True";
VAL_ 1220 H_BDW 0 "False" 1 "True";
VAL_ 1220 H_SASC 0 "False" 1 "True";
VAL_ 1220 H_DTW 0 "False" 1 "True";
VAL_ 1220 H_STPKW 0 "False" 1 "True";
VAL_ 1220 H_OSME 0 "False" 1 "True";
VAL_ 1220 H_GME 0 "False" 1 "True";
VAL_ 1220 H_DDE 0 "False" 1 "True";
VAL_ 1220 H_NDBISTW 0 "False" 1 "True";
VAL_ 1220 H_SASCAW 0 "False" 1 "True";
VAL_ 1220 L_NLSE 0 "False" 1 "True";
VAL_ 1220 L_OVLO2 0 "False" 1 "True";
VAL_ 1220 L_UVLO2 0 "False" 1 "True";
VAL_ 1220 L_OVLO3 0 "False" 1 "True";
VAL_ 1220 L_UVLO3 0 "False" 1 "True";
VAL_ 1220 L_BDW 0 "False" 1 "True";
VAL_ 1220 L_SASC 0 "False" 1 "True";
VAL_ 1220 L_DTW 0 "False" 1 "True";
VAL_ 1220 L_STPKW 0 "False" 1 "True";
VAL_ 1220 L_OSME 0 "False" 1 "True";
VAL_ 1220 L_GME 0 "False" 1 "True";
VAL_ 1220 L_DDE 0 "False" 1 "True";
VAL_ 1220 L_NDBISTW 0 "False" 1 "True";
VAL_ 1220 L_SASCAW 0 "False" 1 "True";
VAL_ 1221 H_NLSE 0 "False" 1 "True";
VAL_ 1221 H_OVLO2 0 "False" 1 "True";
VAL_ 1221 H_UVLO2 0 "False" 1 "True";
VAL_ 1221 H_OVLO3 0 "False" 1 "True";
VAL_ 1221 H_UVLO3 0 "False" 1 "True";
VAL_ 1221 H_BDW 0 "False" 1 "True";
VAL_ 1221 H_SASC 0 "False" 1 "True";
VAL_ 1221 H_DTW 0 "False" 1 "True";
VAL_ 1221 H_STPKW 0 "False" 1 "True";
VAL_ 1221 H_OSME 0 "False" 1 "True";
VAL_ 1221 H_GME 0 "False" 1 "True";
VAL_ 1221 H_DDE 0 "False" 1 "True";
VAL_ 1221 H_NDBISTW 0 "False" 1 "True";
VAL_ 1221 H_SASCAW 0 "False" 1 "True";
VAL_ 1221 L_NLSE 0 "False" 1 "True";
VAL_ 1221 L_OVLO2 0 "False" 1 "True";
VAL_ 1221 L_UVLO2 0 "False" 1 "True";
VAL_ 1221 L_OVLO3 0 "False" 1 "True";
VAL_ 1221 L_UVLO3 0 "False" 1 "True";
VAL_ 1221 L_BDW 0 "False" 1 "True";
VAL_ 1221 L_SASC 0 "False" 1 "True";
VAL_ 1221 L_DTW 0 "False" 1 "True";
VAL_ 1221 L_STPKW 0 "False" 1 "True";
VAL_ 1221 L_OSME 0 "False" 1 "True";
VAL_ 1221 L_GME 0 "False" 1 "True";
VAL_ 1221 L_DDE 0 "False" 1 "True";
VAL_ 1221 L_NDBISTW 0 "False" 1 "True";
VAL_ 1221 L_SASCAW 0 "False" 1 "True";
VAL_ 1222 H_NLSE 0 "False" 1 "True";
VAL_ 1222 H_OVLO2 0 "False" 1 "True";
VAL_ 1222 H_UVLO2 0 "False" 1 "True";
VAL_ 1222 H_OVLO3 0 "False" 1 "True";
VAL_ 1222 H_UVLO3 0 "False" 1 "True";
VAL_ 1222 H_BDW 0 "False" 1 "True";
VAL_ 1222 H_SASC 0 "False" 1 "True";
VAL_ 1222 H_DTW 0 "False" 1 "True";
VAL_ 1222 H_STPKW 0 "False" 1 "True";
VAL_ 1222 H_OSME 0 "False" 1 "True";
VAL_ 1222 H_GME 0 "False" 1 "True";
VAL_ 1222 H_DDE 0 "False" 1 "True";
VAL_ 1222 H_NDBISTW 0 "False" 1 "True";
VAL_ 1222 H_SASCAW 0 "False" 1 "True";
VAL_ 1222 L_NLSE 0 "False" 1 "True";
VAL_ 1222 L_OVLO2 0 "False" 1 "True";
VAL_ 1222 L_UVLO2 0 "False" 1 "True";
VAL_ 1222 L_OVLO3 0 "False" 1 "True";
VAL_ 1222 L_UVLO3 0 "False" 1 "True";
VAL_ 1222 L_BDW 0 "False" 1 "True";
VAL_ 1222 L_SASC 0 "False" 1 "True";
VAL_ 1222 L_DTW 0 "False" 1 "True";
VAL_ 1222 L_STPKW 0 "False" 1 "True";
VAL_ 1222 L_OSME 0 "False" 1 "True";
VAL_ 1222 L_GME 0 "False" 1 "True";
VAL_ 1222 L_DDE 0 "False" 1 "True";
VAL_ 1222 L_NDBISTW 0 "False" 1 "True";
VAL_ 1222 L_SASCAW 0 "False" 1 "True";
VAL_ 1237 DIRECTION 0 "CW" 1 "CCW";
VAL_ 1237 MODE 0 "TORQUE" 1 "SPEED" 2 "TEST";
VAL_ 1249 ENCODER_FAULT 0 "False" 1 "True";
VAL_ 1249 OVP_FAULT 0 "False" 1 "True";
VAL_ 1249 UVP_FAULT 0 "False" 1 "True";
VAL_ 1249 RECV_CTRL_LOSS_FAULT 0 "False" 1 "True";
VAL_ 1249 U_GATE_OTP_FAULT 0 "False" 1 "True";
VAL_ 1249 V_GATE_OTP_FAULT 0 "False" 1 "True";
VAL_ 1249 MOTOR_OTP_FAULT 0 "False" 1 "True";
VAL_ 1249 W_GATE_OTP_FAULT 0 "False" 1 "True";
VAL_ 1249 DIRECTION_STATE 0 "CW" 1 "CCW";
VAL_ 1249 RECV_MODE_BROADCAST_STATE 0 "False" 1 "True";
VAL_ 1249 RECV_MODE_STANDALONE_STATE 0 "False" 1 "True";
VAL_ 1249 FW_EN_ECHO 0 "False" 1 "True";
VAL_ 1249 RUN_MODE_STATE 0 "Torque" 1 "Speed" 2 "Test";
VAL_ 1251 FLASH_LAST_ERROR_STATE 0 "OK" 1 "VERSION" 2 "CRC" 3 "RANGE" 4 "ERASE" 5 "PROGRAM" 6 "VERIFY" 7 "APPLY_BLOCKED" 8 "UNKNOWN";
VAL_ 1251 RESET_CAUSE 0 "POR" 1 "WDRS" 2 "XRS";
VAL_ 1251 SOFT_STOP_REASON 0 "SOFT_STOP_NONE" 1 "ENABLE_LOST" 2 "CAN_LOSS";
VAL_ 1252 H_NLSE 0 "False" 1 "True";
VAL_ 1252 H_OVLO2 0 "False" 1 "True";
VAL_ 1252 H_UVLO2 0 "False" 1 "True";
VAL_ 1252 H_OVLO3 0 "False" 1 "True";
VAL_ 1252 H_UVLO3 0 "False" 1 "True";
VAL_ 1252 H_BDW 0 "False" 1 "True";
VAL_ 1252 H_SASC 0 "False" 1 "True";
VAL_ 1252 H_DTW 0 "False" 1 "True";
VAL_ 1252 H_STPKW 0 "False" 1 "True";
VAL_ 1252 H_OSME 0 "False" 1 "True";
VAL_ 1252 H_GME 0 "False" 1 "True";
VAL_ 1252 H_DDE 0 "False" 1 "True";
VAL_ 1252 H_NDBISTW 0 "False" 1 "True";
VAL_ 1252 H_SASCAW 0 "False" 1 "True";
VAL_ 1252 L_NLSE 0 "False" 1 "True";
VAL_ 1252 L_OVLO2 0 "False" 1 "True";
VAL_ 1252 L_UVLO2 0 "False" 1 "True";
VAL_ 1252 L_OVLO3 0 "False" 1 "True";
VAL_ 1252 L_UVLO3 0 "False" 1 "True";
VAL_ 1252 L_BDW 0 "False" 1 "True";
VAL_ 1252 L_SASC 0 "False" 1 "True";
VAL_ 1252 L_DTW 0 "False" 1 "True";
VAL_ 1252 L_STPKW 0 "False" 1 "True";
VAL_ 1252 L_OSME 0 "False" 1 "True";
VAL_ 1252 L_GME 0 "False" 1 "True";
VAL_ 1252 L_DDE 0 "False" 1 "True";
VAL_ 1252 L_NDBISTW 0 "False" 1 "True";
VAL_ 1252 L_SASCAW 0 "False" 1 "True";
VAL_ 1253 H_NLSE 0 "False" 1 "True";
VAL_ 1253 H_OVLO2 0 "False" 1 "True";
VAL_ 1253 H_UVLO2 0 "False" 1 "True";
VAL_ 1253 H_OVLO3 0 "False" 1 "True";
VAL_ 1253 H_UVLO3 0 "False" 1 "True";
VAL_ 1253 H_BDW 0 "False" 1 "True";
VAL_ 1253 H_SASC 0 "False" 1 "True";
VAL_ 1253 H_DTW 0 "False" 1 "True";
VAL_ 1253 H_STPKW 0 "False" 1 "True";
VAL_ 1253 H_OSME 0 "False" 1 "True";
VAL_ 1253 H_GME 0 "False" 1 "True";
VAL_ 1253 H_DDE 0 "False" 1 "True";
VAL_ 1253 H_NDBISTW 0 "False" 1 "True";
VAL_ 1253 H_SASCAW 0 "False" 1 "True";
VAL_ 1253 L_NLSE 0 "False" 1 "True";
VAL_ 1253 L_OVLO2 0 "False" 1 "True";
VAL_ 1253 L_UVLO2 0 "False" 1 "True";
VAL_ 1253 L_OVLO3 0 "False" 1 "True";
VAL_ 1253 L_UVLO3 0 "False" 1 "True";
VAL_ 1253 L_BDW 0 "False" 1 "True";
VAL_ 1253 L_SASC 0 "False" 1 "True";
VAL_ 1253 L_DTW 0 "False" 1 "True";
VAL_ 1253 L_STPKW 0 "False" 1 "True";
VAL_ 1253 L_OSME 0 "False" 1 "True";
VAL_ 1253 L_GME 0 "False" 1 "True";
VAL_ 1253 L_DDE 0 "False" 1 "True";
VAL_ 1253 L_NDBISTW 0 "False" 1 "True";
VAL_ 1253 L_SASCAW 0 "False" 1 "True";
VAL_ 1254 H_NLSE 0 "False" 1 "True";
VAL_ 1254 H_OVLO2 0 "False" 1 "True";
VAL_ 1254 H_UVLO2 0 "False" 1 "True";
VAL_ 1254 H_OVLO3 0 "False" 1 "True";
VAL_ 1254 H_UVLO3 0 "False" 1 "True";
VAL_ 1254 H_BDW 0 "False" 1 "True";
VAL_ 1254 H_SASC 0 "False" 1 "True";
VAL_ 1254 H_DTW 0 "False" 1 "True";
VAL_ 1254 H_STPKW 0 "False" 1 "True";
VAL_ 1254 H_OSME 0 "False" 1 "True";
VAL_ 1254 H_GME 0 "False" 1 "True";
VAL_ 1254 H_DDE 0 "False" 1 "True";
VAL_ 1254 H_NDBISTW 0 "False" 1 "True";
VAL_ 1254 H_SASCAW 0 "False" 1 "True";
VAL_ 1254 L_NLSE 0 "False" 1 "True";
VAL_ 1254 L_OVLO2 0 "False" 1 "True";
VAL_ 1254 L_UVLO2 0 "False" 1 "True";
VAL_ 1254 L_OVLO3 0 "False" 1 "True";
VAL_ 1254 L_UVLO3 0 "False" 1 "True";
VAL_ 1254 L_BDW 0 "False" 1 "True";
VAL_ 1254 L_SASC 0 "False" 1 "True";
VAL_ 1254 L_DTW 0 "False" 1 "True";
VAL_ 1254 L_STPKW 0 "False" 1 "True";
VAL_ 1254 L_OSME 0 "False" 1 "True";
VAL_ 1254 L_GME 0 "False" 1 "True";
VAL_ 1254 L_DDE 0 "False" 1 "True";
VAL_ 1254 L_NDBISTW 0 "False" 1 "True";
VAL_ 1254 L_SASCAW 0 "False" 1 "True";
VAL_ 1269 DIRECTION 0 "CW" 1 "CCW";
VAL_ 1269 MODE 0 "TORQUE" 1 "SPEED" 2 "TEST";
VAL_ 1281 ENCODER_FAULT 0 "False" 1 "True";
VAL_ 1281 OVP_FAULT 0 "False" 1 "True";
VAL_ 1281 UVP_FAULT 0 "False" 1 "True";
VAL_ 1281 RECV_CTRL_LOSS_FAULT 0 "False" 1 "True";
VAL_ 1281 U_GATE_OTP_FAULT 0 "False" 1 "True";
VAL_ 1281 V_GATE_OTP_FAULT 0 "False" 1 "True";
VAL_ 1281 MOTOR_OTP_FAULT 0 "False" 1 "True";
VAL_ 1281 W_GATE_OTP_FAULT 0 "False" 1 "True";
VAL_ 1281 DIRECTION_STATE 0 "CW" 1 "CCW";
VAL_ 1281 RECV_MODE_BROADCAST_STATE 0 "False" 1 "True";
VAL_ 1281 RECV_MODE_STANDALONE_STATE 0 "False" 1 "True";
VAL_ 1281 FW_EN_ECHO 0 "False" 1 "True";
VAL_ 1281 RUN_MODE_STATE 0 "Torque" 1 "Speed" 2 "Test";
VAL_ 1283 FLASH_LAST_ERROR_STATE 0 "OK" 1 "VERSION" 2 "CRC" 3 "RANGE" 4 "ERASE" 5 "PROGRAM" 6 "VERIFY" 7 "APPLY_BLOCKED" 8 "UNKNOWN";
VAL_ 1283 RESET_CAUSE 0 "POR" 1 "WDRS" 2 "XRS";
VAL_ 1283 SOFT_STOP_REASON 0 "SOFT_STOP_NONE" 1 "ENABLE_LOST" 2 "CAN_LOSS";
VAL_ 1284 H_NLSE 0 "False" 1 "True";
VAL_ 1284 H_OVLO2 0 "False" 1 "True";
VAL_ 1284 H_UVLO2 0 "False" 1 "True";
VAL_ 1284 H_OVLO3 0 "False" 1 "True";
VAL_ 1284 H_UVLO3 0 "False" 1 "True";
VAL_ 1284 H_BDW 0 "False" 1 "True";
VAL_ 1284 H_SASC 0 "False" 1 "True";
VAL_ 1284 H_DTW 0 "False" 1 "True";
VAL_ 1284 H_STPKW 0 "False" 1 "True";
VAL_ 1284 H_OSME 0 "False" 1 "True";
VAL_ 1284 H_GME 0 "False" 1 "True";
VAL_ 1284 H_DDE 0 "False" 1 "True";
VAL_ 1284 H_NDBISTW 0 "False" 1 "True";
VAL_ 1284 H_SASCAW 0 "False" 1 "True";
VAL_ 1284 L_NLSE 0 "False" 1 "True";
VAL_ 1284 L_OVLO2 0 "False" 1 "True";
VAL_ 1284 L_UVLO2 0 "False" 1 "True";
VAL_ 1284 L_OVLO3 0 "False" 1 "True";
VAL_ 1284 L_UVLO3 0 "False" 1 "True";
VAL_ 1284 L_BDW 0 "False" 1 "True";
VAL_ 1284 L_SASC 0 "False" 1 "True";
VAL_ 1284 L_DTW 0 "False" 1 "True";
VAL_ 1284 L_STPKW 0 "False" 1 "True";
VAL_ 1284 L_OSME 0 "False" 1 "True";
VAL_ 1284 L_GME 0 "False" 1 "True";
VAL_ 1284 L_DDE 0 "False" 1 "True";
VAL_ 1284 L_NDBISTW 0 "False" 1 "True";
VAL_ 1284 L_SASCAW 0 "False" 1 "True";
VAL_ 1285 H_NLSE 0 "False" 1 "True";
VAL_ 1285 H_OVLO2 0 "False" 1 "True";
VAL_ 1285 H_UVLO2 0 "False" 1 "True";
VAL_ 1285 H_OVLO3 0 "False" 1 "True";
VAL_ 1285 H_UVLO3 0 "False" 1 "True";
VAL_ 1285 H_BDW 0 "False" 1 "True";
VAL_ 1285 H_SASC 0 "False" 1 "True";
VAL_ 1285 H_DTW 0 "False" 1 "True";
VAL_ 1285 H_STPKW 0 "False" 1 "True";
VAL_ 1285 H_OSME 0 "False" 1 "True";
VAL_ 1285 H_GME 0 "False" 1 "True";
VAL_ 1285 H_DDE 0 "False" 1 "True";
VAL_ 1285 H_NDBISTW 0 "False" 1 "True";
VAL_ 1285 H_SASCAW 0 "False" 1 "True";
VAL_ 1285 L_NLSE 0 "False" 1 "True";
VAL_ 1285 L_OVLO2 0 "False" 1 "True";
VAL_ 1285 L_UVLO2 0 "False" 1 "True";
VAL_ 1285 L_OVLO3 0 "False" 1 "True";
VAL_ 1285 L_UVLO3 0 "False" 1 "True";
VAL_ 1285 L_BDW 0 "False" 1 "True";
VAL_ 1285 L_SASC 0 "False" 1 "True";
VAL_ 1285 L_DTW 0 "False" 1 "True";
VAL_ 1285 L_STPKW 0 "False" 1 "True";
VAL_ 1285 L_OSME 0 "False" 1 "True";
VAL_ 1285 L_GME 0 "False" 1 "True";
VAL_ 1285 L_DDE 0 "False" 1 "True";
VAL_ 1285 L_NDBISTW 0 "False" 1 "True";
VAL_ 1285 L_SASCAW 0 "False" 1 "True";
VAL_ 1286 H_NLSE 0 "False" 1 "True";
VAL_ 1286 H_OVLO2 0 "False" 1 "True";
VAL_ 1286 H_UVLO2 0 "False" 1 "True";
VAL_ 1286 H_OVLO3 0 "False" 1 "True";
VAL_ 1286 H_UVLO3 0 "False" 1 "True";
VAL_ 1286 H_BDW 0 "False" 1 "True";
VAL_ 1286 H_SASC 0 "False" 1 "True";
VAL_ 1286 H_DTW 0 "False" 1 "True";
VAL_ 1286 H_STPKW 0 "False" 1 "True";
VAL_ 1286 H_OSME 0 "False" 1 "True";
VAL_ 1286 H_GME 0 "False" 1 "True";
VAL_ 1286 H_DDE 0 "False" 1 "True";
VAL_ 1286 H_NDBISTW 0 "False" 1 "True";
VAL_ 1286 H_SASCAW 0 "False" 1 "True";
VAL_ 1286 L_NLSE 0 "False" 1 "True";
VAL_ 1286 L_OVLO2 0 "False" 1 "True";
VAL_ 1286 L_UVLO2 0 "False" 1 "True";
VAL_ 1286 L_OVLO3 0 "False" 1 "True";
VAL_ 1286 L_UVLO3 0 "False" 1 "True";
VAL_ 1286 L_BDW 0 "False" 1 "True";
VAL_ 1286 L_SASC 0 "False" 1 "True";
VAL_ 1286 L_DTW 0 "False" 1 "True";
VAL_ 1286 L_STPKW 0 "False" 1 "True";
VAL_ 1286 L_OSME 0 "False" 1 "True";
VAL_ 1286 L_GME 0 "False" 1 "True";
VAL_ 1286 L_DDE 0 "False" 1 "True";
VAL_ 1286 L_NDBISTW 0 "False" 1 "True";
VAL_ 1286 L_SASCAW 0 "False" 1 "True";
VAL_ 1301 DIRECTION 0 "CW" 1 "CCW";
VAL_ 1301 MODE 0 "TORQUE" 1 "SPEED" 2 "TEST";
VAL_ 1313 ENCODER_FAULT 0 "False" 1 "True";
VAL_ 1313 OVP_FAULT 0 "False" 1 "True";
VAL_ 1313 UVP_FAULT 0 "False" 1 "True";
VAL_ 1313 RECV_CTRL_LOSS_FAULT 0 "False" 1 "True";
VAL_ 1313 U_GATE_OTP_FAULT 0 "False" 1 "True";
VAL_ 1313 V_GATE_OTP_FAULT 0 "False" 1 "True";
VAL_ 1313 MOTOR_OTP_FAULT 0 "False" 1 "True";
VAL_ 1313 W_GATE_OTP_FAULT 0 "False" 1 "True";
VAL_ 1313 DIRECTION_STATE 0 "CW" 1 "CCW";
VAL_ 1313 RECV_MODE_BROADCAST_STATE 0 "False" 1 "True";
VAL_ 1313 RECV_MODE_STANDALONE_STATE 0 "False" 1 "True";
VAL_ 1313 FW_EN_ECHO 0 "False" 1 "True";
VAL_ 1313 RUN_MODE_STATE 0 "Torque" 1 "Speed" 2 "Test";
VAL_ 1315 FLASH_LAST_ERROR_STATE 0 "OK" 1 "VERSION" 2 "CRC" 3 "RANGE" 4 "ERASE" 5 "PROGRAM" 6 "VERIFY" 7 "APPLY_BLOCKED" 8 "UNKNOWN";
VAL_ 1315 RESET_CAUSE 0 "POR" 1 "WDRS" 2 "XRS";
VAL_ 1315 SOFT_STOP_REASON 0 "SOFT_STOP_NONE" 1 "ENABLE_LOST" 2 "CAN_LOSS";
VAL_ 1316 H_NLSE 0 "False" 1 "True";
VAL_ 1316 H_OVLO2 0 "False" 1 "True";
VAL_ 1316 H_UVLO2 0 "False" 1 "True";
VAL_ 1316 H_OVLO3 0 "False" 1 "True";
VAL_ 1316 H_UVLO3 0 "False" 1 "True";
VAL_ 1316 H_BDW 0 "False" 1 "True";
VAL_ 1316 H_SASC 0 "False" 1 "True";
VAL_ 1316 H_DTW 0 "False" 1 "True";
VAL_ 1316 H_STPKW 0 "False" 1 "True";
VAL_ 1316 H_OSME 0 "False" 1 "True";
VAL_ 1316 H_GME 0 "False" 1 "True";
VAL_ 1316 H_DDE 0 "False" 1 "True";
VAL_ 1316 H_NDBISTW 0 "False" 1 "True";
VAL_ 1316 H_SASCAW 0 "False" 1 "True";
VAL_ 1316 L_NLSE 0 "False" 1 "True";
VAL_ 1316 L_OVLO2 0 "False" 1 "True";
VAL_ 1316 L_UVLO2 0 "False" 1 "True";
VAL_ 1316 L_OVLO3 0 "False" 1 "True";
VAL_ 1316 L_UVLO3 0 "False" 1 "True";
VAL_ 1316 L_BDW 0 "False" 1 "True";
VAL_ 1316 L_SASC 0 "False" 1 "True";
VAL_ 1316 L_DTW 0 "False" 1 "True";
VAL_ 1316 L_STPKW 0 "False" 1 "True";
VAL_ 1316 L_OSME 0 "False" 1 "True";
VAL_ 1316 L_GME 0 "False" 1 "True";
VAL_ 1316 L_DDE 0 "False" 1 "True";
VAL_ 1316 L_NDBISTW 0 "False" 1 "True";
VAL_ 1316 L_SASCAW 0 "False" 1 "True";
VAL_ 1317 H_NLSE 0 "False" 1 "True";
VAL_ 1317 H_OVLO2 0 "False" 1 "True";
VAL_ 1317 H_UVLO2 0 "False" 1 "True";
VAL_ 1317 H_OVLO3 0 "False" 1 "True";
VAL_ 1317 H_UVLO3 0 "False" 1 "True";
VAL_ 1317 H_BDW 0 "False" 1 "True";
VAL_ 1317 H_SASC 0 "False" 1 "True";
VAL_ 1317 H_DTW 0 "False" 1 "True";
VAL_ 1317 H_STPKW 0 "False" 1 "True";
VAL_ 1317 H_OSME 0 "False" 1 "True";
VAL_ 1317 H_GME 0 "False" 1 "True";
VAL_ 1317 H_DDE 0 "False" 1 "True";
VAL_ 1317 H_NDBISTW 0 "False" 1 "True";
VAL_ 1317 H_SASCAW 0 "False" 1 "True";
VAL_ 1317 L_NLSE 0 "False" 1 "True";
VAL_ 1317 L_OVLO2 0 "False" 1 "True";
VAL_ 1317 L_UVLO2 0 "False" 1 "True";
VAL_ 1317 L_OVLO3 0 "False" 1 "True";
VAL_ 1317 L_UVLO3 0 "False" 1 "True";
VAL_ 1317 L_BDW 0 "False" 1 "True";
VAL_ 1317 L_SASC 0 "False" 1 "True";
VAL_ 1317 L_DTW 0 "False" 1 "True";
VAL_ 1317 L_STPKW 0 "False" 1 "True";
VAL_ 1317 L_OSME 0 "False" 1 "True";
VAL_ 1317 L_GME 0 "False" 1 "True";
VAL_ 1317 L_DDE 0 "False" 1 "True";
VAL_ 1317 L_NDBISTW 0 "False" 1 "True";
VAL_ 1317 L_SASCAW 0 "False" 1 "True";
VAL_ 1318 H_NLSE 0 "False" 1 "True";
VAL_ 1318 H_OVLO2 0 "False" 1 "True";
VAL_ 1318 H_UVLO2 0 "False" 1 "True";
VAL_ 1318 H_OVLO3 0 "False" 1 "True";
VAL_ 1318 H_UVLO3 0 "False" 1 "True";
VAL_ 1318 H_BDW 0 "False" 1 "True";
VAL_ 1318 H_SASC 0 "False" 1 "True";
VAL_ 1318 H_DTW 0 "False" 1 "True";
VAL_ 1318 H_STPKW 0 "False" 1 "True";
VAL_ 1318 H_OSME 0 "False" 1 "True";
VAL_ 1318 H_GME 0 "False" 1 "True";
VAL_ 1318 H_DDE 0 "False" 1 "True";
VAL_ 1318 H_NDBISTW 0 "False" 1 "True";
VAL_ 1318 H_SASCAW 0 "False" 1 "True";
VAL_ 1318 L_NLSE 0 "False" 1 "True";
VAL_ 1318 L_OVLO2 0 "False" 1 "True";
VAL_ 1318 L_UVLO2 0 "False" 1 "True";
VAL_ 1318 L_OVLO3 0 "False" 1 "True";
VAL_ 1318 L_UVLO3 0 "False" 1 "True";
VAL_ 1318 L_BDW 0 "False" 1 "True";
VAL_ 1318 L_SASC 0 "False" 1 "True";
VAL_ 1318 L_DTW 0 "False" 1 "True";
VAL_ 1318 L_STPKW 0 "False" 1 "True";
VAL_ 1318 L_OSME 0 "False" 1 "True";
VAL_ 1318 L_GME 0 "False" 1 "True";
VAL_ 1318 L_DDE 0 "False" 1 "True";
VAL_ 1318 L_NDBISTW 0 "False" 1 "True";
VAL_ 1318 L_SASCAW 0 "False" 1 "True";
VAL_ 1333 DIRECTION 0 "CW" 1 "CCW";
VAL_ 1333 MODE 0 "TORQUE" 1 "SPEED" 2 "TEST";
SIG_VALTYPE_ 644 CUR_LOOP_ID_KP : 1;
SIG_VALTYPE_ 644 CUR_LOOP_ID_KI : 1;
SIG_VALTYPE_ 644 CUR_LOOP_IQ_KP : 1;
SIG_VALTYPE_ 644 CUR_LOOP_IQ_KI : 1;
SIG_VALTYPE_ 644 SPD_LOOP_KP : 1;
SIG_VALTYPE_ 644 SPD_LOOP_KI : 1;
SIG_VALTYPE_ 644 FW_KI : 1;
SIG_VALTYPE_ 645 CUR_LOOP_ID_KP : 1;
SIG_VALTYPE_ 645 CUR_LOOP_ID_KI : 1;
SIG_VALTYPE_ 645 CUR_LOOP_IQ_KP : 1;
SIG_VALTYPE_ 645 CUR_LOOP_IQ_KI : 1;
SIG_VALTYPE_ 645 SPD_LOOP_KP : 1;
SIG_VALTYPE_ 645 SPD_LOOP_KI : 1;
SIG_VALTYPE_ 645 FW_KI : 1;
SIG_VALTYPE_ 646 CUR_LOOP_ID_KP : 1;
SIG_VALTYPE_ 646 CUR_LOOP_ID_KI : 1;
SIG_VALTYPE_ 646 CUR_LOOP_IQ_KP : 1;
SIG_VALTYPE_ 646 CUR_LOOP_IQ_KI : 1;
SIG_VALTYPE_ 646 SPD_LOOP_KP : 1;
SIG_VALTYPE_ 646 SPD_LOOP_KI : 1;
SIG_VALTYPE_ 646 FW_KI : 1;
SIG_VALTYPE_ 647 CUR_LOOP_ID_KP : 1;
SIG_VALTYPE_ 647 CUR_LOOP_ID_KI : 1;
SIG_VALTYPE_ 647 CUR_LOOP_IQ_KP : 1;
SIG_VALTYPE_ 647 CUR_LOOP_IQ_KI : 1;
SIG_VALTYPE_ 647 SPD_LOOP_KP : 1;
SIG_VALTYPE_ 647 SPD_LOOP_KI : 1;
SIG_VALTYPE_ 647 FW_KI : 1;
SIG_VALTYPE_ 648 CURRENT_LINE_LIMIT : 1;
SIG_VALTYPE_ 648 CURRENT_ID_LIMIT : 1;
SIG_VALTYPE_ 648 FW_ID_LIMIT : 1;
SIG_VALTYPE_ 648 TORQUE_LIMIT : 1;
SIG_VALTYPE_ 648 OVER_VOLTAGE_LIMIT : 1;
SIG_VALTYPE_ 648 UNDER_VOLTAGE_LIMIT : 1;
SIG_VALTYPE_ 648 VDC_REGEN_BLOCK_SOFT : 1;
SIG_VALTYPE_ 648 VDC_REGEN_BLOCK_HARD : 1;
SIG_VALTYPE_ 648 MOTOR_TEMP_LIMIT : 1;
SIG_VALTYPE_ 648 GATE_TEMP_LIMIT : 1;
SIG_VALTYPE_ 648 VQ_LIMIT : 1;
SIG_VALTYPE_ 648 MODULATION_LIMIT : 1;
SIG_VALTYPE_ 649 CURRENT_LINE_LIMIT : 1;
SIG_VALTYPE_ 649 CURRENT_ID_LIMIT : 1;
SIG_VALTYPE_ 649 FW_ID_LIMIT : 1;
SIG_VALTYPE_ 649 TORQUE_LIMIT : 1;
SIG_VALTYPE_ 649 OVER_VOLTAGE_LIMIT : 1;
SIG_VALTYPE_ 649 UNDER_VOLTAGE_LIMIT : 1;
SIG_VALTYPE_ 649 VDC_REGEN_BLOCK_SOFT : 1;
SIG_VALTYPE_ 649 VDC_REGEN_BLOCK_HARD : 1;
SIG_VALTYPE_ 649 MOTOR_TEMP_LIMIT : 1;
SIG_VALTYPE_ 649 GATE_TEMP_LIMIT : 1;
SIG_VALTYPE_ 649 VQ_LIMIT : 1;
SIG_VALTYPE_ 649 MODULATION_LIMIT : 1;
SIG_VALTYPE_ 650 CURRENT_LINE_LIMIT : 1;
SIG_VALTYPE_ 650 CURRENT_ID_LIMIT : 1;
SIG_VALTYPE_ 650 FW_ID_LIMIT : 1;
SIG_VALTYPE_ 650 TORQUE_LIMIT : 1;
SIG_VALTYPE_ 650 OVER_VOLTAGE_LIMIT : 1;
SIG_VALTYPE_ 650 UNDER_VOLTAGE_LIMIT : 1;
SIG_VALTYPE_ 650 VDC_REGEN_BLOCK_SOFT : 1;
SIG_VALTYPE_ 650 VDC_REGEN_BLOCK_HARD : 1;
SIG_VALTYPE_ 650 MOTOR_TEMP_LIMIT : 1;
SIG_VALTYPE_ 650 GATE_TEMP_LIMIT : 1;
SIG_VALTYPE_ 650 VQ_LIMIT : 1;
SIG_VALTYPE_ 650 MODULATION_LIMIT : 1;
SIG_VALTYPE_ 651 CURRENT_LINE_LIMIT : 1;
SIG_VALTYPE_ 651 CURRENT_ID_LIMIT : 1;
SIG_VALTYPE_ 651 FW_ID_LIMIT : 1;
SIG_VALTYPE_ 651 TORQUE_LIMIT : 1;
SIG_VALTYPE_ 651 OVER_VOLTAGE_LIMIT : 1;
SIG_VALTYPE_ 651 UNDER_VOLTAGE_LIMIT : 1;
SIG_VALTYPE_ 651 VDC_REGEN_BLOCK_SOFT : 1;
SIG_VALTYPE_ 651 VDC_REGEN_BLOCK_HARD : 1;
SIG_VALTYPE_ 651 MOTOR_TEMP_LIMIT : 1;
SIG_VALTYPE_ 651 GATE_TEMP_LIMIT : 1;
SIG_VALTYPE_ 651 VQ_LIMIT : 1;
SIG_VALTYPE_ 651 MODULATION_LIMIT : 1;
SIG_VALTYPE_ 652 VDC_OFFSET : 1;
SIG_VALTYPE_ 652 MOTOR_TEMP_OFFSET : 1;
SIG_VALTYPE_ 652 U_PHASE_TEMP_OFFSET : 1;
SIG_VALTYPE_ 652 V_PHASE_TEMP_OFFSET : 1;
SIG_VALTYPE_ 652 W_PHASE_TEMP_OFFSET : 1;
SIG_VALTYPE_ 653 VDC_OFFSET : 1;
SIG_VALTYPE_ 653 MOTOR_TEMP_OFFSET : 1;
SIG_VALTYPE_ 653 U_PHASE_TEMP_OFFSET : 1;
SIG_VALTYPE_ 653 V_PHASE_TEMP_OFFSET : 1;
SIG_VALTYPE_ 653 W_PHASE_TEMP_OFFSET : 1;
SIG_VALTYPE_ 654 VDC_OFFSET : 1;
SIG_VALTYPE_ 654 MOTOR_TEMP_OFFSET : 1;
SIG_VALTYPE_ 654 U_PHASE_TEMP_OFFSET : 1;
SIG_VALTYPE_ 654 V_PHASE_TEMP_OFFSET : 1;
SIG_VALTYPE_ 654 W_PHASE_TEMP_OFFSET : 1;
SIG_VALTYPE_ 655 VDC_OFFSET : 1;
SIG_VALTYPE_ 655 MOTOR_TEMP_OFFSET : 1;
SIG_VALTYPE_ 655 U_PHASE_TEMP_OFFSET : 1;
SIG_VALTYPE_ 655 V_PHASE_TEMP_OFFSET : 1;
SIG_VALTYPE_ 655 W_PHASE_TEMP_OFFSET : 1;
SIG_VALTYPE_ 660 TORQUE_SLEW_POS_NM_PER_S : 1;
SIG_VALTYPE_ 660 TORQUE_SLEW_NEG_NM_PER_S : 1;
SIG_VALTYPE_ 660 SPEED_SLEW_POS_RPM_PER_S : 1;
SIG_VALTYPE_ 660 SPEED_SLEW_NEG_RPM_PER_S : 1;
SIG_VALTYPE_ 660 ID_MTPA_ATTACK_SLEW_A_PER_S : 1;
SIG_VALTYPE_ 660 ID_MTPA_RELEASE_SLEW_A_PER_S : 1;
SIG_VALTYPE_ 660 ID_FW_ATTACK_SLEW_A_PER_S : 1;
SIG_VALTYPE_ 660 ID_FW_RELEASE_SLEW_A_PER_S : 1;
SIG_VALTYPE_ 661 TORQUE_SLEW_POS_NM_PER_S : 1;
SIG_VALTYPE_ 661 TORQUE_SLEW_NEG_NM_PER_S : 1;
SIG_VALTYPE_ 661 SPEED_SLEW_POS_RPM_PER_S : 1;
SIG_VALTYPE_ 661 SPEED_SLEW_NEG_RPM_PER_S : 1;
SIG_VALTYPE_ 661 ID_MTPA_ATTACK_SLEW_A_PER_S : 1;
SIG_VALTYPE_ 661 ID_MTPA_RELEASE_SLEW_A_PER_S : 1;
SIG_VALTYPE_ 661 ID_FW_ATTACK_SLEW_A_PER_S : 1;
SIG_VALTYPE_ 661 ID_FW_RELEASE_SLEW_A_PER_S : 1;
SIG_VALTYPE_ 662 TORQUE_SLEW_POS_NM_PER_S : 1;
SIG_VALTYPE_ 662 TORQUE_SLEW_NEG_NM_PER_S : 1;
SIG_VALTYPE_ 662 SPEED_SLEW_POS_RPM_PER_S : 1;
SIG_VALTYPE_ 662 SPEED_SLEW_NEG_RPM_PER_S : 1;
SIG_VALTYPE_ 662 ID_MTPA_ATTACK_SLEW_A_PER_S : 1;
SIG_VALTYPE_ 662 ID_MTPA_RELEASE_SLEW_A_PER_S : 1;
SIG_VALTYPE_ 662 ID_FW_ATTACK_SLEW_A_PER_S : 1;
SIG_VALTYPE_ 662 ID_FW_RELEASE_SLEW_A_PER_S : 1;
SIG_VALTYPE_ 663 TORQUE_SLEW_POS_NM_PER_S : 1;
SIG_VALTYPE_ 663 TORQUE_SLEW_NEG_NM_PER_S : 1;
SIG_VALTYPE_ 663 SPEED_SLEW_POS_RPM_PER_S : 1;
SIG_VALTYPE_ 663 SPEED_SLEW_NEG_RPM_PER_S : 1;
SIG_VALTYPE_ 663 ID_MTPA_ATTACK_SLEW_A_PER_S : 1;
SIG_VALTYPE_ 663 ID_MTPA_RELEASE_SLEW_A_PER_S : 1;
SIG_VALTYPE_ 663 ID_FW_ATTACK_SLEW_A_PER_S : 1;
SIG_VALTYPE_ 663 ID_FW_RELEASE_SLEW_A_PER_S : 1;
SIG_VALTYPE_ 1077 QUATERNION_Q0 : 1;
SIG_VALTYPE_ 1077 QUATERNION_Q1 : 1;
SIG_VALTYPE_ 1077 QUATERNION_Q2 : 1;
SIG_VALTYPE_ 1077 QUATERNION_Q3 : 1;
SIG_VALTYPE_ 1079 ACCELERATION_AX : 1;
SIG_VALTYPE_ 1079 ACCELERATION_AY : 1;
SIG_VALTYPE_ 1079 ACCELERATION_AZ : 1;
SIG_VALTYPE_ 1080 RATE_OF_TURN_GX : 1;
SIG_VALTYPE_ 1080 RATE_OF_TURN_GY : 1;
SIG_VALTYPE_ 1080 RATE_OF_TURN_GZ : 1;
SIG_VALTYPE_ 1082 LATITUDE : 1;
SIG_VALTYPE_ 1082 LONGTITUDE : 1;
SIG_VALTYPE_ 1088 PACK_POWER : 1;
SIG_VALTYPE_ 1089 CHARGE_CURRENT_LIMIT : 1;
SIG_VALTYPE_ 1089 CHARGE_POWER_LIMIT : 1;
SIG_VALTYPE_ 1089 DISCHARGE_CURRENT_LIMIT : 1;
SIG_VALTYPE_ 1089 DISCHARGE_POWER_LIMIT : 1;
SIG_VALTYPE_ 1237 CUR_LOOP_ID_KP : 1;
SIG_VALTYPE_ 1237 CUR_LOOP_ID_KI : 1;
SIG_VALTYPE_ 1237 CUR_LOOP_IQ_KP : 1;
SIG_VALTYPE_ 1237 CUR_LOOP_IQ_KI : 1;
SIG_VALTYPE_ 1237 SPD_LOOP_KP : 1;
SIG_VALTYPE_ 1237 SPD_LOOP_KI : 1;
SIG_VALTYPE_ 1237 FW_KI : 1;
SIG_VALTYPE_ 1238 CURRENT_LINE_LIMIT : 1;
SIG_VALTYPE_ 1238 CURRENT_ID_LIMIT : 1;
SIG_VALTYPE_ 1238 TORQUE_LIMIT : 1;
SIG_VALTYPE_ 1238 OVER_VOLTAGE_LIMIT : 1;
SIG_VALTYPE_ 1238 UNDER_VOLTAGE_LIMIT : 1;
SIG_VALTYPE_ 1238 VDC_REGEN_BLOCK_SOFT : 1;
SIG_VALTYPE_ 1238 VDC_REGEN_BLOCK_HARD : 1;
SIG_VALTYPE_ 1238 MOTOR_TEMP_LIMIT : 1;
SIG_VALTYPE_ 1238 GATE_TEMP_LIMIT : 1;
SIG_VALTYPE_ 1238 VQ_LIMIT : 1;
SIG_VALTYPE_ 1238 MODULATION_LIMIT : 1;
SIG_VALTYPE_ 1239 VDC_OFFSET : 1;
SIG_VALTYPE_ 1239 MOTOR_TEMP_OFFSET : 1;
SIG_VALTYPE_ 1239 U_PHASE_TEMP_OFFSET : 1;
SIG_VALTYPE_ 1239 V_PHASE_TEMP_OFFSET : 1;
SIG_VALTYPE_ 1239 W_PHASE_TEMP_OFFSET : 1;
SIG_VALTYPE_ 1240 TORQUE_SLEW_POS_NM_PER_S : 1;
SIG_VALTYPE_ 1240 TORQUE_SLEW_NEG_NM_PER_S : 1;
SIG_VALTYPE_ 1240 SPEED_SLEW_POS_RPM_PER_S : 1;
SIG_VALTYPE_ 1240 SPEED_SLEW_NEG_RPM_PER_S : 1;
SIG_VALTYPE_ 1269 CUR_LOOP_ID_KP : 1;
SIG_VALTYPE_ 1269 CUR_LOOP_ID_KI : 1;
SIG_VALTYPE_ 1269 CUR_LOOP_IQ_KP : 1;
SIG_VALTYPE_ 1269 CUR_LOOP_IQ_KI : 1;
SIG_VALTYPE_ 1269 SPD_LOOP_KP : 1;
SIG_VALTYPE_ 1269 SPD_LOOP_KI : 1;
SIG_VALTYPE_ 1269 FW_KI : 1;
SIG_VALTYPE_ 1270 CURRENT_LINE_LIMIT : 1;
SIG_VALTYPE_ 1270 CURRENT_ID_LIMIT : 1;
SIG_VALTYPE_ 1270 TORQUE_LIMIT : 1;
SIG_VALTYPE_ 1270 OVER_VOLTAGE_LIMIT : 1;
SIG_VALTYPE_ 1270 UNDER_VOLTAGE_LIMIT : 1;
SIG_VALTYPE_ 1270 VDC_REGEN_BLOCK_SOFT : 1;
SIG_VALTYPE_ 1270 VDC_REGEN_BLOCK_HARD : 1;
SIG_VALTYPE_ 1270 MOTOR_TEMP_LIMIT : 1;
SIG_VALTYPE_ 1270 GATE_TEMP_LIMIT : 1;
SIG_VALTYPE_ 1270 VQ_LIMIT : 1;
SIG_VALTYPE_ 1270 MODULATION_LIMIT : 1;
SIG_VALTYPE_ 1271 VDC_OFFSET : 1;
SIG_VALTYPE_ 1271 MOTOR_TEMP_OFFSET : 1;
SIG_VALTYPE_ 1271 U_PHASE_TEMP_OFFSET : 1;
SIG_VALTYPE_ 1271 V_PHASE_TEMP_OFFSET : 1;
SIG_VALTYPE_ 1271 W_PHASE_TEMP_OFFSET : 1;
SIG_VALTYPE_ 1272 TORQUE_SLEW_POS_NM_PER_S : 1;
SIG_VALTYPE_ 1272 TORQUE_SLEW_NEG_NM_PER_S : 1;
SIG_VALTYPE_ 1272 SPEED_SLEW_POS_RPM_PER_S : 1;
SIG_VALTYPE_ 1272 SPEED_SLEW_NEG_RPM_PER_S : 1;
SIG_VALTYPE_ 1301 CUR_LOOP_ID_KP : 1;
SIG_VALTYPE_ 1301 CUR_LOOP_ID_KI : 1;
SIG_VALTYPE_ 1301 CUR_LOOP_IQ_KP : 1;
SIG_VALTYPE_ 1301 CUR_LOOP_IQ_KI : 1;
SIG_VALTYPE_ 1301 SPD_LOOP_KP : 1;
SIG_VALTYPE_ 1301 SPD_LOOP_KI : 1;
SIG_VALTYPE_ 1301 FW_KI : 1;
SIG_VALTYPE_ 1302 CURRENT_LINE_LIMIT : 1;
SIG_VALTYPE_ 1302 CURRENT_ID_LIMIT : 1;
SIG_VALTYPE_ 1302 TORQUE_LIMIT : 1;
SIG_VALTYPE_ 1302 OVER_VOLTAGE_LIMIT : 1;
SIG_VALTYPE_ 1302 UNDER_VOLTAGE_LIMIT : 1;
SIG_VALTYPE_ 1302 VDC_REGEN_BLOCK_SOFT : 1;
SIG_VALTYPE_ 1302 VDC_REGEN_BLOCK_HARD : 1;
SIG_VALTYPE_ 1302 MOTOR_TEMP_LIMIT : 1;
SIG_VALTYPE_ 1302 GATE_TEMP_LIMIT : 1;
SIG_VALTYPE_ 1302 VQ_LIMIT : 1;
SIG_VALTYPE_ 1302 MODULATION_LIMIT : 1;
SIG_VALTYPE_ 1303 VDC_OFFSET : 1;
SIG_VALTYPE_ 1303 MOTOR_TEMP_OFFSET : 1;
SIG_VALTYPE_ 1303 U_PHASE_TEMP_OFFSET : 1;
SIG_VALTYPE_ 1303 V_PHASE_TEMP_OFFSET : 1;
SIG_VALTYPE_ 1303 W_PHASE_TEMP_OFFSET : 1;
SIG_VALTYPE_ 1304 TORQUE_SLEW_POS_NM_PER_S : 1;
SIG_VALTYPE_ 1304 TORQUE_SLEW_NEG_NM_PER_S : 1;
SIG_VALTYPE_ 1304 SPEED_SLEW_POS_RPM_PER_S : 1;
SIG_VALTYPE_ 1304 SPEED_SLEW_NEG_RPM_PER_S : 1;
SIG_VALTYPE_ 1333 CUR_LOOP_ID_KP : 1;
SIG_VALTYPE_ 1333 CUR_LOOP_ID_KI : 1;
SIG_VALTYPE_ 1333 CUR_LOOP_IQ_KP : 1;
SIG_VALTYPE_ 1333 CUR_LOOP_IQ_KI : 1;
SIG_VALTYPE_ 1333 SPD_LOOP_KP : 1;
SIG_VALTYPE_ 1333 SPD_LOOP_KI : 1;
SIG_VALTYPE_ 1333 FW_KI : 1;
SIG_VALTYPE_ 1334 CURRENT_LINE_LIMIT : 1;
SIG_VALTYPE_ 1334 CURRENT_ID_LIMIT : 1;
SIG_VALTYPE_ 1334 TORQUE_LIMIT : 1;
SIG_VALTYPE_ 1334 OVER_VOLTAGE_LIMIT : 1;
SIG_VALTYPE_ 1334 UNDER_VOLTAGE_LIMIT : 1;
SIG_VALTYPE_ 1334 VDC_REGEN_BLOCK_SOFT : 1;
SIG_VALTYPE_ 1334 VDC_REGEN_BLOCK_HARD : 1;
SIG_VALTYPE_ 1334 MOTOR_TEMP_LIMIT : 1;
SIG_VALTYPE_ 1334 GATE_TEMP_LIMIT : 1;
SIG_VALTYPE_ 1334 VQ_LIMIT : 1;
SIG_VALTYPE_ 1334 MODULATION_LIMIT : 1;
SIG_VALTYPE_ 1335 VDC_OFFSET : 1;
SIG_VALTYPE_ 1335 MOTOR_TEMP_OFFSET : 1;
SIG_VALTYPE_ 1335 U_PHASE_TEMP_OFFSET : 1;
SIG_VALTYPE_ 1335 V_PHASE_TEMP_OFFSET : 1;
SIG_VALTYPE_ 1335 W_PHASE_TEMP_OFFSET : 1;
SIG_VALTYPE_ 1336 TORQUE_SLEW_POS_NM_PER_S : 1;
SIG_VALTYPE_ 1336 TORQUE_SLEW_NEG_NM_PER_S : 1;
SIG_VALTYPE_ 1336 SPEED_SLEW_POS_RPM_PER_S : 1;
SIG_VALTYPE_ 1336 SPEED_SLEW_NEG_RPM_PER_S : 1;
